VERSION ""

NS_ :

BS_:

BU_: RSM HVAC_RCCM GENERIC_GWMWakeup TRM GWM_ECG _delete RTM PDM SCMH SCMG DDM RBM DSM SCME TSTR

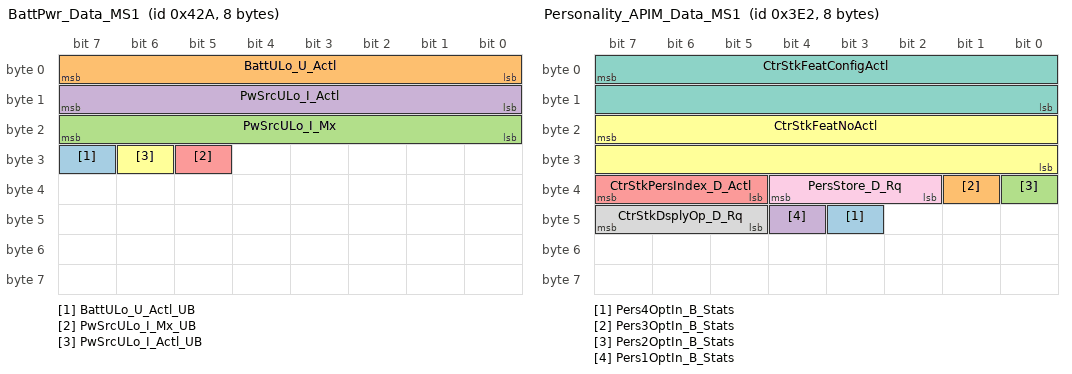
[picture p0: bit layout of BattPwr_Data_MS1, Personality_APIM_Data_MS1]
BO_ 1066 BattPwr_Data_MS1: 8 GWM_ECG
 SG_ BattULo_U_Actl_UB : 31|1@0+ (1,0) [0|1] "SED"  HVAC_RCCM
 SG_ BattULo_U_Actl : 7|8@0+ (0.0625,0) [0|15.875] "volt"  HVAC_RCCM
 SG_ PwSrcULo_I_Mx : 23|8@0+ (1,0) [0|254] "ampere"  HVAC_RCCM
 SG_ PwSrcULo_I_Actl : 15|8@0+ (1,0) [0|254] "ampere"  HVAC_RCCM
 SG_ PwSrcULo_I_Mx_UB : 29|1@0+ (1,0) [0|1] "SED"  HVAC_RCCM
 SG_ PwSrcULo_I_Actl_UB : 30|1@0+ (1,0) [0|1] "SED"  HVAC_RCCM

BO_ 994 Personality_APIM_Data_MS1: 8 GWM_ECG
 SG_ Pers4OptIn_B_Stats : 43|1@0+ (1,0) [0|1] "SED" Vector__XXX
 SG_ Pers3OptIn_B_Stats : 33|1@0+ (1,0) [0|1] "SED" Vector__XXX
 SG_ Pers2OptIn_B_Stats : 32|1@0+ (1,0) [0|1] "SED" Vector__XXX
 SG_ Pers1OptIn_B_Stats : 44|1@0+ (1,0) [0|1] "SED" Vector__XXX
 SG_ CtrStkPersIndex_D_Actl : 39|3@0+ (1,0) [0|7] "SED"  HVAC_RCCM,PDM,DDM,DSM,SCMG,SCMH
 SG_ CtrStkFeatNoActl : 23|16@0+ (1,0) [0|65535] "Undefined"  HVAC_RCCM,PDM,DDM,DSM
 SG_ CtrStkFeatConfigActl : 7|16@0+ (1,0) [0|65535] "Undefined"  HVAC_RCCM,PDM,DDM,DSM
 SG_ CtrStkDsplyOp_D_Rq : 47|3@0+ (1,0) [0|7] "SED"  HVAC_RCCM,PDM,DDM,DSM,SCMG,SCMH
 SG_ PersStore_D_Rq : 36|3@0+ (1,0) [0|7] "SED"  DSM

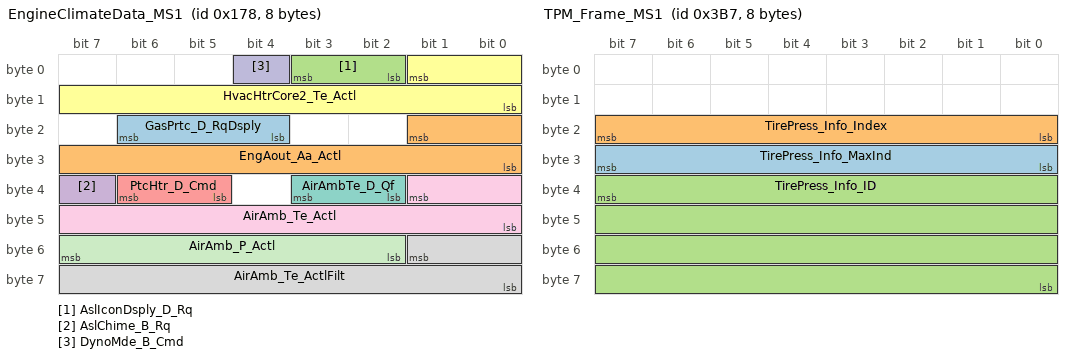
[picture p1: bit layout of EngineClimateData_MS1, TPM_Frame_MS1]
BO_ 376 EngineClimateData_MS1: 8 GWM_ECG
 SG_ GasPrtc_D_RqDsply : 22|3@0+ (1,0) [0|7] "SED" Vector__XXX
 SG_ EngAout_Aa_Actl : 17|10@0+ (0.05,-25.6) [-25.6|25.55] "rpm/ms" Vector__XXX
 SG_ AslIconDsply_D_Rq : 3|2@0+ (1,0) [0|3] "SED" Vector__XXX
 SG_ AslChime_B_Rq : 39|1@0+ (1,0) [0|1] "SED" Vector__XXX
 SG_ PtcHtr_D_Cmd : 38|2@0+ (1,0) [0|3] "SED" Vector__XXX
 SG_ HvacHtrCore2_Te_Actl : 1|10@0+ (0.25,-50) [-50|205.5] "degC"  HVAC_RCCM
 SG_ AirAmbTe_D_Qf : 35|2@0+ (1,0) [0|3] "SED"  HVAC_RCCM
 SG_ AirAmb_Te_ActlFilt : 49|10@0+ (0.25,-128) [-128|127.75] "deg C"  HVAC_RCCM
 SG_ AirAmb_Te_Actl : 33|10@0+ (0.25,-128) [-128|127.75] "degC"  HVAC_RCCM
 SG_ DynoMde_B_Cmd : 4|1@0+ (1,0) [0|1] "SED" Vector__XXX
 SG_ AirAmb_P_Actl : 55|6@0+ (10,500) [500|1110] "mbar" Vector__XXX

BO_ 951 TPM_Frame_MS1: 8 GWM_ECG
 SG_ TirePress_Info_MaxInd : 31|8@0+ (1,0) [0|255] "Unitless"  RTM
 SG_ TirePress_Info_Index : 23|8@0+ (1,0) [0|255] "Unitless"  RTM
 SG_ TirePress_Info_ID : 39|32@0+ (1,0) [0|4294967295] "Unitless"  RTM

BO_ 1068 Batt_Mgmt_Data_MS1: 8 GWM_ECG
 SG_ HvacAirFullOut_B_Rq_UB : 60|1@0+ (1,0) [0|1] "SED"  HVAC_RCCM
 SG_ HvacAirFullOut_B_Rq : 61|1@0+ (1,0) [0|1] "SED"  HVAC_RCCM
 SG_ HvacAirFlw_B_RqBatt_UB : 62|1@0+ (1,0) [0|1] "SED" Vector__XXX
 SG_ HvacRec_D_RqMxBatt_UB : 21|1@0+ (1,0) [0|1] "SED" Vector__XXX
 SG_ HvacRec_D_RqMxBatt : 20|4@0+ (1,0) [0|15] "SED" Vector__XXX
 SG_ Batt_Lo_SoC_B_UB : 22|1@0+ (1,0) [0|1] "SED"  HVAC_RCCM,TRM
 SG_ Batt_Lo_SoC_B : 23|1@0+ (1,0) [0|1] "SED"  HVAC_RCCM,TRM
 SG_ Batt_Crit_SoC_B_UB : 14|1@0+ (1,0) [0|1] "SED"  HVAC_RCCM,TRM
 SG_ Batt_Crit_SoC_B : 15|1@0+ (1,0) [0|1] "SED"  HVAC_RCCM,TRM
 SG_ Shed_T_Eng_Off_B_UB : 12|1@0+ (1,0) [0|1] "SED"  HVAC_RCCM,TRM
 SG_ Shed_T_Eng_Off_B : 13|1@0+ (1,0) [0|1] "SED"  HVAC_RCCM,TRM
 SG_ Shed_Level_Req_UB : 8|1@0+ (1,0) [0|1] "SED"  HVAC_RCCM,DDM,PDM,TRM
 SG_ Shed_Level_Req : 11|3@0+ (1,0) [0|7] "SED"  HVAC_RCCM,DDM,PDM,TRM
 SG_ Shed_Feature_Group_ID_UB : 2|1@0+ (1,0) [0|1] "SED"  HVAC_RCCM,TRM
 SG_ Shed_Feature_Group_ID : 7|5@0+ (1,0) [0|31] "SED"  HVAC_RCCM,TRM
 SG_ Shed_Drain_Eng_Off_B_UB : 0|1@0+ (1,0) [0|1] "SED"  HVAC_RCCM,TRM
 SG_ Shed_Drain_Eng_Off_B : 1|1@0+ (1,0) [0|1] "SED"  HVAC_RCCM,TRM
 SG_ HvacAir_Flw_EstBatt_UB : 16|1@0+ (1,0) [0|1] "SED" Vector__XXX
 SG_ AirCondRec_B_Rq_UB : 44|1@0+ (1,0) [0|1] "SED"  HVAC_RCCM
 SG_ AirCondFluidHi_P_Actl_UB : 45|1@0+ (1,0) [0|1] "SED"  HVAC_RCCM
 SG_ AirCondClutch_B_Stats_UB : 43|1@0+ (1,0) [0|1] "SED"  HVAC_RCCM
 SG_ AirCondRec_B_Rq : 47|1@0+ (1,0) [0|1] "SED"  HVAC_RCCM
 SG_ AirCondFluidHi_P_Actl : 39|8@0+ (0.125,0) [0|31.625] "bar"  HVAC_RCCM
 SG_ AirCondClutch_B_Stats : 46|1@0+ (1,0) [0|1] "SED"  HVAC_RCCM

BO_ 963 BCM_Lamp_Stat_MS1: 8 GWM_ECG
 SG_ Illuminated_Entry_Stat : 63|2@0+ (1,0) [0|3] "SED" Vector__XXX
 SG_ Dr_Courtesy_Light_Stat : 49|2@0+ (1,0) [0|3] "SED" Vector__XXX
 SG_ ImpactEvntFdbck_D_Stat : 53|2@0+ (1,0) [0|3] "SED" Vector__XXX
 SG_ PudLampPsngr_D_Rq : 57|2@0+ (1,0) [0|3] "SED"  PDM
 SG_ HeadLampLoOut_B_Stat : 32|1@0+ (1,0) [0|1] "SED" Vector__XXX
 SG_ CrnrLghtRight_Pc_Rq : 47|7@0+ (1,0) [0|100] "percent" Vector__XXX
 SG_ CrnrLghtLeft_Pc_Rq : 39|7@0+ (1,0) [0|100] "percent" Vector__XXX
 SG_ HeadLghtHiFdbck_D_Stat : 55|2@0+ (1,0) [0|3] "SED" Vector__XXX
 SG_ PrkLightChime_B_Rq : 25|1@0+ (1,0) [0|1] "SED" Vector__XXX
 SG_ TrnNotInPrkChime_B_Rq : 24|1@0+ (1,0) [0|1] "SED" Vector__XXX
 SG_ HomeSafeLtChime_B_Rq : 28|1@0+ (1,0) [0|1] "SED" Vector__XXX
 SG_ StopLghtOn_B_Stat : 8|1@0+ (1,0) [0|1] "SED"  RSM,TRM
 SG_ RvrseLghtOn_B_Stat : 9|1@0+ (1,0) [0|1] "SED"  TRM
 SG_ PrkLght_D_Stat : 13|2@0+ (1,0) [0|3] "SED"  TRM
 SG_ HeadLghtSwtch_D_Stat : 15|2@0+ (1,0) [0|3] "SED" Vector__XXX
 SG_ KeyInIgnWarn_B_Cmd : 27|1@0+ (1,0) [0|1] "SED" Vector__XXX
 SG_ HeadLampLoFrOn_B_Stat : 2|1@0+ (1,0) [0|1] "SED" Vector__XXX
 SG_ HeadLampLoFlOn_B_Stat : 3|1@0+ (1,0) [0|1] "SED" Vector__XXX
 SG_ Headlamp_On_Wrning_Cmd : 29|1@0+ (1,0) [0|1] "SED" Vector__XXX
 SG_ HeadLampLoActv_B_Stat : 4|1@0+ (1,0) [0|1] "SED" Vector__XXX
 SG_ HeadLghtHiOn_B_Stat : 1|1@0+ (1,0) [0|1] "SED" Vector__XXX
 SG_ Park_Brake_Chime_Rqst : 26|1@0+ (1,0) [0|1] "SED" Vector__XXX
 SG_ BrkWarnInd_B_Rq : 20|1@0+ (1,0) [0|1] "SED" Vector__XXX
 SG_ Brk_Fluid_Lvl_Low : 31|2@0+ (1,0) [0|3] "SED" Vector__XXX
 SG_ ReducedGuard_D_Stat : 19|2@0+ (1,0) [0|3] "SED" Vector__XXX
 SG_ Courtesy_BSave_Stat : 7|2@0+ (1,0) [0|3] "SED"  DDM,PDM
 SG_ DayRnngLampOn_B_Stat : 5|1@0+ (1,0) [0|1] "SED" Vector__XXX
 SG_ PerimeterAlarmChimeRq : 0|1@0+ (1,0) [0|1] "SED" Vector__XXX
 SG_ PudLampDrv_D_Rq : 59|2@0+ (1,0) [0|3] "SED"  DDM
 SG_ Courtesy_Delay_Status : 51|2@0+ (1,0) [0|3] "SED" Vector__XXX
 SG_ Perimeter_Alarm_Status : 17|2@0+ (1,0) [0|3] "SED"  RSM
 SG_ WndwGlbl_D_Cmd : 23|3@0+ (1,0) [0|7] "SED"  DDM,PDM
 SG_ PudLamp_D_Rq : 11|2@0+ (1,0) [0|3] "SED"  DDM,PDM

BO_ 964 BodyInfo_MS1: 8 GWM_ECG
 SG_ FohEng_D_Rq_UB : 60|1@0+ (1,0) [0|1] "SED" Vector__XXX
 SG_ EcoMode_B_Stat_UB : 56|1@0+ (1,0) [0|1] "SED" Vector__XXX
 SG_ Cta_D_Rq_UB : 57|1@0+ (1,0) [0|1] "SED" Vector__XXX
 SG_ Cta_D_Rq : 59|2@0+ (1,0) [0|3] "SED" Vector__XXX
 SG_ GearRvrse_D_Actl_UB : 48|1@0+ (1,0) [0|1] "SED"  PDM,DDM
 SG_ GearRvrse_D_Actl : 51|3@0+ (1,0) [0|7] "SED"  PDM,DDM
 SG_ TurnLghtSwtch_D_Stat_UB : 52|1@0+ (1,0) [0|1] "SED" Vector__XXX
 SG_ TurnLghtSwtch_D_Stat : 54|2@0+ (1,0) [0|3] "SED" Vector__XXX
 SG_ Power_Liftgate_Mode_Cmd_UB : 6|1@0+ (1,0) [0|1] "SED" Vector__XXX
 SG_ Power_Liftgate_Mode_Cmd : 7|1@0+ (1,0) [0|1] "SED" Vector__XXX
 SG_ MetricActvTe_B_Actl_UB : 2|1@0+ (1,0) [0|1] "SED"  HVAC_RCCM
 SG_ MetricActvTe_B_Actl : 3|1@0+ (1,0) [0|1] "SED"  HVAC_RCCM
 SG_ EngClntTe_D_Qf : 22|2@0+ (1,0) [0|3] "SED"  HVAC_RCCM
 SG_ Sod_D_Rq : 1|2@0+ (1,0) [0|3] "SED" Vector__XXX
 SG_ MetricActv_B_Actl : 5|1@0+ (1,0) [0|1] "SED"  HVAC_RCCM
 SG_ EngClnt_Te_Actl : 15|8@0+ (1,-60) [-60|195] "degC"  HVAC_RCCM
 SG_ MetricActv_B_Actl_UB : 4|1@0+ (1,0) [0|1] "SED"  HVAC_RCCM
 SG_ EngClnt_Te_Actl_UB : 23|1@0+ (1,0) [0|1] "SED"  HVAC_RCCM
 SG_ OCSSensrDataUpperLim_UB : 28|1@0+ (1,0) [0|1] "SED"  HVAC_RCCM,SCMG,SCMH
 SG_ OCSSensrDataUpperLim : 47|8@0+ (1,0) [0|254] "SED"  HVAC_RCCM,SCMG,SCMH
 SG_ OCSSensrDataLowerLim_UB : 29|1@0+ (1,0) [0|1] "SED"  HVAC_RCCM,SCMG,SCMH
 SG_ PrkAid_D_Falt : 18|3@0+ (1,0) [0|7] "SED" Vector__XXX
 SG_ OCSSensrDataLowerLim : 39|8@0+ (1,0) [0|254] "SED"  HVAC_RCCM,SCMG,SCMH
 SG_ PrkAid_D_Falt_UB : 63|1@0+ (1,0) [0|1] "SED" Vector__XXX
 SG_ WiprFront_D_Stat_UB : 55|1@0+ (1,0) [0|1] "SED"  HVAC_RCCM
 SG_ WiprFront_D_Stat : 27|4@0+ (1,0) [0|15] "SED"  HVAC_RCCM
 SG_ CamraDefog_B_Req_UB : 30|1@0+ (1,0) [0|1] "SED" Vector__XXX
 SG_ Sod_D_Rq_UB : 19|1@0+ (1,0) [0|1] "SED" Vector__XXX
 SG_ CamraDefog_B_Req : 31|1@0+ (1,0) [0|1] "SED" Vector__XXX

BO_ 1843 TesterPhysicalReqHVAC_RCCM: 8 TSTR
 SG_ TesterPhysicalReqHVAC_RCCM : 7|64@0+ (1,0) [0|1.84467E+019] "unitless"  HVAC_RCCM

BO_ 1851 TesterPhysicalResHVAC_RCCM: 8 HVAC_RCCM
 SG_ TesterPhysicalResHVAC_RCCM : 7|64@0+ (1,0) [0|1.84467E+019] "unitless"  TSTR

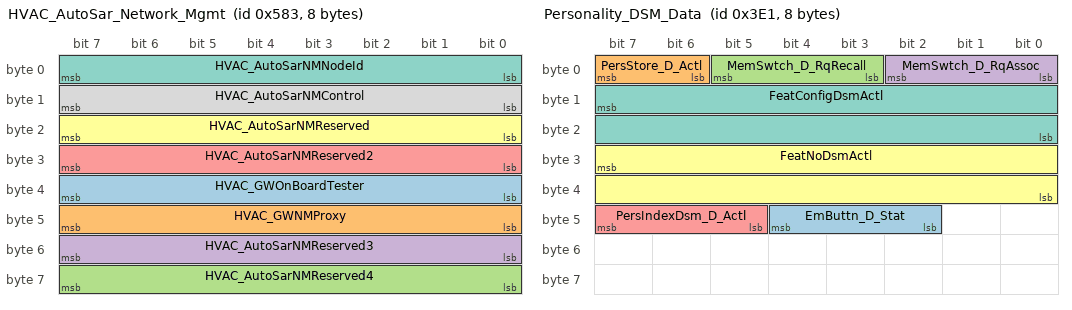
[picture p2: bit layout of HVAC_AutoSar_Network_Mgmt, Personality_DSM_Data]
BO_ 1411 HVAC_AutoSar_Network_Mgmt: 8 HVAC_RCCM
 SG_ HVAC_GWOnBoardTester : 39|8@0+ (1,0) [0|255] "unitless"  GWM_ECG
 SG_ HVAC_GWNMProxy : 47|8@0+ (1,0) [0|255] "unitless"  GWM_ECG
 SG_ HVAC_AutoSarNMReserved4 : 63|8@0+ (1,0) [0|255] "unitless"  GWM_ECG
 SG_ HVAC_AutoSarNMReserved3 : 55|8@0+ (1,0) [0|255] "unitless"  GWM_ECG
 SG_ HVAC_AutoSarNMReserved2 : 31|8@0+ (1,0) [0|255] "unitless"  GWM_ECG
 SG_ HVAC_AutoSarNMReserved : 23|8@0+ (1,0) [0|255] "unitless"  GWM_ECG
 SG_ HVAC_AutoSarNMNodeId : 7|8@0+ (1,0) [0|255] "unitless"  GWM_ECG
 SG_ HVAC_AutoSarNMControl : 15|8@0+ (1,0) [0|255] "unitless"  GWM_ECG

BO_ 993 Personality_DSM_Data: 8 DSM
 SG_ EmButtn_D_Stat : 44|3@0+ (1,0) [0|7] "SED"  GWM_ECG
 SG_ PersStore_D_Actl : 7|2@0+ (1,0) [0|3] "SED"  GWM_ECG
 SG_ MemSwtch_D_RqRecall : 5|3@0+ (1,0) [0|7] "SED"  GWM_ECG
 SG_ MemSwtch_D_RqAssoc : 2|3@0+ (1,0) [0|7] "SED"  GWM_ECG
 SG_ PersIndexDsm_D_Actl : 47|3@0+ (1,0) [0|7] "SED"  GWM_ECG
 SG_ FeatNoDsmActl : 31|16@0+ (1,0) [0|65535] "Number"  GWM_ECG
 SG_ FeatConfigDsmActl : 15|16@0+ (1,0) [0|65535] "Undefined"  GWM_ECG

BO_ 1881 TesterPhysicalResRTM: 8 RTM
 SG_ TesterPhysicalResRTM : 7|64@0+ (1,0) [0|1.84467E+019] "unitless"  TSTR

BO_ 1873 TesterPhysicalReqRTM: 8 TSTR
 SG_ TesterPhysicalReqRTM : 7|64@0+ (1,0) [0|1.84467E+019] "unitless"  RTM

BO_ 2015 TesterFunctionalReq_M1: 8 TSTR
 SG_ TesterFunctionalReq : 7|64@0+ (1,0) [0|1.84467E+019] ""  RSM,HVAC_RCCM,TSTR,PDM,SCMG,SCMH,TRM,RTM,GWM_ECG,DDM,DSM,RBM,SCME

BO_ 320 LPwrSlideDr_Stat: 8 GENERIC_GWMWakeup
 SG_ PwSldDrIntSwL_B_Stat : 6|1@0+ (1,0) [0|1] "SED"  GWM_ECG
 SG_ LPwrSlideDr_Unlock_Rq : 7|1@0+ (1,0) [0|1] "SED"  GWM_ECG

BO_ 313 RPwrSlideDr_Stat: 8 GENERIC_GWMWakeup
 SG_ PwSldDrIntSwR_B_Stat : 6|1@0+ (1,0) [0|1] "SED"  GWM_ECG
 SG_ RPwrSlideDr_Unlock_Rq : 7|1@0+ (1,0) [0|1] "SED"  GWM_ECG

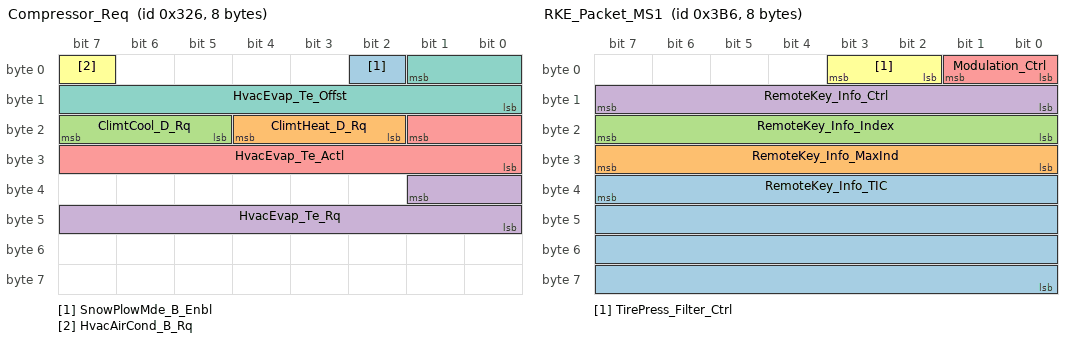
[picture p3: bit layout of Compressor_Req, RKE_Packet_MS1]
BO_ 806 Compressor_Req: 8 HVAC_RCCM
 SG_ SnowPlowMde_B_Enbl : 2|1@0+ (1,0) [0|1] "SED"  GWM_ECG,SCMG,SCMH
 SG_ ClimtHeat_D_Rq : 20|3@0+ (1,0) [0|7] "SED"  GWM_ECG
 SG_ ClimtCool_D_Rq : 23|3@0+ (1,0) [0|7] "SED"  GWM_ECG
 SG_ HvacEvap_Te_Rq : 33|10@0+ (0.125,-50) [-50|77.875] "Degrees C"  GWM_ECG
 SG_ HvacEvap_Te_Actl : 17|10@0+ (0.125,-50) [-50|77.75] "Degrees C"  GWM_ECG
 SG_ HvacAirCond_B_Rq : 7|1@0+ (1,0) [0|1] "SED"  GWM_ECG
 SG_ HvacEvap_Te_Offst : 1|10@0+ (0.125,-50) [-50|77.875] "Degrees C"  GWM_ECG

BO_ 950 RKE_Packet_MS1: 8 GWM_ECG
 SG_ RemoteKey_Info_TIC : 39|32@0+ (1,0) [0|4294967295] "Unitless"  RTM
 SG_ RemoteKey_Info_MaxInd : 31|8@0+ (1,0) [0|255] "Unitless"  RTM
 SG_ RemoteKey_Info_Index : 23|8@0+ (1,0) [0|255] "Unitless"  RTM
 SG_ RemoteKey_Info_Ctrl : 15|8@0+ (1,0) [0|255] "Unitless" Vector__XXX
 SG_ Modulation_Ctrl : 1|2@0+ (1,0) [0|3] "SED" Vector__XXX
 SG_ TirePress_Filter_Ctrl : 3|2@0+ (1,0) [0|3] "SED"  RTM

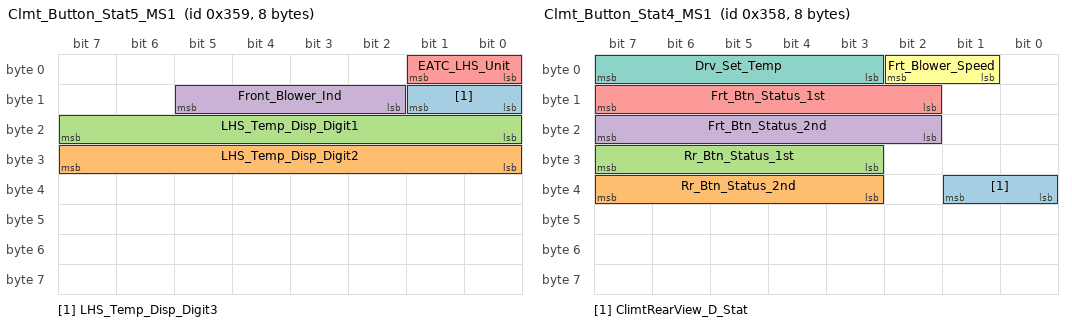
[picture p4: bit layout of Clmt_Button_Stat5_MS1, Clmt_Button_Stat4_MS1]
BO_ 857 Clmt_Button_Stat5_MS1: 8 GWM_ECG
 SG_ LHS_Temp_Disp_Digit3 : 9|2@0+ (1,0) [0|3] "SED"  HVAC_RCCM
 SG_ LHS_Temp_Disp_Digit2 : 31|8@0+ (1,0) [0|255] "ASCII"  HVAC_RCCM
 SG_ LHS_Temp_Disp_Digit1 : 23|8@0+ (1,0) [0|255] "ASCII"  HVAC_RCCM
 SG_ Front_Blower_Ind : 13|4@0+ (1,0) [0|15] "SED"  HVAC_RCCM
 SG_ EATC_LHS_Unit : 1|2@0+ (1,0) [0|3] "SED"  HVAC_RCCM

BO_ 856 Clmt_Button_Stat4_MS1: 8 GWM_ECG
 SG_ ClimtRearView_D_Stat : 33|2@0+ (1,0) [0|3] "SED" Vector__XXX
 SG_ Rr_Btn_Status_2nd : 39|5@0+ (1,0) [0|31] "SED" Vector__XXX
 SG_ Rr_Btn_Status_1st : 31|5@0+ (1,0) [0|31] "SED" Vector__XXX
 SG_ Frt_Btn_Status_2nd : 23|6@0+ (1,0) [0|63] "SED"  HVAC_RCCM
 SG_ Frt_Btn_Status_1st : 15|6@0+ (1,0) [0|63] "SED"  HVAC_RCCM
 SG_ Frt_Blower_Speed : 2|2@0+ (1,0) [0|3] "SED"  HVAC_RCCM
 SG_ Drv_Set_Temp : 7|5@0+ (1,0) [0|31] "SED"  HVAC_RCCM

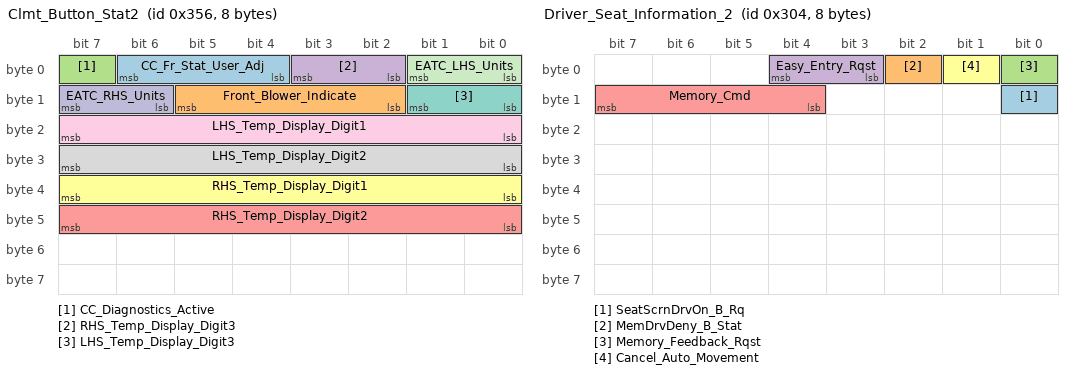
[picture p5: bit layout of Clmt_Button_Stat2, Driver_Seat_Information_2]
BO_ 854 Clmt_Button_Stat2: 8 HVAC_RCCM
 SG_ CC_Fr_Stat_User_Adj : 6|3@0+ (1,0) [0|7] "SED"  GWM_ECG
 SG_ Front_Blower_Indicate : 13|4@0+ (1,0) [0|15] "SED"  GWM_ECG
 SG_ CC_Diagnostics_Active : 7|1@0+ (1,0) [0|1] "SED"  GWM_ECG
 SG_ RHS_Temp_Display_Digit3 : 3|2@0+ (1,0) [0|3] "SED"  GWM_ECG
 SG_ RHS_Temp_Display_Digit2 : 47|8@0+ (1,0) [0|255] "ASCII"  GWM_ECG
 SG_ RHS_Temp_Display_Digit1 : 39|8@0+ (1,0) [0|255] "ASCII"  GWM_ECG
 SG_ LHS_Temp_Display_Digit3 : 9|2@0+ (1,0) [0|3] "SED"  GWM_ECG
 SG_ LHS_Temp_Display_Digit2 : 31|8@0+ (1,0) [0|255] "ASCII"  GWM_ECG
 SG_ LHS_Temp_Display_Digit1 : 23|8@0+ (1,0) [0|255] "ASCII"  GWM_ECG
 SG_ EATC_RHS_Units : 15|2@0+ (1,0) [0|3] "SED"  GWM_ECG
 SG_ EATC_LHS_Units : 1|2@0+ (1,0) [0|3] "SED"  GWM_ECG

BO_ 772 Driver_Seat_Information_2: 8 DSM
 SG_ SeatScrnDrvOn_B_Rq : 8|1@0+ (1,0) [0|1] "SED"  GWM_ECG
 SG_ MemDrvDeny_B_Stat : 2|1@0+ (1,0) [0|1] "SED"  GWM_ECG
 SG_ Memory_Feedback_Rqst : 0|1@0+ (1,0) [0|1] "SED"  GWM_ECG
 SG_ Easy_Entry_Rqst : 4|2@0+ (1,0) [0|3] "SED"  GWM_ECG,SCMH,SCMG
 SG_ Memory_Cmd : 15|4@0+ (1,0) [0|15] "SED"  GWM_ECG,SCMH,DDM,PDM,SCMG
 SG_ Cancel_Auto_Movement : 1|1@0+ (1,0) [0|1] "SED"  GWM_ECG,SCMH,PDM,DDM,SCMG

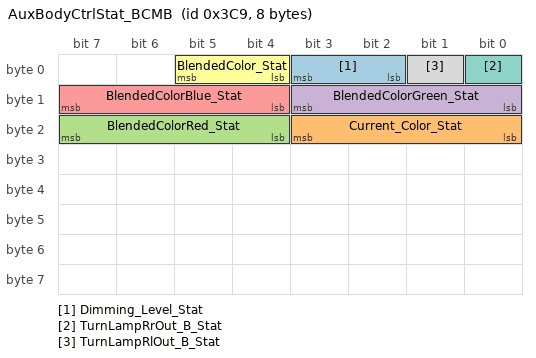
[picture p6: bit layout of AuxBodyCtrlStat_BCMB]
BO_ 969 AuxBodyCtrlStat_BCMB: 8 GENERIC_GWMWakeup
 SG_ Dimming_Level_Stat : 3|2@0+ (1,0) [0|3] "SED"  GWM_ECG
 SG_ Current_Color_Stat : 19|4@0+ (1,0) [0|15] "SED"  GWM_ECG
 SG_ BlendedColorRed_Stat : 23|4@0+ (1,0) [0|15] "SED"  GWM_ECG
 SG_ BlendedColorGreen_Stat : 11|4@0+ (1,0) [0|15] "SED"  GWM_ECG
 SG_ BlendedColorBlue_Stat : 15|4@0+ (1,0) [0|15] "SED"  GWM_ECG
 SG_ BlendedColor_Stat : 5|2@0+ (1,0) [0|3] "SED"  GWM_ECG
 SG_ TurnLampRrOut_B_Stat : 0|1@0+ (1,0) [0|1] "SED"  GWM_ECG
 SG_ TurnLampRlOut_B_Stat : 1|1@0+ (1,0) [0|1] "SED"  GWM_ECG

CM_ SG_ 376 EngAout_Aa_Actl "Signal not transmitted on HEV variants.";
CM_ SG_ 1068 AirCondRec_B_Rq "Signal not transmitted on diesel variants.";
CM_ SG_ 1068 AirCondClutch_B_Stats "Signal not transmitted on diesel variants.";
CM_ SG_ 964 GearRvrse_D_Actl "Do not implement GearRvrse_D_Actl  until eTracker 8804151 is approved, 11/24/09";
CM_ SG_ 964 MetricActv_B_Actl "0 =Inactive(English), 1=Active(Metric)";
CM_ BO_ 2015 "OBDII Request ($7DF) messages are for FNOS 1.0.1 only.
Diagnostic Functional Addressing ($7DF) and Dual Rate Periodic messages are for FNOS I3 only.";
CM_ SG_ 320 PwSldDrIntSwL_B_Stat "Signal not transmitted on vehicles without power sliding doors.";
CM_ SG_ 320 LPwrSlideDr_Unlock_Rq "Signal not transmitted on vehicles without power sliding doors.";
CM_ SG_ 313 PwSldDrIntSwR_B_Stat "Signal not transmitted on vehicles without power sliding doors.";
CM_ SG_ 313 RPwrSlideDr_Unlock_Rq "Signal not transmitted on vehicles without power sliding doors.";
CM_ SG_ 857 LHS_Temp_Disp_Digit3 "Added for MY 08";
CM_ SG_ 857 LHS_Temp_Disp_Digit2 "Added for MY 08";
CM_ SG_ 857 LHS_Temp_Disp_Digit1 "Added for MY 08";
CM_ SG_ 857 EATC_LHS_Unit "Added for MY 08";
CM_ SG_ 854 RHS_Temp_Display_Digit3 "Added for MY 08";
CM_ SG_ 854 RHS_Temp_Display_Digit2 "Added for MY 08";
CM_ SG_ 854 RHS_Temp_Display_Digit1 "Added for MY 08";
CM_ SG_ 854 LHS_Temp_Display_Digit3 "Added for MY 08";
CM_ SG_ 854 LHS_Temp_Display_Digit2 "Added for MY 08";
CM_ SG_ 854 LHS_Temp_Display_Digit1 "Added for MY 08";
CM_ SG_ 854 EATC_RHS_Units "Added for MY 08";
CM_ SG_ 854 EATC_LHS_Units "Added for MY 08";
CM_ SG_ 772 Memory_Feedback_Rqst "Updated to 1 bit for CGEA, Not backwards compatible";
CM_ SG_ 969 TurnLampRrOut_B_Stat "Signal not transmitted on vehicles without a BCMB module.";
CM_ SG_ 969 TurnLampRlOut_B_Stat "Signal not transmitted on vehicles without a BCMB module.";
BA_DEF_ BO_  "FrameGatewayNetwork" STRING ;
BA_DEF_ BO_  "FrameGatewayMS1" HEX 0 1407;
BA_DEF_ BO_  "FrameGatewayHS3" HEX 0 1407;
BA_DEF_ BO_  "FrameGatewayHS1" HEX 0 1407;
BA_DEF_ BO_  "NetworkInitialization" ENUM  "No","Yes";
BA_DEF_ BO_  "FrameGatewayId" HEX 0 1407;
BA_DEF_ BO_  "EventRateOfChange" INT 10 10000;
BA_DEF_ BO_  "GenMsgStartDelayTime" INT 0 10000;
BA_DEF_ BO_  "GenMsgNrOfRepetition" INT 0 100;
BA_DEF_ BO_  "GenMsgDelayTime" INT 0 1000;
BA_DEF_ BO_  "GenMsgCycleTime" INT 0 100000;
BA_DEF_ BO_  "GenMsgSendType" ENUM  "FixedPeriodic","Event","EnabledPeriodic","NotUsed","NotUsed","EventPeriodic","NotUsed","NotUsed","NoMsgSendType";
BA_DEF_ SG_  "U_P702_MY2021_Tx" ENUM  "No","Yes";
BA_DEF_ SG_  "U_CX727_MY2021_Tx" ENUM  "No","Yes";
BA_DEF_ SG_  "U_VN127_MY20_Tx" ENUM  "No","Yes";
BA_DEF_ SG_  "U_H567_MY20_Tx" ENUM  "No","Yes";
BA_DEF_ SG_  "U_CX430_MY2021_Tx" ENUM  "No","Yes";
BA_DEF_ SG_  "U_U611_U625_MY20_Phev_Tx" ENUM  "No","Yes";
BA_DEF_ SG_  "U_B562_MY18_Diesel_Tx" ENUM  "No","Yes";
BA_DEF_ SG_  "U_CX482_CX483_MY20_Tx" ENUM  "No","Yes";
BA_DEF_ SG_  "U_U611_U625_MY20_Hev_Tx" ENUM  "No","Yes";
BA_DEF_ SG_  "U_U611_U625_MY20_Gas_Tx" ENUM  "No","Yes";
BA_DEF_ SG_  "U_B500_MY18_Diesel_Tx" ENUM  "No","Yes";
BA_DEF_ SG_  "U_B500_MY18_Gas_Tx" ENUM  "No","Yes";
BA_DEF_ SG_  "U_C490_MY18_Tx" ENUM  "No","Yes";
BA_DEF_ SG_  "U_B562_MY18_Gas_Tx" ENUM  "No","Yes";
BA_DEF_ SG_  "U_C519_MY18_5_Gas_Tx" ENUM  "No","Yes";
BA_DEF_ SG_  "U_C519_MY18_5_Diesel_Tx" ENUM  "No","Yes";
BA_DEF_ SG_  "U_B515_MCA_MY17_Gas_Tx" ENUM  "No","Yes";
BA_DEF_ SG_  "U_B515_MCA_MY17_Diesel_Tx" ENUM  "No","Yes";
BA_DEF_ SG_  "U_B479_MY17_Diesel_Tx" ENUM  "No","Yes";
BA_DEF_ SG_  "U_B479_MY17_Gas_Tx" ENUM  "No","Yes";
BA_DEF_ SG_  "U_P702_MY2021_Rx" ENUM  "No","Yes";
BA_DEF_ SG_  "U_CX727_MY2021_Rx" ENUM  "No","Yes";
BA_DEF_ SG_  "U_VN127_MY20_Rx" ENUM  "No","Yes";
BA_DEF_ SG_  "U_H567_MY20_Rx" ENUM  "No","Yes";
BA_DEF_ SG_  "U_CX430_MY2021_Rx" ENUM  "No","Yes";
BA_DEF_ SG_  "U_U611_U625_MY20_Phev_Rx" ENUM  "No","Yes";
BA_DEF_ SG_  "U_B562_MY18_Diesel_Rx" ENUM  "No","Yes";
BA_DEF_ SG_  "U_CX482_CX483_MY20_Rx" ENUM  "No","Yes";
BA_DEF_ SG_  "U_U611_U625_MY20_Hev_Rx" ENUM  "No","Yes";
BA_DEF_ SG_  "U_U611_U625_MY20_Gas_Rx" ENUM  "No","Yes";
BA_DEF_ SG_  "U_B500_MY18_Diesel_Rx" ENUM  "No","Yes";
BA_DEF_ SG_  "U_B500_MY18_Gas_Rx" ENUM  "No","Yes";
BA_DEF_ SG_  "U_C490_MY18_Rx" ENUM  "No","Yes";
BA_DEF_ SG_  "U_B562_MY18_Gas_Rx" ENUM  "No","Yes";
BA_DEF_ SG_  "U_C519_MY18_5_Gas_Rx" ENUM  "No","Yes";
BA_DEF_ SG_  "U_C519_MY18_5_Diesel_Rx" ENUM  "No","Yes";
BA_DEF_ SG_  "U_B515_MCA_MY17_Gas_Rx" ENUM  "No","Yes";
BA_DEF_ SG_  "U_B515_MCA_MY17_Diesel_Rx" ENUM  "No","Yes";
BA_DEF_ SG_  "U_B479_MY17_Diesel_Rx" ENUM  "No","Yes";
BA_DEF_ SG_  "U_B479_MY17_Gas_Rx" ENUM  "No","Yes";
BA_DEF_ SG_  "U_B562LC_MY15_Gas_Rx" ENUM  "No","Yes";
BA_DEF_ SG_  "U_B562LC_MY15_Diesel_Rx" ENUM  "No","Yes";
BA_DEF_ SG_  "MetaData" ENUM  "No","Yes";
BA_DEF_ SG_  "ContentDependant" ENUM  "No","Yes";
BA_DEF_ SG_  "GenSigStartValue" INT 0 1000000000;
BA_DEF_ SG_  "UsedOnPgmDBC" ENUM  "No","Yes";
BA_DEF_ SG_  "CrossOver_InfoCAN" ENUM  "No","Yes";
BA_DEF_ SG_  "WakeupSignal" ENUM  "No","Yes";
BA_DEF_ SG_  "GenSigInactiveValue" INT 0 100000;
BA_DEF_ SG_  "GenSigSendType" ENUM  "Cyclic","OnWrite","vector_leerstring","OnChange","vector_leerstring","IfActive","vector_leerstring","NoSigSendType";
BA_DEF_ BO_  "AuthFreshnessCounterSyncAttempt" INT 0 2;
BA_DEF_ BO_  "GenMsgRoutingTimeoutTime" INT 0 5000;
BA_DEF_ BO_  "MessageGateway" ENUM  "No","Yes";
BA_DEF_ BO_  "NmAsrMessage" ENUM  "No","Yes";
BA_DEF_ BO_  "DiagState" ENUM  "No","Yes";
BA_DEF_ BO_  "DiagRequest" ENUM  "No","Yes";
BA_DEF_ BO_  "DiagResponse" ENUM  "No","Yes";
BA_DEF_ BO_  "NmMessage" ENUM  "No","Yes";
BA_DEF_ BO_  "GenMsgILSupport" ENUM  "No","Yes";
BA_DEF_DEF_  "FrameGatewayNetwork" "NONE";
BA_DEF_DEF_  "FrameGatewayMS1" 0;
BA_DEF_DEF_  "FrameGatewayHS3" 0;
BA_DEF_DEF_  "FrameGatewayHS1" 0;
BA_DEF_DEF_  "NetworkInitialization" "Yes";
BA_DEF_DEF_  "FrameGatewayId" 0;
BA_DEF_DEF_  "EventRateOfChange" 10000;
BA_DEF_DEF_  "GenMsgStartDelayTime" 0;
BA_DEF_DEF_  "GenMsgNrOfRepetition" 1;
BA_DEF_DEF_  "GenMsgDelayTime" 20;
BA_DEF_DEF_  "GenMsgCycleTime" 0;
BA_DEF_DEF_  "GenMsgSendType" "NoMsgSendType";
BA_DEF_DEF_  "U_P702_MY2021_Tx" "No";
BA_DEF_DEF_  "U_CX727_MY2021_Tx" "No";
BA_DEF_DEF_  "U_VN127_MY20_Tx" "No";
BA_DEF_DEF_  "U_H567_MY20_Tx" "No";
BA_DEF_DEF_  "U_CX430_MY2021_Tx" "No";
BA_DEF_DEF_  "U_U611_U625_MY20_Phev_Tx" "No";
BA_DEF_DEF_  "U_B562_MY18_Diesel_Tx" "No";
BA_DEF_DEF_  "U_CX482_CX483_MY20_Tx" "No";
BA_DEF_DEF_  "U_U611_U625_MY20_Hev_Tx" "No";
BA_DEF_DEF_  "U_U611_U625_MY20_Gas_Tx" "No";
BA_DEF_DEF_  "U_B500_MY18_Diesel_Tx" "No";
BA_DEF_DEF_  "U_B500_MY18_Gas_Tx" "No";
BA_DEF_DEF_  "U_C490_MY18_Tx" "No";
BA_DEF_DEF_  "U_B562_MY18_Gas_Tx" "No";
BA_DEF_DEF_  "U_C519_MY18_5_Gas_Tx" "No";
BA_DEF_DEF_  "U_C519_MY18_5_Diesel_Tx" "No";
BA_DEF_DEF_  "U_B515_MCA_MY17_Gas_Tx" "No";
BA_DEF_DEF_  "U_B515_MCA_MY17_Diesel_Tx" "No";
BA_DEF_DEF_  "U_B479_MY17_Diesel_Tx" "No";
BA_DEF_DEF_  "U_B479_MY17_Gas_Tx" "No";
BA_DEF_DEF_  "U_P702_MY2021_Rx" "No";
BA_DEF_DEF_  "U_CX727_MY2021_Rx" "No";
BA_DEF_DEF_  "U_VN127_MY20_Rx" "No";
BA_DEF_DEF_  "U_H567_MY20_Rx" "No";
BA_DEF_DEF_  "U_CX430_MY2021_Rx" "No";
BA_DEF_DEF_  "U_U611_U625_MY20_Phev_Rx" "No";
BA_DEF_DEF_  "U_B562_MY18_Diesel_Rx" "No";
BA_DEF_DEF_  "U_CX482_CX483_MY20_Rx" "No";
BA_DEF_DEF_  "U_U611_U625_MY20_Hev_Rx" "No";
BA_DEF_DEF_  "U_U611_U625_MY20_Gas_Rx" "No";
BA_DEF_DEF_  "U_B500_MY18_Diesel_Rx" "No";
BA_DEF_DEF_  "U_B500_MY18_Gas_Rx" "No";
BA_DEF_DEF_  "U_C490_MY18_Rx" "No";
BA_DEF_DEF_  "U_B562_MY18_Gas_Rx" "No";
BA_DEF_DEF_  "U_C519_MY18_5_Gas_Rx" "No";
BA_DEF_DEF_  "U_C519_MY18_5_Diesel_Rx" "No";
BA_DEF_DEF_  "U_B515_MCA_MY17_Gas_Rx" "No";
BA_DEF_DEF_  "U_B515_MCA_MY17_Diesel_Rx" "No";
BA_DEF_DEF_  "U_B479_MY17_Diesel_Rx" "No";
BA_DEF_DEF_  "U_B479_MY17_Gas_Rx" "No";
BA_DEF_DEF_  "U_B562LC_MY15_Gas_Rx" "No";
BA_DEF_DEF_  "U_B562LC_MY15_Diesel_Rx" "No";
BA_DEF_DEF_  "MetaData" "No";
BA_DEF_DEF_  "ContentDependant" "No";
BA_DEF_DEF_  "GenSigStartValue" 0;
BA_DEF_DEF_  "UsedOnPgmDBC" "Yes";
BA_DEF_DEF_  "CrossOver_InfoCAN" "No";
BA_DEF_DEF_  "WakeupSignal" "No";
BA_DEF_DEF_  "GenSigInactiveValue" 0;
BA_DEF_DEF_  "GenSigSendType" "NoSigSendType";
BA_DEF_DEF_  "AuthFreshnessCounterSyncAttempt" 2;
BA_DEF_DEF_  "GenMsgRoutingTimeoutTime" 0;
BA_DEF_DEF_  "MessageGateway" "No";
BA_DEF_DEF_  "NmAsrMessage" "No";
BA_DEF_DEF_  "DiagState" "No";
BA_DEF_DEF_  "DiagRequest" "No";
BA_DEF_DEF_  "DiagResponse" "No";
BA_DEF_DEF_  "NmMessage" "No";
BA_DEF_DEF_  "GenMsgILSupport" "Yes";
BA_ "GenMsgCycleTime" BO_ 1066 50;
BA_ "GenMsgSendType" BO_ 1066 0;
BA_ "FrameGatewayHS3" BO_ 994 987;
BA_ "FrameGatewayHS1" BO_ 994 994;
BA_ "FrameGatewayNetwork" BO_ 376 "FD1_CAN";
BA_ "FrameGatewayId" BO_ 376 376;
BA_ "FrameGatewayNetwork" BO_ 951 "HS1_CAN";
BA_ "FrameGatewayId" BO_ 951 951;
BA_ "GenMsgCycleTime" BO_ 1068 50;
BA_ "GenMsgSendType" BO_ 1068 0;
BA_ "FrameGatewayNetwork" BO_ 963 "HS1_CAN";
BA_ "FrameGatewayId" BO_ 963 963;
BA_ "GenMsgCycleTime" BO_ 964 200;
BA_ "GenMsgSendType" BO_ 964 5;
BA_ "NetworkInitialization" BO_ 1843 0;
BA_ "GenMsgDelayTime" BO_ 1843 0;
BA_ "GenMsgSendType" BO_ 1843 1;
BA_ "DiagRequest" BO_ 1843 1;
BA_ "GenMsgILSupport" BO_ 1843 0;
BA_ "NetworkInitialization" BO_ 1851 0;
BA_ "GenMsgDelayTime" BO_ 1851 0;
BA_ "GenMsgSendType" BO_ 1851 1;
BA_ "DiagResponse" BO_ 1851 1;
BA_ "GenMsgILSupport" BO_ 1851 0;
BA_ "NetworkInitialization" BO_ 1411 0;
BA_ "GenMsgCycleTime" BO_ 1411 1000;
BA_ "GenMsgSendType" BO_ 1411 0;
BA_ "NmAsrMessage" BO_ 1411 1;
BA_ "GenMsgILSupport" BO_ 1411 0;
BA_ "GenMsgStartDelayTime" BO_ 993 100;
BA_ "GenMsgCycleTime" BO_ 993 1000;
BA_ "GenMsgSendType" BO_ 993 5;
BA_ "NetworkInitialization" BO_ 1881 0;
BA_ "GenMsgDelayTime" BO_ 1881 0;
BA_ "GenMsgSendType" BO_ 1881 1;
BA_ "DiagResponse" BO_ 1881 1;
BA_ "GenMsgILSupport" BO_ 1881 0;
BA_ "NetworkInitialization" BO_ 1873 0;
BA_ "GenMsgDelayTime" BO_ 1873 0;
BA_ "GenMsgSendType" BO_ 1873 1;
BA_ "DiagRequest" BO_ 1873 1;
BA_ "GenMsgILSupport" BO_ 1873 0;
BA_ "NetworkInitialization" BO_ 2015 0;
BA_ "GenMsgDelayTime" BO_ 2015 0;
BA_ "GenMsgSendType" BO_ 2015 1;
BA_ "DiagState" BO_ 2015 1;
BA_ "GenMsgILSupport" BO_ 2015 0;
BA_ "GenMsgCycleTime" BO_ 806 100;
BA_ "GenMsgSendType" BO_ 806 0;
BA_ "FrameGatewayNetwork" BO_ 950 "HS1_CAN";
BA_ "FrameGatewayId" BO_ 950 950;
BA_ "FrameGatewayNetwork" BO_ 857 "HS3_CAN";
BA_ "FrameGatewayId" BO_ 857 867;
BA_ "FrameGatewayNetwork" BO_ 856 "HS3_CAN";
BA_ "FrameGatewayId" BO_ 856 866;
BA_ "GenMsgCycleTime" BO_ 854 1000;
BA_ "GenMsgSendType" BO_ 854 5;
BA_ "GenMsgCycleTime" BO_ 772 1000;
BA_ "GenMsgSendType" BO_ 772 5;
BA_ "U_P702_MY2021_Rx" SG_ 1066 BattULo_U_Actl_UB 1;
BA_ "U_CX727_MY2021_Rx" SG_ 1066 BattULo_U_Actl_UB 1;
BA_ "U_CX430_MY2021_Rx" SG_ 1066 BattULo_U_Actl_UB 1;
BA_ "U_U611_U625_MY20_Phev_Rx" SG_ 1066 BattULo_U_Actl_UB 1;
BA_ "U_B562_MY18_Diesel_Rx" SG_ 1066 BattULo_U_Actl_UB 1;
BA_ "U_CX482_CX483_MY20_Rx" SG_ 1066 BattULo_U_Actl_UB 1;
BA_ "U_U611_U625_MY20_Hev_Rx" SG_ 1066 BattULo_U_Actl_UB 1;
BA_ "U_U611_U625_MY20_Gas_Rx" SG_ 1066 BattULo_U_Actl_UB 1;
BA_ "U_B500_MY18_Diesel_Rx" SG_ 1066 BattULo_U_Actl_UB 1;
BA_ "U_B500_MY18_Gas_Rx" SG_ 1066 BattULo_U_Actl_UB 1;
BA_ "U_C490_MY18_Rx" SG_ 1066 BattULo_U_Actl_UB 1;
BA_ "U_B562_MY18_Gas_Rx" SG_ 1066 BattULo_U_Actl_UB 1;
BA_ "U_C519_MY18_5_Gas_Rx" SG_ 1066 BattULo_U_Actl_UB 1;
BA_ "U_C519_MY18_5_Diesel_Rx" SG_ 1066 BattULo_U_Actl_UB 1;
BA_ "U_B515_MCA_MY17_Gas_Rx" SG_ 1066 BattULo_U_Actl_UB 1;
BA_ "U_B515_MCA_MY17_Diesel_Rx" SG_ 1066 BattULo_U_Actl_UB 1;
BA_ "U_B479_MY17_Diesel_Rx" SG_ 1066 BattULo_U_Actl_UB 1;
BA_ "U_B479_MY17_Gas_Rx" SG_ 1066 BattULo_U_Actl_UB 1;
BA_ "U_P702_MY2021_Rx" SG_ 1066 BattULo_U_Actl 1;
BA_ "U_CX727_MY2021_Rx" SG_ 1066 BattULo_U_Actl 1;
BA_ "U_CX430_MY2021_Rx" SG_ 1066 BattULo_U_Actl 1;
BA_ "U_U611_U625_MY20_Phev_Rx" SG_ 1066 BattULo_U_Actl 1;
BA_ "U_B562_MY18_Diesel_Rx" SG_ 1066 BattULo_U_Actl 1;
BA_ "U_CX482_CX483_MY20_Rx" SG_ 1066 BattULo_U_Actl 1;
BA_ "U_U611_U625_MY20_Hev_Rx" SG_ 1066 BattULo_U_Actl 1;
BA_ "U_U611_U625_MY20_Gas_Rx" SG_ 1066 BattULo_U_Actl 1;
BA_ "U_B500_MY18_Diesel_Rx" SG_ 1066 BattULo_U_Actl 1;
BA_ "U_B500_MY18_Gas_Rx" SG_ 1066 BattULo_U_Actl 1;
BA_ "U_C490_MY18_Rx" SG_ 1066 BattULo_U_Actl 1;
BA_ "U_B562_MY18_Gas_Rx" SG_ 1066 BattULo_U_Actl 1;
BA_ "U_C519_MY18_5_Gas_Rx" SG_ 1066 BattULo_U_Actl 1;
BA_ "U_C519_MY18_5_Diesel_Rx" SG_ 1066 BattULo_U_Actl 1;
BA_ "U_B515_MCA_MY17_Gas_Rx" SG_ 1066 BattULo_U_Actl 1;
BA_ "U_B515_MCA_MY17_Diesel_Rx" SG_ 1066 BattULo_U_Actl 1;
BA_ "U_B479_MY17_Diesel_Rx" SG_ 1066 BattULo_U_Actl 1;
BA_ "U_B479_MY17_Gas_Rx" SG_ 1066 BattULo_U_Actl 1;
BA_ "GenSigStartValue" SG_ 1066 BattULo_U_Actl 255;
BA_ "U_P702_MY2021_Rx" SG_ 1066 PwSrcULo_I_Mx 1;
BA_ "U_CX727_MY2021_Rx" SG_ 1066 PwSrcULo_I_Mx 1;
BA_ "U_CX430_MY2021_Rx" SG_ 1066 PwSrcULo_I_Mx 1;
BA_ "U_U611_U625_MY20_Phev_Rx" SG_ 1066 PwSrcULo_I_Mx 1;
BA_ "U_B562_MY18_Diesel_Rx" SG_ 1066 PwSrcULo_I_Mx 1;
BA_ "U_CX482_CX483_MY20_Rx" SG_ 1066 PwSrcULo_I_Mx 1;
BA_ "U_U611_U625_MY20_Hev_Rx" SG_ 1066 PwSrcULo_I_Mx 1;
BA_ "U_U611_U625_MY20_Gas_Rx" SG_ 1066 PwSrcULo_I_Mx 1;
BA_ "U_B500_MY18_Diesel_Rx" SG_ 1066 PwSrcULo_I_Mx 1;
BA_ "U_B500_MY18_Gas_Rx" SG_ 1066 PwSrcULo_I_Mx 1;
BA_ "U_C490_MY18_Rx" SG_ 1066 PwSrcULo_I_Mx 1;
BA_ "U_B562_MY18_Gas_Rx" SG_ 1066 PwSrcULo_I_Mx 1;
BA_ "U_C519_MY18_5_Gas_Rx" SG_ 1066 PwSrcULo_I_Mx 1;
BA_ "U_C519_MY18_5_Diesel_Rx" SG_ 1066 PwSrcULo_I_Mx 1;
BA_ "U_B515_MCA_MY17_Gas_Rx" SG_ 1066 PwSrcULo_I_Mx 1;
BA_ "U_B515_MCA_MY17_Diesel_Rx" SG_ 1066 PwSrcULo_I_Mx 1;
BA_ "U_B479_MY17_Diesel_Rx" SG_ 1066 PwSrcULo_I_Mx 1;
BA_ "U_B479_MY17_Gas_Rx" SG_ 1066 PwSrcULo_I_Mx 1;
BA_ "U_P702_MY2021_Rx" SG_ 1066 PwSrcULo_I_Actl 1;
BA_ "U_CX727_MY2021_Rx" SG_ 1066 PwSrcULo_I_Actl 1;
BA_ "U_CX430_MY2021_Rx" SG_ 1066 PwSrcULo_I_Actl 1;
BA_ "U_U611_U625_MY20_Phev_Rx" SG_ 1066 PwSrcULo_I_Actl 1;
BA_ "U_B562_MY18_Diesel_Rx" SG_ 1066 PwSrcULo_I_Actl 1;
BA_ "U_CX482_CX483_MY20_Rx" SG_ 1066 PwSrcULo_I_Actl 1;
BA_ "U_U611_U625_MY20_Hev_Rx" SG_ 1066 PwSrcULo_I_Actl 1;
BA_ "U_U611_U625_MY20_Gas_Rx" SG_ 1066 PwSrcULo_I_Actl 1;
BA_ "U_B500_MY18_Diesel_Rx" SG_ 1066 PwSrcULo_I_Actl 1;
BA_ "U_B500_MY18_Gas_Rx" SG_ 1066 PwSrcULo_I_Actl 1;
BA_ "U_C490_MY18_Rx" SG_ 1066 PwSrcULo_I_Actl 1;
BA_ "U_B562_MY18_Gas_Rx" SG_ 1066 PwSrcULo_I_Actl 1;
BA_ "U_C519_MY18_5_Gas_Rx" SG_ 1066 PwSrcULo_I_Actl 1;
BA_ "U_C519_MY18_5_Diesel_Rx" SG_ 1066 PwSrcULo_I_Actl 1;
BA_ "U_B515_MCA_MY17_Gas_Rx" SG_ 1066 PwSrcULo_I_Actl 1;
BA_ "U_B515_MCA_MY17_Diesel_Rx" SG_ 1066 PwSrcULo_I_Actl 1;
BA_ "U_B479_MY17_Diesel_Rx" SG_ 1066 PwSrcULo_I_Actl 1;
BA_ "U_B479_MY17_Gas_Rx" SG_ 1066 PwSrcULo_I_Actl 1;
BA_ "U_P702_MY2021_Rx" SG_ 1066 PwSrcULo_I_Mx_UB 1;
BA_ "U_CX727_MY2021_Rx" SG_ 1066 PwSrcULo_I_Mx_UB 1;
BA_ "U_CX430_MY2021_Rx" SG_ 1066 PwSrcULo_I_Mx_UB 1;
BA_ "U_U611_U625_MY20_Phev_Rx" SG_ 1066 PwSrcULo_I_Mx_UB 1;
BA_ "U_B562_MY18_Diesel_Rx" SG_ 1066 PwSrcULo_I_Mx_UB 1;
BA_ "U_CX482_CX483_MY20_Rx" SG_ 1066 PwSrcULo_I_Mx_UB 1;
BA_ "U_U611_U625_MY20_Hev_Rx" SG_ 1066 PwSrcULo_I_Mx_UB 1;
BA_ "U_U611_U625_MY20_Gas_Rx" SG_ 1066 PwSrcULo_I_Mx_UB 1;
BA_ "U_B500_MY18_Diesel_Rx" SG_ 1066 PwSrcULo_I_Mx_UB 1;
BA_ "U_B500_MY18_Gas_Rx" SG_ 1066 PwSrcULo_I_Mx_UB 1;
BA_ "U_C490_MY18_Rx" SG_ 1066 PwSrcULo_I_Mx_UB 1;
BA_ "U_B562_MY18_Gas_Rx" SG_ 1066 PwSrcULo_I_Mx_UB 1;
BA_ "U_C519_MY18_5_Gas_Rx" SG_ 1066 PwSrcULo_I_Mx_UB 1;
BA_ "U_C519_MY18_5_Diesel_Rx" SG_ 1066 PwSrcULo_I_Mx_UB 1;
BA_ "U_B515_MCA_MY17_Gas_Rx" SG_ 1066 PwSrcULo_I_Mx_UB 1;
BA_ "U_B515_MCA_MY17_Diesel_Rx" SG_ 1066 PwSrcULo_I_Mx_UB 1;
BA_ "U_B479_MY17_Diesel_Rx" SG_ 1066 PwSrcULo_I_Mx_UB 1;
BA_ "U_B479_MY17_Gas_Rx" SG_ 1066 PwSrcULo_I_Mx_UB 1;
BA_ "U_P702_MY2021_Rx" SG_ 1066 PwSrcULo_I_Actl_UB 1;
BA_ "U_CX727_MY2021_Rx" SG_ 1066 PwSrcULo_I_Actl_UB 1;
BA_ "U_CX430_MY2021_Rx" SG_ 1066 PwSrcULo_I_Actl_UB 1;
BA_ "U_U611_U625_MY20_Phev_Rx" SG_ 1066 PwSrcULo_I_Actl_UB 1;
BA_ "U_B562_MY18_Diesel_Rx" SG_ 1066 PwSrcULo_I_Actl_UB 1;
BA_ "U_CX482_CX483_MY20_Rx" SG_ 1066 PwSrcULo_I_Actl_UB 1;
BA_ "U_U611_U625_MY20_Hev_Rx" SG_ 1066 PwSrcULo_I_Actl_UB 1;
BA_ "U_U611_U625_MY20_Gas_Rx" SG_ 1066 PwSrcULo_I_Actl_UB 1;
BA_ "U_B500_MY18_Diesel_Rx" SG_ 1066 PwSrcULo_I_Actl_UB 1;
BA_ "U_B500_MY18_Gas_Rx" SG_ 1066 PwSrcULo_I_Actl_UB 1;
BA_ "U_C490_MY18_Rx" SG_ 1066 PwSrcULo_I_Actl_UB 1;
BA_ "U_B562_MY18_Gas_Rx" SG_ 1066 PwSrcULo_I_Actl_UB 1;
BA_ "U_C519_MY18_5_Gas_Rx" SG_ 1066 PwSrcULo_I_Actl_UB 1;
BA_ "U_C519_MY18_5_Diesel_Rx" SG_ 1066 PwSrcULo_I_Actl_UB 1;
BA_ "U_B515_MCA_MY17_Gas_Rx" SG_ 1066 PwSrcULo_I_Actl_UB 1;
BA_ "U_B515_MCA_MY17_Diesel_Rx" SG_ 1066 PwSrcULo_I_Actl_UB 1;
BA_ "U_B479_MY17_Diesel_Rx" SG_ 1066 PwSrcULo_I_Actl_UB 1;
BA_ "U_B479_MY17_Gas_Rx" SG_ 1066 PwSrcULo_I_Actl_UB 1;
BA_ "CrossOver_InfoCAN" SG_ 994 Pers4OptIn_B_Stats 1;
BA_ "WakeupSignal" SG_ 994 Pers4OptIn_B_Stats 1;
BA_ "CrossOver_InfoCAN" SG_ 994 Pers3OptIn_B_Stats 1;
BA_ "WakeupSignal" SG_ 994 Pers3OptIn_B_Stats 1;
BA_ "CrossOver_InfoCAN" SG_ 994 Pers2OptIn_B_Stats 1;
BA_ "WakeupSignal" SG_ 994 Pers2OptIn_B_Stats 1;
BA_ "CrossOver_InfoCAN" SG_ 994 Pers1OptIn_B_Stats 1;
BA_ "WakeupSignal" SG_ 994 Pers1OptIn_B_Stats 1;
BA_ "U_B500_MY18_Diesel_Rx" SG_ 994 CtrStkPersIndex_D_Actl 1;
BA_ "U_B500_MY18_Gas_Rx" SG_ 994 CtrStkPersIndex_D_Actl 1;
BA_ "U_C519_MY18_5_Gas_Rx" SG_ 994 CtrStkPersIndex_D_Actl 1;
BA_ "U_C519_MY18_5_Diesel_Rx" SG_ 994 CtrStkPersIndex_D_Actl 1;
BA_ "U_B515_MCA_MY17_Gas_Rx" SG_ 994 CtrStkPersIndex_D_Actl 1;
BA_ "U_B515_MCA_MY17_Diesel_Rx" SG_ 994 CtrStkPersIndex_D_Actl 1;
BA_ "U_B479_MY17_Diesel_Rx" SG_ 994 CtrStkPersIndex_D_Actl 1;
BA_ "U_B479_MY17_Gas_Rx" SG_ 994 CtrStkPersIndex_D_Actl 1;
BA_ "U_CX727_MY2021_Rx" SG_ 994 CtrStkPersIndex_D_Actl 1;
BA_ "U_CX430_MY2021_Rx" SG_ 994 CtrStkPersIndex_D_Actl 1;
BA_ "U_P702_MY2021_Rx" SG_ 994 CtrStkPersIndex_D_Actl 1;
BA_ "U_U611_U625_MY20_Phev_Rx" SG_ 994 CtrStkPersIndex_D_Actl 1;
BA_ "U_CX482_CX483_MY20_Rx" SG_ 994 CtrStkPersIndex_D_Actl 1;
BA_ "U_U611_U625_MY20_Hev_Rx" SG_ 994 CtrStkPersIndex_D_Actl 1;
BA_ "U_U611_U625_MY20_Gas_Rx" SG_ 994 CtrStkPersIndex_D_Actl 1;
BA_ "GenSigStartValue" SG_ 994 CtrStkPersIndex_D_Actl 4;
BA_ "CrossOver_InfoCAN" SG_ 994 CtrStkPersIndex_D_Actl 1;
BA_ "U_B500_MY18_Diesel_Rx" SG_ 994 CtrStkFeatNoActl 1;
BA_ "U_B500_MY18_Gas_Rx" SG_ 994 CtrStkFeatNoActl 1;
BA_ "U_C519_MY18_5_Gas_Rx" SG_ 994 CtrStkFeatNoActl 1;
BA_ "U_C519_MY18_5_Diesel_Rx" SG_ 994 CtrStkFeatNoActl 1;
BA_ "U_B515_MCA_MY17_Gas_Rx" SG_ 994 CtrStkFeatNoActl 1;
BA_ "U_B515_MCA_MY17_Diesel_Rx" SG_ 994 CtrStkFeatNoActl 1;
BA_ "U_B479_MY17_Diesel_Rx" SG_ 994 CtrStkFeatNoActl 1;
BA_ "U_B479_MY17_Gas_Rx" SG_ 994 CtrStkFeatNoActl 1;
BA_ "U_P702_MY2021_Rx" SG_ 994 CtrStkFeatNoActl 1;
BA_ "U_CX727_MY2021_Rx" SG_ 994 CtrStkFeatNoActl 1;
BA_ "U_CX430_MY2021_Rx" SG_ 994 CtrStkFeatNoActl 1;
BA_ "U_U611_U625_MY20_Phev_Rx" SG_ 994 CtrStkFeatNoActl 1;
BA_ "U_CX482_CX483_MY20_Rx" SG_ 994 CtrStkFeatNoActl 1;
BA_ "U_U611_U625_MY20_Hev_Rx" SG_ 994 CtrStkFeatNoActl 1;
BA_ "U_U611_U625_MY20_Gas_Rx" SG_ 994 CtrStkFeatNoActl 1;
BA_ "CrossOver_InfoCAN" SG_ 994 CtrStkFeatNoActl 1;
BA_ "U_B500_MY18_Diesel_Rx" SG_ 994 CtrStkFeatConfigActl 1;
BA_ "U_B500_MY18_Gas_Rx" SG_ 994 CtrStkFeatConfigActl 1;
BA_ "U_C519_MY18_5_Gas_Rx" SG_ 994 CtrStkFeatConfigActl 1;
BA_ "U_C519_MY18_5_Diesel_Rx" SG_ 994 CtrStkFeatConfigActl 1;
BA_ "U_B515_MCA_MY17_Gas_Rx" SG_ 994 CtrStkFeatConfigActl 1;
BA_ "U_B515_MCA_MY17_Diesel_Rx" SG_ 994 CtrStkFeatConfigActl 1;
BA_ "U_B479_MY17_Diesel_Rx" SG_ 994 CtrStkFeatConfigActl 1;
BA_ "U_B479_MY17_Gas_Rx" SG_ 994 CtrStkFeatConfigActl 1;
BA_ "U_P702_MY2021_Rx" SG_ 994 CtrStkFeatConfigActl 1;
BA_ "U_CX727_MY2021_Rx" SG_ 994 CtrStkFeatConfigActl 1;
BA_ "U_CX430_MY2021_Rx" SG_ 994 CtrStkFeatConfigActl 1;
BA_ "U_U611_U625_MY20_Phev_Rx" SG_ 994 CtrStkFeatConfigActl 1;
BA_ "U_CX482_CX483_MY20_Rx" SG_ 994 CtrStkFeatConfigActl 1;
BA_ "U_U611_U625_MY20_Hev_Rx" SG_ 994 CtrStkFeatConfigActl 1;
BA_ "U_U611_U625_MY20_Gas_Rx" SG_ 994 CtrStkFeatConfigActl 1;
BA_ "CrossOver_InfoCAN" SG_ 994 CtrStkFeatConfigActl 1;
BA_ "U_B500_MY18_Diesel_Rx" SG_ 994 CtrStkDsplyOp_D_Rq 1;
BA_ "U_B500_MY18_Gas_Rx" SG_ 994 CtrStkDsplyOp_D_Rq 1;
BA_ "U_C519_MY18_5_Gas_Rx" SG_ 994 CtrStkDsplyOp_D_Rq 1;
BA_ "U_C519_MY18_5_Diesel_Rx" SG_ 994 CtrStkDsplyOp_D_Rq 1;
BA_ "U_B515_MCA_MY17_Gas_Rx" SG_ 994 CtrStkDsplyOp_D_Rq 1;
BA_ "U_B515_MCA_MY17_Diesel_Rx" SG_ 994 CtrStkDsplyOp_D_Rq 1;
BA_ "U_B479_MY17_Diesel_Rx" SG_ 994 CtrStkDsplyOp_D_Rq 1;
BA_ "U_B479_MY17_Gas_Rx" SG_ 994 CtrStkDsplyOp_D_Rq 1;
BA_ "U_CX727_MY2021_Rx" SG_ 994 CtrStkDsplyOp_D_Rq 1;
BA_ "U_CX430_MY2021_Rx" SG_ 994 CtrStkDsplyOp_D_Rq 1;
BA_ "U_P702_MY2021_Rx" SG_ 994 CtrStkDsplyOp_D_Rq 1;
BA_ "U_U611_U625_MY20_Phev_Rx" SG_ 994 CtrStkDsplyOp_D_Rq 1;
BA_ "U_CX482_CX483_MY20_Rx" SG_ 994 CtrStkDsplyOp_D_Rq 1;
BA_ "U_U611_U625_MY20_Hev_Rx" SG_ 994 CtrStkDsplyOp_D_Rq 1;
BA_ "U_U611_U625_MY20_Gas_Rx" SG_ 994 CtrStkDsplyOp_D_Rq 1;
BA_ "CrossOver_InfoCAN" SG_ 994 CtrStkDsplyOp_D_Rq 1;
BA_ "U_P702_MY2021_Rx" SG_ 994 PersStore_D_Rq 1;
BA_ "U_CX727_MY2021_Rx" SG_ 994 PersStore_D_Rq 1;
BA_ "U_CX430_MY2021_Rx" SG_ 994 PersStore_D_Rq 1;
BA_ "U_U611_U625_MY20_Phev_Rx" SG_ 994 PersStore_D_Rq 1;
BA_ "U_CX482_CX483_MY20_Rx" SG_ 994 PersStore_D_Rq 1;
BA_ "U_U611_U625_MY20_Hev_Rx" SG_ 994 PersStore_D_Rq 1;
BA_ "U_U611_U625_MY20_Gas_Rx" SG_ 994 PersStore_D_Rq 1;
BA_ "CrossOver_InfoCAN" SG_ 994 PersStore_D_Rq 1;
BA_ "ContentDependant" SG_ 376 EngAout_Aa_Actl 1;
BA_ "CrossOver_InfoCAN" SG_ 376 EngAout_Aa_Actl 1;
BA_ "U_P702_MY2021_Rx" SG_ 376 HvacHtrCore2_Te_Actl 1;
BA_ "U_CX727_MY2021_Rx" SG_ 376 HvacHtrCore2_Te_Actl 1;
BA_ "U_CX430_MY2021_Rx" SG_ 376 HvacHtrCore2_Te_Actl 1;
BA_ "U_U611_U625_MY20_Phev_Rx" SG_ 376 HvacHtrCore2_Te_Actl 1;
BA_ "U_B562_MY18_Diesel_Rx" SG_ 376 HvacHtrCore2_Te_Actl 1;
BA_ "U_CX482_CX483_MY20_Rx" SG_ 376 HvacHtrCore2_Te_Actl 1;
BA_ "U_U611_U625_MY20_Hev_Rx" SG_ 376 HvacHtrCore2_Te_Actl 1;
BA_ "U_U611_U625_MY20_Gas_Rx" SG_ 376 HvacHtrCore2_Te_Actl 1;
BA_ "U_B562_MY18_Gas_Rx" SG_ 376 HvacHtrCore2_Te_Actl 1;
BA_ "GenSigStartValue" SG_ 376 HvacHtrCore2_Te_Actl 200;
BA_ "U_P702_MY2021_Rx" SG_ 376 AirAmbTe_D_Qf 1;
BA_ "U_CX727_MY2021_Rx" SG_ 376 AirAmbTe_D_Qf 1;
BA_ "U_H567_MY20_Rx" SG_ 376 AirAmbTe_D_Qf 1;
BA_ "U_CX430_MY2021_Rx" SG_ 376 AirAmbTe_D_Qf 1;
BA_ "U_U611_U625_MY20_Phev_Rx" SG_ 376 AirAmbTe_D_Qf 1;
BA_ "U_B562_MY18_Diesel_Rx" SG_ 376 AirAmbTe_D_Qf 1;
BA_ "U_CX482_CX483_MY20_Rx" SG_ 376 AirAmbTe_D_Qf 1;
BA_ "U_U611_U625_MY20_Hev_Rx" SG_ 376 AirAmbTe_D_Qf 1;
BA_ "U_U611_U625_MY20_Gas_Rx" SG_ 376 AirAmbTe_D_Qf 1;
BA_ "U_B500_MY18_Diesel_Rx" SG_ 376 AirAmbTe_D_Qf 1;
BA_ "U_B500_MY18_Gas_Rx" SG_ 376 AirAmbTe_D_Qf 1;
BA_ "U_C490_MY18_Rx" SG_ 376 AirAmbTe_D_Qf 1;
BA_ "U_B562_MY18_Gas_Rx" SG_ 376 AirAmbTe_D_Qf 1;
BA_ "U_C519_MY18_5_Gas_Rx" SG_ 376 AirAmbTe_D_Qf 1;
BA_ "U_C519_MY18_5_Diesel_Rx" SG_ 376 AirAmbTe_D_Qf 1;
BA_ "U_B515_MCA_MY17_Gas_Rx" SG_ 376 AirAmbTe_D_Qf 1;
BA_ "U_B515_MCA_MY17_Diesel_Rx" SG_ 376 AirAmbTe_D_Qf 1;
BA_ "U_B479_MY17_Diesel_Rx" SG_ 376 AirAmbTe_D_Qf 1;
BA_ "U_B479_MY17_Gas_Rx" SG_ 376 AirAmbTe_D_Qf 1;
BA_ "MetaData" SG_ 376 AirAmbTe_D_Qf 1;
BA_ "GenSigStartValue" SG_ 376 AirAmbTe_D_Qf 1;
BA_ "CrossOver_InfoCAN" SG_ 376 AirAmbTe_D_Qf 1;
BA_ "U_P702_MY2021_Rx" SG_ 376 AirAmb_Te_ActlFilt 1;
BA_ "U_CX727_MY2021_Rx" SG_ 376 AirAmb_Te_ActlFilt 1;
BA_ "U_H567_MY20_Rx" SG_ 376 AirAmb_Te_ActlFilt 1;
BA_ "U_CX430_MY2021_Rx" SG_ 376 AirAmb_Te_ActlFilt 1;
BA_ "U_U611_U625_MY20_Phev_Rx" SG_ 376 AirAmb_Te_ActlFilt 1;
BA_ "U_B562_MY18_Diesel_Rx" SG_ 376 AirAmb_Te_ActlFilt 1;
BA_ "U_CX482_CX483_MY20_Rx" SG_ 376 AirAmb_Te_ActlFilt 1;
BA_ "U_U611_U625_MY20_Hev_Rx" SG_ 376 AirAmb_Te_ActlFilt 1;
BA_ "U_U611_U625_MY20_Gas_Rx" SG_ 376 AirAmb_Te_ActlFilt 1;
BA_ "U_B500_MY18_Diesel_Rx" SG_ 376 AirAmb_Te_ActlFilt 1;
BA_ "U_B500_MY18_Gas_Rx" SG_ 376 AirAmb_Te_ActlFilt 1;
BA_ "U_C490_MY18_Rx" SG_ 376 AirAmb_Te_ActlFilt 1;
BA_ "U_B562_MY18_Gas_Rx" SG_ 376 AirAmb_Te_ActlFilt 1;
BA_ "U_C519_MY18_5_Gas_Rx" SG_ 376 AirAmb_Te_ActlFilt 1;
BA_ "U_C519_MY18_5_Diesel_Rx" SG_ 376 AirAmb_Te_ActlFilt 1;
BA_ "U_B515_MCA_MY17_Gas_Rx" SG_ 376 AirAmb_Te_ActlFilt 1;
BA_ "U_B515_MCA_MY17_Diesel_Rx" SG_ 376 AirAmb_Te_ActlFilt 1;
BA_ "U_B479_MY17_Diesel_Rx" SG_ 376 AirAmb_Te_ActlFilt 1;
BA_ "U_B479_MY17_Gas_Rx" SG_ 376 AirAmb_Te_ActlFilt 1;
BA_ "GenSigStartValue" SG_ 376 AirAmb_Te_ActlFilt 512;
BA_ "CrossOver_InfoCAN" SG_ 376 AirAmb_Te_ActlFilt 1;
BA_ "U_P702_MY2021_Rx" SG_ 376 AirAmb_Te_Actl 1;
BA_ "U_CX727_MY2021_Rx" SG_ 376 AirAmb_Te_Actl 1;
BA_ "U_H567_MY20_Rx" SG_ 376 AirAmb_Te_Actl 1;
BA_ "U_CX430_MY2021_Rx" SG_ 376 AirAmb_Te_Actl 1;
BA_ "U_U611_U625_MY20_Phev_Rx" SG_ 376 AirAmb_Te_Actl 1;
BA_ "U_B562_MY18_Diesel_Rx" SG_ 376 AirAmb_Te_Actl 1;
BA_ "U_CX482_CX483_MY20_Rx" SG_ 376 AirAmb_Te_Actl 1;
BA_ "U_U611_U625_MY20_Hev_Rx" SG_ 376 AirAmb_Te_Actl 1;
BA_ "U_U611_U625_MY20_Gas_Rx" SG_ 376 AirAmb_Te_Actl 1;
BA_ "U_B500_MY18_Diesel_Rx" SG_ 376 AirAmb_Te_Actl 1;
BA_ "U_B500_MY18_Gas_Rx" SG_ 376 AirAmb_Te_Actl 1;
BA_ "U_C490_MY18_Rx" SG_ 376 AirAmb_Te_Actl 1;
BA_ "U_B562_MY18_Gas_Rx" SG_ 376 AirAmb_Te_Actl 1;
BA_ "U_C519_MY18_5_Gas_Rx" SG_ 376 AirAmb_Te_Actl 1;
BA_ "U_C519_MY18_5_Diesel_Rx" SG_ 376 AirAmb_Te_Actl 1;
BA_ "U_B515_MCA_MY17_Gas_Rx" SG_ 376 AirAmb_Te_Actl 1;
BA_ "U_B515_MCA_MY17_Diesel_Rx" SG_ 376 AirAmb_Te_Actl 1;
BA_ "U_B479_MY17_Diesel_Rx" SG_ 376 AirAmb_Te_Actl 1;
BA_ "U_B479_MY17_Gas_Rx" SG_ 376 AirAmb_Te_Actl 1;
BA_ "GenSigStartValue" SG_ 376 AirAmb_Te_Actl 512;
BA_ "CrossOver_InfoCAN" SG_ 376 AirAmb_Te_Actl 1;
BA_ "CrossOver_InfoCAN" SG_ 376 AirAmb_P_Actl 1;
BA_ "U_P702_MY2021_Rx" SG_ 951 TirePress_Info_MaxInd 1;
BA_ "U_CX727_MY2021_Rx" SG_ 951 TirePress_Info_MaxInd 1;
BA_ "U_VN127_MY20_Rx" SG_ 951 TirePress_Info_MaxInd 1;
BA_ "U_H567_MY20_Rx" SG_ 951 TirePress_Info_MaxInd 1;
BA_ "U_CX430_MY2021_Rx" SG_ 951 TirePress_Info_MaxInd 1;
BA_ "U_U611_U625_MY20_Phev_Rx" SG_ 951 TirePress_Info_MaxInd 1;
BA_ "U_CX482_CX483_MY20_Rx" SG_ 951 TirePress_Info_MaxInd 1;
BA_ "U_U611_U625_MY20_Hev_Rx" SG_ 951 TirePress_Info_MaxInd 1;
BA_ "U_U611_U625_MY20_Gas_Rx" SG_ 951 TirePress_Info_MaxInd 1;
BA_ "U_C519_MY18_5_Gas_Rx" SG_ 951 TirePress_Info_MaxInd 1;
BA_ "U_C519_MY18_5_Diesel_Rx" SG_ 951 TirePress_Info_MaxInd 1;
BA_ "U_B515_MCA_MY17_Gas_Rx" SG_ 951 TirePress_Info_MaxInd 1;
BA_ "U_B515_MCA_MY17_Diesel_Rx" SG_ 951 TirePress_Info_MaxInd 1;
BA_ "U_B479_MY17_Diesel_Rx" SG_ 951 TirePress_Info_MaxInd 1;
BA_ "U_B479_MY17_Gas_Rx" SG_ 951 TirePress_Info_MaxInd 1;
BA_ "U_P702_MY2021_Rx" SG_ 951 TirePress_Info_Index 1;
BA_ "U_CX727_MY2021_Rx" SG_ 951 TirePress_Info_Index 1;
BA_ "U_VN127_MY20_Rx" SG_ 951 TirePress_Info_Index 1;
BA_ "U_H567_MY20_Rx" SG_ 951 TirePress_Info_Index 1;
BA_ "U_CX430_MY2021_Rx" SG_ 951 TirePress_Info_Index 1;
BA_ "U_U611_U625_MY20_Phev_Rx" SG_ 951 TirePress_Info_Index 1;
BA_ "U_CX482_CX483_MY20_Rx" SG_ 951 TirePress_Info_Index 1;
BA_ "U_U611_U625_MY20_Hev_Rx" SG_ 951 TirePress_Info_Index 1;
BA_ "U_U611_U625_MY20_Gas_Rx" SG_ 951 TirePress_Info_Index 1;
BA_ "U_C519_MY18_5_Gas_Rx" SG_ 951 TirePress_Info_Index 1;
BA_ "U_C519_MY18_5_Diesel_Rx" SG_ 951 TirePress_Info_Index 1;
BA_ "U_B515_MCA_MY17_Gas_Rx" SG_ 951 TirePress_Info_Index 1;
BA_ "U_B515_MCA_MY17_Diesel_Rx" SG_ 951 TirePress_Info_Index 1;
BA_ "U_B479_MY17_Diesel_Rx" SG_ 951 TirePress_Info_Index 1;
BA_ "U_B479_MY17_Gas_Rx" SG_ 951 TirePress_Info_Index 1;
BA_ "U_P702_MY2021_Rx" SG_ 951 TirePress_Info_ID 1;
BA_ "U_CX727_MY2021_Rx" SG_ 951 TirePress_Info_ID 1;
BA_ "U_VN127_MY20_Rx" SG_ 951 TirePress_Info_ID 1;
BA_ "U_H567_MY20_Rx" SG_ 951 TirePress_Info_ID 1;
BA_ "U_CX430_MY2021_Rx" SG_ 951 TirePress_Info_ID 1;
BA_ "U_U611_U625_MY20_Phev_Rx" SG_ 951 TirePress_Info_ID 1;
BA_ "U_CX482_CX483_MY20_Rx" SG_ 951 TirePress_Info_ID 1;
BA_ "U_U611_U625_MY20_Hev_Rx" SG_ 951 TirePress_Info_ID 1;
BA_ "U_U611_U625_MY20_Gas_Rx" SG_ 951 TirePress_Info_ID 1;
BA_ "U_C519_MY18_5_Gas_Rx" SG_ 951 TirePress_Info_ID 1;
BA_ "U_C519_MY18_5_Diesel_Rx" SG_ 951 TirePress_Info_ID 1;
BA_ "U_B515_MCA_MY17_Gas_Rx" SG_ 951 TirePress_Info_ID 1;
BA_ "U_B515_MCA_MY17_Diesel_Rx" SG_ 951 TirePress_Info_ID 1;
BA_ "U_B479_MY17_Diesel_Rx" SG_ 951 TirePress_Info_ID 1;
BA_ "U_B479_MY17_Gas_Rx" SG_ 951 TirePress_Info_ID 1;
BA_ "U_P702_MY2021_Rx" SG_ 1068 HvacAirFullOut_B_Rq_UB 1;
BA_ "U_U611_U625_MY20_Phev_Rx" SG_ 1068 HvacAirFullOut_B_Rq_UB 1;
BA_ "U_U611_U625_MY20_Hev_Rx" SG_ 1068 HvacAirFullOut_B_Rq_UB 1;
BA_ "U_U611_U625_MY20_Gas_Rx" SG_ 1068 HvacAirFullOut_B_Rq_UB 1;
BA_ "U_P702_MY2021_Rx" SG_ 1068 HvacAirFullOut_B_Rq 1;
BA_ "U_U611_U625_MY20_Phev_Rx" SG_ 1068 HvacAirFullOut_B_Rq 1;
BA_ "U_U611_U625_MY20_Hev_Rx" SG_ 1068 HvacAirFullOut_B_Rq 1;
BA_ "U_U611_U625_MY20_Gas_Rx" SG_ 1068 HvacAirFullOut_B_Rq 1;
BA_ "GenSigStartValue" SG_ 1068 HvacRec_D_RqMxBatt 10;
BA_ "U_CX727_MY2021_Rx" SG_ 1068 Batt_Lo_SoC_B_UB 1;
BA_ "U_B562_MY18_Diesel_Rx" SG_ 1068 Batt_Lo_SoC_B_UB 1;
BA_ "U_U611_U625_MY20_Hev_Rx" SG_ 1068 Batt_Lo_SoC_B_UB 1;
BA_ "U_B500_MY18_Diesel_Rx" SG_ 1068 Batt_Lo_SoC_B_UB 1;
BA_ "U_B500_MY18_Gas_Rx" SG_ 1068 Batt_Lo_SoC_B_UB 1;
BA_ "U_C490_MY18_Rx" SG_ 1068 Batt_Lo_SoC_B_UB 1;
BA_ "U_B562_MY18_Gas_Rx" SG_ 1068 Batt_Lo_SoC_B_UB 1;
BA_ "U_P702_MY2021_Rx" SG_ 1068 Batt_Lo_SoC_B_UB 1;
BA_ "U_CX430_MY2021_Rx" SG_ 1068 Batt_Lo_SoC_B_UB 1;
BA_ "U_U611_U625_MY20_Phev_Rx" SG_ 1068 Batt_Lo_SoC_B_UB 1;
BA_ "U_CX482_CX483_MY20_Rx" SG_ 1068 Batt_Lo_SoC_B_UB 1;
BA_ "U_U611_U625_MY20_Gas_Rx" SG_ 1068 Batt_Lo_SoC_B_UB 1;
BA_ "U_C519_MY18_5_Gas_Rx" SG_ 1068 Batt_Lo_SoC_B_UB 1;
BA_ "U_C519_MY18_5_Diesel_Rx" SG_ 1068 Batt_Lo_SoC_B_UB 1;
BA_ "U_B515_MCA_MY17_Gas_Rx" SG_ 1068 Batt_Lo_SoC_B_UB 1;
BA_ "U_B515_MCA_MY17_Diesel_Rx" SG_ 1068 Batt_Lo_SoC_B_UB 1;
BA_ "U_B479_MY17_Diesel_Rx" SG_ 1068 Batt_Lo_SoC_B_UB 1;
BA_ "U_B479_MY17_Gas_Rx" SG_ 1068 Batt_Lo_SoC_B_UB 1;
BA_ "CrossOver_InfoCAN" SG_ 1068 Batt_Lo_SoC_B_UB 1;
BA_ "U_CX727_MY2021_Rx" SG_ 1068 Batt_Lo_SoC_B 1;
BA_ "U_B562_MY18_Diesel_Rx" SG_ 1068 Batt_Lo_SoC_B 1;
BA_ "U_U611_U625_MY20_Hev_Rx" SG_ 1068 Batt_Lo_SoC_B 1;
BA_ "U_B500_MY18_Diesel_Rx" SG_ 1068 Batt_Lo_SoC_B 1;
BA_ "U_B500_MY18_Gas_Rx" SG_ 1068 Batt_Lo_SoC_B 1;
BA_ "U_C490_MY18_Rx" SG_ 1068 Batt_Lo_SoC_B 1;
BA_ "U_B562_MY18_Gas_Rx" SG_ 1068 Batt_Lo_SoC_B 1;
BA_ "U_P702_MY2021_Rx" SG_ 1068 Batt_Lo_SoC_B 1;
BA_ "U_CX430_MY2021_Rx" SG_ 1068 Batt_Lo_SoC_B 1;
BA_ "U_U611_U625_MY20_Phev_Rx" SG_ 1068 Batt_Lo_SoC_B 1;
BA_ "U_CX482_CX483_MY20_Rx" SG_ 1068 Batt_Lo_SoC_B 1;
BA_ "U_U611_U625_MY20_Gas_Rx" SG_ 1068 Batt_Lo_SoC_B 1;
BA_ "U_C519_MY18_5_Gas_Rx" SG_ 1068 Batt_Lo_SoC_B 1;
BA_ "U_C519_MY18_5_Diesel_Rx" SG_ 1068 Batt_Lo_SoC_B 1;
BA_ "U_B515_MCA_MY17_Gas_Rx" SG_ 1068 Batt_Lo_SoC_B 1;
BA_ "U_B515_MCA_MY17_Diesel_Rx" SG_ 1068 Batt_Lo_SoC_B 1;
BA_ "U_B479_MY17_Diesel_Rx" SG_ 1068 Batt_Lo_SoC_B 1;
BA_ "U_B479_MY17_Gas_Rx" SG_ 1068 Batt_Lo_SoC_B 1;
BA_ "CrossOver_InfoCAN" SG_ 1068 Batt_Lo_SoC_B 1;
BA_ "U_CX727_MY2021_Rx" SG_ 1068 Batt_Crit_SoC_B_UB 1;
BA_ "U_B562_MY18_Diesel_Rx" SG_ 1068 Batt_Crit_SoC_B_UB 1;
BA_ "U_U611_U625_MY20_Hev_Rx" SG_ 1068 Batt_Crit_SoC_B_UB 1;
BA_ "U_B500_MY18_Diesel_Rx" SG_ 1068 Batt_Crit_SoC_B_UB 1;
BA_ "U_B500_MY18_Gas_Rx" SG_ 1068 Batt_Crit_SoC_B_UB 1;
BA_ "U_C490_MY18_Rx" SG_ 1068 Batt_Crit_SoC_B_UB 1;
BA_ "U_B562_MY18_Gas_Rx" SG_ 1068 Batt_Crit_SoC_B_UB 1;
BA_ "U_P702_MY2021_Rx" SG_ 1068 Batt_Crit_SoC_B_UB 1;
BA_ "U_CX430_MY2021_Rx" SG_ 1068 Batt_Crit_SoC_B_UB 1;
BA_ "U_U611_U625_MY20_Phev_Rx" SG_ 1068 Batt_Crit_SoC_B_UB 1;
BA_ "U_CX482_CX483_MY20_Rx" SG_ 1068 Batt_Crit_SoC_B_UB 1;
BA_ "U_U611_U625_MY20_Gas_Rx" SG_ 1068 Batt_Crit_SoC_B_UB 1;
BA_ "U_C519_MY18_5_Gas_Rx" SG_ 1068 Batt_Crit_SoC_B_UB 1;
BA_ "U_C519_MY18_5_Diesel_Rx" SG_ 1068 Batt_Crit_SoC_B_UB 1;
BA_ "U_B515_MCA_MY17_Gas_Rx" SG_ 1068 Batt_Crit_SoC_B_UB 1;
BA_ "U_B515_MCA_MY17_Diesel_Rx" SG_ 1068 Batt_Crit_SoC_B_UB 1;
BA_ "U_B479_MY17_Diesel_Rx" SG_ 1068 Batt_Crit_SoC_B_UB 1;
BA_ "U_B479_MY17_Gas_Rx" SG_ 1068 Batt_Crit_SoC_B_UB 1;
BA_ "CrossOver_InfoCAN" SG_ 1068 Batt_Crit_SoC_B_UB 1;
BA_ "U_CX727_MY2021_Rx" SG_ 1068 Batt_Crit_SoC_B 1;
BA_ "U_B562_MY18_Diesel_Rx" SG_ 1068 Batt_Crit_SoC_B 1;
BA_ "U_U611_U625_MY20_Hev_Rx" SG_ 1068 Batt_Crit_SoC_B 1;
BA_ "U_B500_MY18_Diesel_Rx" SG_ 1068 Batt_Crit_SoC_B 1;
BA_ "U_B500_MY18_Gas_Rx" SG_ 1068 Batt_Crit_SoC_B 1;
BA_ "U_C490_MY18_Rx" SG_ 1068 Batt_Crit_SoC_B 1;
BA_ "U_B562_MY18_Gas_Rx" SG_ 1068 Batt_Crit_SoC_B 1;
BA_ "U_P702_MY2021_Rx" SG_ 1068 Batt_Crit_SoC_B 1;
BA_ "U_CX430_MY2021_Rx" SG_ 1068 Batt_Crit_SoC_B 1;
BA_ "U_U611_U625_MY20_Phev_Rx" SG_ 1068 Batt_Crit_SoC_B 1;
BA_ "U_CX482_CX483_MY20_Rx" SG_ 1068 Batt_Crit_SoC_B 1;
BA_ "U_U611_U625_MY20_Gas_Rx" SG_ 1068 Batt_Crit_SoC_B 1;
BA_ "U_C519_MY18_5_Gas_Rx" SG_ 1068 Batt_Crit_SoC_B 1;
BA_ "U_C519_MY18_5_Diesel_Rx" SG_ 1068 Batt_Crit_SoC_B 1;
BA_ "U_B515_MCA_MY17_Gas_Rx" SG_ 1068 Batt_Crit_SoC_B 1;
BA_ "U_B515_MCA_MY17_Diesel_Rx" SG_ 1068 Batt_Crit_SoC_B 1;
BA_ "U_B479_MY17_Diesel_Rx" SG_ 1068 Batt_Crit_SoC_B 1;
BA_ "U_B479_MY17_Gas_Rx" SG_ 1068 Batt_Crit_SoC_B 1;
BA_ "CrossOver_InfoCAN" SG_ 1068 Batt_Crit_SoC_B 1;
BA_ "U_CX727_MY2021_Rx" SG_ 1068 Shed_T_Eng_Off_B_UB 1;
BA_ "U_H567_MY20_Rx" SG_ 1068 Shed_T_Eng_Off_B_UB 1;
BA_ "U_B562_MY18_Diesel_Rx" SG_ 1068 Shed_T_Eng_Off_B_UB 1;
BA_ "U_U611_U625_MY20_Hev_Rx" SG_ 1068 Shed_T_Eng_Off_B_UB 1;
BA_ "U_B500_MY18_Diesel_Rx" SG_ 1068 Shed_T_Eng_Off_B_UB 1;
BA_ "U_B500_MY18_Gas_Rx" SG_ 1068 Shed_T_Eng_Off_B_UB 1;
BA_ "U_C490_MY18_Rx" SG_ 1068 Shed_T_Eng_Off_B_UB 1;
BA_ "U_B562_MY18_Gas_Rx" SG_ 1068 Shed_T_Eng_Off_B_UB 1;
BA_ "U_P702_MY2021_Rx" SG_ 1068 Shed_T_Eng_Off_B_UB 1;
BA_ "U_CX430_MY2021_Rx" SG_ 1068 Shed_T_Eng_Off_B_UB 1;
BA_ "U_U611_U625_MY20_Phev_Rx" SG_ 1068 Shed_T_Eng_Off_B_UB 1;
BA_ "U_CX482_CX483_MY20_Rx" SG_ 1068 Shed_T_Eng_Off_B_UB 1;
BA_ "U_U611_U625_MY20_Gas_Rx" SG_ 1068 Shed_T_Eng_Off_B_UB 1;
BA_ "U_C519_MY18_5_Gas_Rx" SG_ 1068 Shed_T_Eng_Off_B_UB 1;
BA_ "U_C519_MY18_5_Diesel_Rx" SG_ 1068 Shed_T_Eng_Off_B_UB 1;
BA_ "U_B515_MCA_MY17_Gas_Rx" SG_ 1068 Shed_T_Eng_Off_B_UB 1;
BA_ "U_B515_MCA_MY17_Diesel_Rx" SG_ 1068 Shed_T_Eng_Off_B_UB 1;
BA_ "U_B479_MY17_Diesel_Rx" SG_ 1068 Shed_T_Eng_Off_B_UB 1;
BA_ "U_B479_MY17_Gas_Rx" SG_ 1068 Shed_T_Eng_Off_B_UB 1;
BA_ "CrossOver_InfoCAN" SG_ 1068 Shed_T_Eng_Off_B_UB 1;
BA_ "U_CX727_MY2021_Rx" SG_ 1068 Shed_T_Eng_Off_B 1;
BA_ "U_H567_MY20_Rx" SG_ 1068 Shed_T_Eng_Off_B 1;
BA_ "U_B562_MY18_Diesel_Rx" SG_ 1068 Shed_T_Eng_Off_B 1;
BA_ "U_U611_U625_MY20_Hev_Rx" SG_ 1068 Shed_T_Eng_Off_B 1;
BA_ "U_B500_MY18_Diesel_Rx" SG_ 1068 Shed_T_Eng_Off_B 1;
BA_ "U_B500_MY18_Gas_Rx" SG_ 1068 Shed_T_Eng_Off_B 1;
BA_ "U_C490_MY18_Rx" SG_ 1068 Shed_T_Eng_Off_B 1;
BA_ "U_B562_MY18_Gas_Rx" SG_ 1068 Shed_T_Eng_Off_B 1;
BA_ "U_P702_MY2021_Rx" SG_ 1068 Shed_T_Eng_Off_B 1;
BA_ "U_CX430_MY2021_Rx" SG_ 1068 Shed_T_Eng_Off_B 1;
BA_ "U_U611_U625_MY20_Phev_Rx" SG_ 1068 Shed_T_Eng_Off_B 1;
BA_ "U_CX482_CX483_MY20_Rx" SG_ 1068 Shed_T_Eng_Off_B 1;
BA_ "U_U611_U625_MY20_Gas_Rx" SG_ 1068 Shed_T_Eng_Off_B 1;
BA_ "U_C519_MY18_5_Gas_Rx" SG_ 1068 Shed_T_Eng_Off_B 1;
BA_ "U_C519_MY18_5_Diesel_Rx" SG_ 1068 Shed_T_Eng_Off_B 1;
BA_ "U_B515_MCA_MY17_Gas_Rx" SG_ 1068 Shed_T_Eng_Off_B 1;
BA_ "U_B515_MCA_MY17_Diesel_Rx" SG_ 1068 Shed_T_Eng_Off_B 1;
BA_ "U_B479_MY17_Diesel_Rx" SG_ 1068 Shed_T_Eng_Off_B 1;
BA_ "U_B479_MY17_Gas_Rx" SG_ 1068 Shed_T_Eng_Off_B 1;
BA_ "CrossOver_InfoCAN" SG_ 1068 Shed_T_Eng_Off_B 1;
BA_ "U_H567_MY20_Rx" SG_ 1068 Shed_Level_Req_UB 1;
BA_ "U_B562_MY18_Diesel_Rx" SG_ 1068 Shed_Level_Req_UB 1;
BA_ "U_B500_MY18_Diesel_Rx" SG_ 1068 Shed_Level_Req_UB 1;
BA_ "U_B500_MY18_Gas_Rx" SG_ 1068 Shed_Level_Req_UB 1;
BA_ "U_B562_MY18_Gas_Rx" SG_ 1068 Shed_Level_Req_UB 1;
BA_ "U_CX727_MY2021_Rx" SG_ 1068 Shed_Level_Req_UB 1;
BA_ "U_U611_U625_MY20_Hev_Rx" SG_ 1068 Shed_Level_Req_UB 1;
BA_ "U_C490_MY18_Rx" SG_ 1068 Shed_Level_Req_UB 1;
BA_ "U_P702_MY2021_Rx" SG_ 1068 Shed_Level_Req_UB 1;
BA_ "U_CX430_MY2021_Rx" SG_ 1068 Shed_Level_Req_UB 1;
BA_ "U_U611_U625_MY20_Phev_Rx" SG_ 1068 Shed_Level_Req_UB 1;
BA_ "U_CX482_CX483_MY20_Rx" SG_ 1068 Shed_Level_Req_UB 1;
BA_ "U_U611_U625_MY20_Gas_Rx" SG_ 1068 Shed_Level_Req_UB 1;
BA_ "U_C519_MY18_5_Gas_Rx" SG_ 1068 Shed_Level_Req_UB 1;
BA_ "U_C519_MY18_5_Diesel_Rx" SG_ 1068 Shed_Level_Req_UB 1;
BA_ "U_B515_MCA_MY17_Gas_Rx" SG_ 1068 Shed_Level_Req_UB 1;
BA_ "U_B515_MCA_MY17_Diesel_Rx" SG_ 1068 Shed_Level_Req_UB 1;
BA_ "U_B479_MY17_Diesel_Rx" SG_ 1068 Shed_Level_Req_UB 1;
BA_ "U_B479_MY17_Gas_Rx" SG_ 1068 Shed_Level_Req_UB 1;
BA_ "CrossOver_InfoCAN" SG_ 1068 Shed_Level_Req_UB 1;
BA_ "U_H567_MY20_Rx" SG_ 1068 Shed_Level_Req 1;
BA_ "U_B562_MY18_Diesel_Rx" SG_ 1068 Shed_Level_Req 1;
BA_ "U_B500_MY18_Diesel_Rx" SG_ 1068 Shed_Level_Req 1;
BA_ "U_B500_MY18_Gas_Rx" SG_ 1068 Shed_Level_Req 1;
BA_ "U_B562_MY18_Gas_Rx" SG_ 1068 Shed_Level_Req 1;
BA_ "U_CX727_MY2021_Rx" SG_ 1068 Shed_Level_Req 1;
BA_ "U_U611_U625_MY20_Hev_Rx" SG_ 1068 Shed_Level_Req 1;
BA_ "U_C490_MY18_Rx" SG_ 1068 Shed_Level_Req 1;
BA_ "U_P702_MY2021_Rx" SG_ 1068 Shed_Level_Req 1;
BA_ "U_CX430_MY2021_Rx" SG_ 1068 Shed_Level_Req 1;
BA_ "U_U611_U625_MY20_Phev_Rx" SG_ 1068 Shed_Level_Req 1;
BA_ "U_CX482_CX483_MY20_Rx" SG_ 1068 Shed_Level_Req 1;
BA_ "U_U611_U625_MY20_Gas_Rx" SG_ 1068 Shed_Level_Req 1;
BA_ "U_C519_MY18_5_Gas_Rx" SG_ 1068 Shed_Level_Req 1;
BA_ "U_C519_MY18_5_Diesel_Rx" SG_ 1068 Shed_Level_Req 1;
BA_ "U_B515_MCA_MY17_Gas_Rx" SG_ 1068 Shed_Level_Req 1;
BA_ "U_B515_MCA_MY17_Diesel_Rx" SG_ 1068 Shed_Level_Req 1;
BA_ "U_B479_MY17_Diesel_Rx" SG_ 1068 Shed_Level_Req 1;
BA_ "U_B479_MY17_Gas_Rx" SG_ 1068 Shed_Level_Req 1;
BA_ "CrossOver_InfoCAN" SG_ 1068 Shed_Level_Req 1;
BA_ "WakeupSignal" SG_ 1068 Shed_Level_Req 1;
BA_ "U_CX727_MY2021_Rx" SG_ 1068 Shed_Feature_Group_ID_UB 1;
BA_ "U_H567_MY20_Rx" SG_ 1068 Shed_Feature_Group_ID_UB 1;
BA_ "U_B562_MY18_Diesel_Rx" SG_ 1068 Shed_Feature_Group_ID_UB 1;
BA_ "U_U611_U625_MY20_Hev_Rx" SG_ 1068 Shed_Feature_Group_ID_UB 1;
BA_ "U_B500_MY18_Diesel_Rx" SG_ 1068 Shed_Feature_Group_ID_UB 1;
BA_ "U_B500_MY18_Gas_Rx" SG_ 1068 Shed_Feature_Group_ID_UB 1;
BA_ "U_C490_MY18_Rx" SG_ 1068 Shed_Feature_Group_ID_UB 1;
BA_ "U_B562_MY18_Gas_Rx" SG_ 1068 Shed_Feature_Group_ID_UB 1;
BA_ "U_P702_MY2021_Rx" SG_ 1068 Shed_Feature_Group_ID_UB 1;
BA_ "U_CX430_MY2021_Rx" SG_ 1068 Shed_Feature_Group_ID_UB 1;
BA_ "U_U611_U625_MY20_Phev_Rx" SG_ 1068 Shed_Feature_Group_ID_UB 1;
BA_ "U_CX482_CX483_MY20_Rx" SG_ 1068 Shed_Feature_Group_ID_UB 1;
BA_ "U_U611_U625_MY20_Gas_Rx" SG_ 1068 Shed_Feature_Group_ID_UB 1;
BA_ "U_C519_MY18_5_Gas_Rx" SG_ 1068 Shed_Feature_Group_ID_UB 1;
BA_ "U_C519_MY18_5_Diesel_Rx" SG_ 1068 Shed_Feature_Group_ID_UB 1;
BA_ "U_B515_MCA_MY17_Gas_Rx" SG_ 1068 Shed_Feature_Group_ID_UB 1;
BA_ "U_B515_MCA_MY17_Diesel_Rx" SG_ 1068 Shed_Feature_Group_ID_UB 1;
BA_ "U_B479_MY17_Diesel_Rx" SG_ 1068 Shed_Feature_Group_ID_UB 1;
BA_ "U_B479_MY17_Gas_Rx" SG_ 1068 Shed_Feature_Group_ID_UB 1;
BA_ "U_CX727_MY2021_Rx" SG_ 1068 Shed_Feature_Group_ID 1;
BA_ "U_H567_MY20_Rx" SG_ 1068 Shed_Feature_Group_ID 1;
BA_ "U_B562_MY18_Diesel_Rx" SG_ 1068 Shed_Feature_Group_ID 1;
BA_ "U_U611_U625_MY20_Hev_Rx" SG_ 1068 Shed_Feature_Group_ID 1;
BA_ "U_B500_MY18_Diesel_Rx" SG_ 1068 Shed_Feature_Group_ID 1;
BA_ "U_B500_MY18_Gas_Rx" SG_ 1068 Shed_Feature_Group_ID 1;
BA_ "U_C490_MY18_Rx" SG_ 1068 Shed_Feature_Group_ID 1;
BA_ "U_B562_MY18_Gas_Rx" SG_ 1068 Shed_Feature_Group_ID 1;
BA_ "U_P702_MY2021_Rx" SG_ 1068 Shed_Feature_Group_ID 1;
BA_ "U_CX430_MY2021_Rx" SG_ 1068 Shed_Feature_Group_ID 1;
BA_ "U_U611_U625_MY20_Phev_Rx" SG_ 1068 Shed_Feature_Group_ID 1;
BA_ "U_CX482_CX483_MY20_Rx" SG_ 1068 Shed_Feature_Group_ID 1;
BA_ "U_U611_U625_MY20_Gas_Rx" SG_ 1068 Shed_Feature_Group_ID 1;
BA_ "U_C519_MY18_5_Gas_Rx" SG_ 1068 Shed_Feature_Group_ID 1;
BA_ "U_C519_MY18_5_Diesel_Rx" SG_ 1068 Shed_Feature_Group_ID 1;
BA_ "U_B515_MCA_MY17_Gas_Rx" SG_ 1068 Shed_Feature_Group_ID 1;
BA_ "U_B515_MCA_MY17_Diesel_Rx" SG_ 1068 Shed_Feature_Group_ID 1;
BA_ "U_B479_MY17_Diesel_Rx" SG_ 1068 Shed_Feature_Group_ID 1;
BA_ "U_B479_MY17_Gas_Rx" SG_ 1068 Shed_Feature_Group_ID 1;
BA_ "WakeupSignal" SG_ 1068 Shed_Feature_Group_ID 1;
BA_ "U_CX727_MY2021_Rx" SG_ 1068 Shed_Drain_Eng_Off_B_UB 1;
BA_ "U_H567_MY20_Rx" SG_ 1068 Shed_Drain_Eng_Off_B_UB 1;
BA_ "U_B562_MY18_Diesel_Rx" SG_ 1068 Shed_Drain_Eng_Off_B_UB 1;
BA_ "U_U611_U625_MY20_Hev_Rx" SG_ 1068 Shed_Drain_Eng_Off_B_UB 1;
BA_ "U_B500_MY18_Diesel_Rx" SG_ 1068 Shed_Drain_Eng_Off_B_UB 1;
BA_ "U_B500_MY18_Gas_Rx" SG_ 1068 Shed_Drain_Eng_Off_B_UB 1;
BA_ "U_C490_MY18_Rx" SG_ 1068 Shed_Drain_Eng_Off_B_UB 1;
BA_ "U_B562_MY18_Gas_Rx" SG_ 1068 Shed_Drain_Eng_Off_B_UB 1;
BA_ "U_P702_MY2021_Rx" SG_ 1068 Shed_Drain_Eng_Off_B_UB 1;
BA_ "U_CX430_MY2021_Rx" SG_ 1068 Shed_Drain_Eng_Off_B_UB 1;
BA_ "U_U611_U625_MY20_Phev_Rx" SG_ 1068 Shed_Drain_Eng_Off_B_UB 1;
BA_ "U_CX482_CX483_MY20_Rx" SG_ 1068 Shed_Drain_Eng_Off_B_UB 1;
BA_ "U_U611_U625_MY20_Gas_Rx" SG_ 1068 Shed_Drain_Eng_Off_B_UB 1;
BA_ "U_C519_MY18_5_Gas_Rx" SG_ 1068 Shed_Drain_Eng_Off_B_UB 1;
BA_ "U_C519_MY18_5_Diesel_Rx" SG_ 1068 Shed_Drain_Eng_Off_B_UB 1;
BA_ "U_B515_MCA_MY17_Gas_Rx" SG_ 1068 Shed_Drain_Eng_Off_B_UB 1;
BA_ "U_B515_MCA_MY17_Diesel_Rx" SG_ 1068 Shed_Drain_Eng_Off_B_UB 1;
BA_ "U_B479_MY17_Diesel_Rx" SG_ 1068 Shed_Drain_Eng_Off_B_UB 1;
BA_ "U_B479_MY17_Gas_Rx" SG_ 1068 Shed_Drain_Eng_Off_B_UB 1;
BA_ "CrossOver_InfoCAN" SG_ 1068 Shed_Drain_Eng_Off_B_UB 1;
BA_ "U_CX727_MY2021_Rx" SG_ 1068 Shed_Drain_Eng_Off_B 1;
BA_ "U_H567_MY20_Rx" SG_ 1068 Shed_Drain_Eng_Off_B 1;
BA_ "U_B562_MY18_Diesel_Rx" SG_ 1068 Shed_Drain_Eng_Off_B 1;
BA_ "U_U611_U625_MY20_Hev_Rx" SG_ 1068 Shed_Drain_Eng_Off_B 1;
BA_ "U_B500_MY18_Diesel_Rx" SG_ 1068 Shed_Drain_Eng_Off_B 1;
BA_ "U_B500_MY18_Gas_Rx" SG_ 1068 Shed_Drain_Eng_Off_B 1;
BA_ "U_C490_MY18_Rx" SG_ 1068 Shed_Drain_Eng_Off_B 1;
BA_ "U_B562_MY18_Gas_Rx" SG_ 1068 Shed_Drain_Eng_Off_B 1;
BA_ "U_P702_MY2021_Rx" SG_ 1068 Shed_Drain_Eng_Off_B 1;
BA_ "U_CX430_MY2021_Rx" SG_ 1068 Shed_Drain_Eng_Off_B 1;
BA_ "U_U611_U625_MY20_Phev_Rx" SG_ 1068 Shed_Drain_Eng_Off_B 1;
BA_ "U_CX482_CX483_MY20_Rx" SG_ 1068 Shed_Drain_Eng_Off_B 1;
BA_ "U_U611_U625_MY20_Gas_Rx" SG_ 1068 Shed_Drain_Eng_Off_B 1;
BA_ "U_C519_MY18_5_Gas_Rx" SG_ 1068 Shed_Drain_Eng_Off_B 1;
BA_ "U_C519_MY18_5_Diesel_Rx" SG_ 1068 Shed_Drain_Eng_Off_B 1;
BA_ "U_B515_MCA_MY17_Gas_Rx" SG_ 1068 Shed_Drain_Eng_Off_B 1;
BA_ "U_B515_MCA_MY17_Diesel_Rx" SG_ 1068 Shed_Drain_Eng_Off_B 1;
BA_ "U_B479_MY17_Diesel_Rx" SG_ 1068 Shed_Drain_Eng_Off_B 1;
BA_ "U_B479_MY17_Gas_Rx" SG_ 1068 Shed_Drain_Eng_Off_B 1;
BA_ "CrossOver_InfoCAN" SG_ 1068 Shed_Drain_Eng_Off_B 1;
BA_ "U_P702_MY2021_Rx" SG_ 1068 AirCondRec_B_Rq_UB 1;
BA_ "U_CX727_MY2021_Rx" SG_ 1068 AirCondRec_B_Rq_UB 1;
BA_ "U_H567_MY20_Rx" SG_ 1068 AirCondRec_B_Rq_UB 1;
BA_ "U_CX430_MY2021_Rx" SG_ 1068 AirCondRec_B_Rq_UB 1;
BA_ "U_U611_U625_MY20_Phev_Rx" SG_ 1068 AirCondRec_B_Rq_UB 1;
BA_ "U_B562_MY18_Diesel_Rx" SG_ 1068 AirCondRec_B_Rq_UB 1;
BA_ "U_CX482_CX483_MY20_Rx" SG_ 1068 AirCondRec_B_Rq_UB 1;
BA_ "U_U611_U625_MY20_Hev_Rx" SG_ 1068 AirCondRec_B_Rq_UB 1;
BA_ "U_U611_U625_MY20_Gas_Rx" SG_ 1068 AirCondRec_B_Rq_UB 1;
BA_ "U_B500_MY18_Diesel_Rx" SG_ 1068 AirCondRec_B_Rq_UB 1;
BA_ "U_B500_MY18_Gas_Rx" SG_ 1068 AirCondRec_B_Rq_UB 1;
BA_ "U_C490_MY18_Rx" SG_ 1068 AirCondRec_B_Rq_UB 1;
BA_ "U_B562_MY18_Gas_Rx" SG_ 1068 AirCondRec_B_Rq_UB 1;
BA_ "U_C519_MY18_5_Gas_Rx" SG_ 1068 AirCondRec_B_Rq_UB 1;
BA_ "U_C519_MY18_5_Diesel_Rx" SG_ 1068 AirCondRec_B_Rq_UB 1;
BA_ "U_B515_MCA_MY17_Gas_Rx" SG_ 1068 AirCondRec_B_Rq_UB 1;
BA_ "U_B515_MCA_MY17_Diesel_Rx" SG_ 1068 AirCondRec_B_Rq_UB 1;
BA_ "U_B479_MY17_Diesel_Rx" SG_ 1068 AirCondRec_B_Rq_UB 1;
BA_ "U_B479_MY17_Gas_Rx" SG_ 1068 AirCondRec_B_Rq_UB 1;
BA_ "U_P702_MY2021_Rx" SG_ 1068 AirCondFluidHi_P_Actl_UB 1;
BA_ "U_CX727_MY2021_Rx" SG_ 1068 AirCondFluidHi_P_Actl_UB 1;
BA_ "U_H567_MY20_Rx" SG_ 1068 AirCondFluidHi_P_Actl_UB 1;
BA_ "U_CX430_MY2021_Rx" SG_ 1068 AirCondFluidHi_P_Actl_UB 1;
BA_ "U_U611_U625_MY20_Phev_Rx" SG_ 1068 AirCondFluidHi_P_Actl_UB 1;
BA_ "U_CX482_CX483_MY20_Rx" SG_ 1068 AirCondFluidHi_P_Actl_UB 1;
BA_ "U_U611_U625_MY20_Hev_Rx" SG_ 1068 AirCondFluidHi_P_Actl_UB 1;
BA_ "U_U611_U625_MY20_Gas_Rx" SG_ 1068 AirCondFluidHi_P_Actl_UB 1;
BA_ "U_B500_MY18_Diesel_Rx" SG_ 1068 AirCondFluidHi_P_Actl_UB 1;
BA_ "U_B500_MY18_Gas_Rx" SG_ 1068 AirCondFluidHi_P_Actl_UB 1;
BA_ "U_C519_MY18_5_Gas_Rx" SG_ 1068 AirCondFluidHi_P_Actl_UB 1;
BA_ "U_C519_MY18_5_Diesel_Rx" SG_ 1068 AirCondFluidHi_P_Actl_UB 1;
BA_ "U_B515_MCA_MY17_Gas_Rx" SG_ 1068 AirCondFluidHi_P_Actl_UB 1;
BA_ "U_B515_MCA_MY17_Diesel_Rx" SG_ 1068 AirCondFluidHi_P_Actl_UB 1;
BA_ "U_B479_MY17_Diesel_Rx" SG_ 1068 AirCondFluidHi_P_Actl_UB 1;
BA_ "U_B479_MY17_Gas_Rx" SG_ 1068 AirCondFluidHi_P_Actl_UB 1;
BA_ "U_P702_MY2021_Rx" SG_ 1068 AirCondClutch_B_Stats_UB 1;
BA_ "U_CX727_MY2021_Rx" SG_ 1068 AirCondClutch_B_Stats_UB 1;
BA_ "U_H567_MY20_Rx" SG_ 1068 AirCondClutch_B_Stats_UB 1;
BA_ "U_CX430_MY2021_Rx" SG_ 1068 AirCondClutch_B_Stats_UB 1;
BA_ "U_U611_U625_MY20_Phev_Rx" SG_ 1068 AirCondClutch_B_Stats_UB 1;
BA_ "U_B562_MY18_Diesel_Rx" SG_ 1068 AirCondClutch_B_Stats_UB 1;
BA_ "U_CX482_CX483_MY20_Rx" SG_ 1068 AirCondClutch_B_Stats_UB 1;
BA_ "U_U611_U625_MY20_Hev_Rx" SG_ 1068 AirCondClutch_B_Stats_UB 1;
BA_ "U_U611_U625_MY20_Gas_Rx" SG_ 1068 AirCondClutch_B_Stats_UB 1;
BA_ "U_B500_MY18_Diesel_Rx" SG_ 1068 AirCondClutch_B_Stats_UB 1;
BA_ "U_B500_MY18_Gas_Rx" SG_ 1068 AirCondClutch_B_Stats_UB 1;
BA_ "U_C490_MY18_Rx" SG_ 1068 AirCondClutch_B_Stats_UB 1;
BA_ "U_B562_MY18_Gas_Rx" SG_ 1068 AirCondClutch_B_Stats_UB 1;
BA_ "U_C519_MY18_5_Gas_Rx" SG_ 1068 AirCondClutch_B_Stats_UB 1;
BA_ "U_C519_MY18_5_Diesel_Rx" SG_ 1068 AirCondClutch_B_Stats_UB 1;
BA_ "U_B515_MCA_MY17_Gas_Rx" SG_ 1068 AirCondClutch_B_Stats_UB 1;
BA_ "U_B515_MCA_MY17_Diesel_Rx" SG_ 1068 AirCondClutch_B_Stats_UB 1;
BA_ "U_B479_MY17_Diesel_Rx" SG_ 1068 AirCondClutch_B_Stats_UB 1;
BA_ "U_B479_MY17_Gas_Rx" SG_ 1068 AirCondClutch_B_Stats_UB 1;
BA_ "U_P702_MY2021_Rx" SG_ 1068 AirCondRec_B_Rq 1;
BA_ "U_CX727_MY2021_Rx" SG_ 1068 AirCondRec_B_Rq 1;
BA_ "U_H567_MY20_Rx" SG_ 1068 AirCondRec_B_Rq 1;
BA_ "U_CX430_MY2021_Rx" SG_ 1068 AirCondRec_B_Rq 1;
BA_ "U_U611_U625_MY20_Phev_Rx" SG_ 1068 AirCondRec_B_Rq 1;
BA_ "U_B562_MY18_Diesel_Rx" SG_ 1068 AirCondRec_B_Rq 1;
BA_ "U_CX482_CX483_MY20_Rx" SG_ 1068 AirCondRec_B_Rq 1;
BA_ "U_U611_U625_MY20_Hev_Rx" SG_ 1068 AirCondRec_B_Rq 1;
BA_ "U_U611_U625_MY20_Gas_Rx" SG_ 1068 AirCondRec_B_Rq 1;
BA_ "U_B500_MY18_Diesel_Rx" SG_ 1068 AirCondRec_B_Rq 1;
BA_ "U_B500_MY18_Gas_Rx" SG_ 1068 AirCondRec_B_Rq 1;
BA_ "U_C490_MY18_Rx" SG_ 1068 AirCondRec_B_Rq 1;
BA_ "U_B562_MY18_Gas_Rx" SG_ 1068 AirCondRec_B_Rq 1;
BA_ "U_C519_MY18_5_Gas_Rx" SG_ 1068 AirCondRec_B_Rq 1;
BA_ "U_C519_MY18_5_Diesel_Rx" SG_ 1068 AirCondRec_B_Rq 1;
BA_ "U_B515_MCA_MY17_Gas_Rx" SG_ 1068 AirCondRec_B_Rq 1;
BA_ "U_B515_MCA_MY17_Diesel_Rx" SG_ 1068 AirCondRec_B_Rq 1;
BA_ "U_B479_MY17_Diesel_Rx" SG_ 1068 AirCondRec_B_Rq 1;
BA_ "U_B479_MY17_Gas_Rx" SG_ 1068 AirCondRec_B_Rq 1;
BA_ "ContentDependant" SG_ 1068 AirCondRec_B_Rq 1;
BA_ "CrossOver_InfoCAN" SG_ 1068 AirCondRec_B_Rq 1;
BA_ "U_P702_MY2021_Rx" SG_ 1068 AirCondFluidHi_P_Actl 1;
BA_ "U_CX727_MY2021_Rx" SG_ 1068 AirCondFluidHi_P_Actl 1;
BA_ "U_H567_MY20_Rx" SG_ 1068 AirCondFluidHi_P_Actl 1;
BA_ "U_CX430_MY2021_Rx" SG_ 1068 AirCondFluidHi_P_Actl 1;
BA_ "U_U611_U625_MY20_Phev_Rx" SG_ 1068 AirCondFluidHi_P_Actl 1;
BA_ "U_CX482_CX483_MY20_Rx" SG_ 1068 AirCondFluidHi_P_Actl 1;
BA_ "U_U611_U625_MY20_Hev_Rx" SG_ 1068 AirCondFluidHi_P_Actl 1;
BA_ "U_U611_U625_MY20_Gas_Rx" SG_ 1068 AirCondFluidHi_P_Actl 1;
BA_ "U_B500_MY18_Diesel_Rx" SG_ 1068 AirCondFluidHi_P_Actl 1;
BA_ "U_B500_MY18_Gas_Rx" SG_ 1068 AirCondFluidHi_P_Actl 1;
BA_ "U_C519_MY18_5_Gas_Rx" SG_ 1068 AirCondFluidHi_P_Actl 1;
BA_ "U_C519_MY18_5_Diesel_Rx" SG_ 1068 AirCondFluidHi_P_Actl 1;
BA_ "U_B515_MCA_MY17_Gas_Rx" SG_ 1068 AirCondFluidHi_P_Actl 1;
BA_ "U_B515_MCA_MY17_Diesel_Rx" SG_ 1068 AirCondFluidHi_P_Actl 1;
BA_ "U_B479_MY17_Diesel_Rx" SG_ 1068 AirCondFluidHi_P_Actl 1;
BA_ "U_B479_MY17_Gas_Rx" SG_ 1068 AirCondFluidHi_P_Actl 1;
BA_ "CrossOver_InfoCAN" SG_ 1068 AirCondFluidHi_P_Actl 1;
BA_ "U_P702_MY2021_Rx" SG_ 1068 AirCondClutch_B_Stats 1;
BA_ "U_CX727_MY2021_Rx" SG_ 1068 AirCondClutch_B_Stats 1;
BA_ "U_H567_MY20_Rx" SG_ 1068 AirCondClutch_B_Stats 1;
BA_ "U_CX430_MY2021_Rx" SG_ 1068 AirCondClutch_B_Stats 1;
BA_ "U_U611_U625_MY20_Phev_Rx" SG_ 1068 AirCondClutch_B_Stats 1;
BA_ "U_B562_MY18_Diesel_Rx" SG_ 1068 AirCondClutch_B_Stats 1;
BA_ "U_CX482_CX483_MY20_Rx" SG_ 1068 AirCondClutch_B_Stats 1;
BA_ "U_U611_U625_MY20_Hev_Rx" SG_ 1068 AirCondClutch_B_Stats 1;
BA_ "U_U611_U625_MY20_Gas_Rx" SG_ 1068 AirCondClutch_B_Stats 1;
BA_ "U_B500_MY18_Diesel_Rx" SG_ 1068 AirCondClutch_B_Stats 1;
BA_ "U_B500_MY18_Gas_Rx" SG_ 1068 AirCondClutch_B_Stats 1;
BA_ "U_C490_MY18_Rx" SG_ 1068 AirCondClutch_B_Stats 1;
BA_ "U_B562_MY18_Gas_Rx" SG_ 1068 AirCondClutch_B_Stats 1;
BA_ "U_C519_MY18_5_Gas_Rx" SG_ 1068 AirCondClutch_B_Stats 1;
BA_ "U_C519_MY18_5_Diesel_Rx" SG_ 1068 AirCondClutch_B_Stats 1;
BA_ "U_B515_MCA_MY17_Gas_Rx" SG_ 1068 AirCondClutch_B_Stats 1;
BA_ "U_B515_MCA_MY17_Diesel_Rx" SG_ 1068 AirCondClutch_B_Stats 1;
BA_ "U_B479_MY17_Diesel_Rx" SG_ 1068 AirCondClutch_B_Stats 1;
BA_ "U_B479_MY17_Gas_Rx" SG_ 1068 AirCondClutch_B_Stats 1;
BA_ "ContentDependant" SG_ 1068 AirCondClutch_B_Stats 1;
BA_ "CrossOver_InfoCAN" SG_ 1068 AirCondClutch_B_Stats 1;
BA_ "CrossOver_InfoCAN" SG_ 963 ImpactEvntFdbck_D_Stat 1;
BA_ "WakeupSignal" SG_ 963 ImpactEvntFdbck_D_Stat 1;
BA_ "U_P702_MY2021_Rx" SG_ 963 PudLampPsngr_D_Rq 1;
BA_ "U_CX430_MY2021_Rx" SG_ 963 PudLampPsngr_D_Rq 1;
BA_ "U_U611_U625_MY20_Phev_Rx" SG_ 963 PudLampPsngr_D_Rq 1;
BA_ "U_CX482_CX483_MY20_Rx" SG_ 963 PudLampPsngr_D_Rq 1;
BA_ "U_U611_U625_MY20_Hev_Rx" SG_ 963 PudLampPsngr_D_Rq 1;
BA_ "U_U611_U625_MY20_Gas_Rx" SG_ 963 PudLampPsngr_D_Rq 1;
BA_ "U_C519_MY18_5_Gas_Rx" SG_ 963 PudLampPsngr_D_Rq 1;
BA_ "U_C519_MY18_5_Diesel_Rx" SG_ 963 PudLampPsngr_D_Rq 1;
BA_ "U_B515_MCA_MY17_Gas_Rx" SG_ 963 PudLampPsngr_D_Rq 1;
BA_ "U_B515_MCA_MY17_Diesel_Rx" SG_ 963 PudLampPsngr_D_Rq 1;
BA_ "U_B479_MY17_Diesel_Rx" SG_ 963 PudLampPsngr_D_Rq 1;
BA_ "U_B479_MY17_Gas_Rx" SG_ 963 PudLampPsngr_D_Rq 1;
BA_ "CrossOver_InfoCAN" SG_ 963 HeadLampLoOut_B_Stat 1;
BA_ "CrossOver_InfoCAN" SG_ 963 CrnrLghtRight_Pc_Rq 1;
BA_ "CrossOver_InfoCAN" SG_ 963 CrnrLghtLeft_Pc_Rq 1;
BA_ "CrossOver_InfoCAN" SG_ 963 HeadLghtHiFdbck_D_Stat 1;
BA_ "CrossOver_InfoCAN" SG_ 963 PrkLightChime_B_Rq 1;
BA_ "CrossOver_InfoCAN" SG_ 963 TrnNotInPrkChime_B_Rq 1;
BA_ "CrossOver_InfoCAN" SG_ 963 HomeSafeLtChime_B_Rq 1;
BA_ "WakeupSignal" SG_ 963 HomeSafeLtChime_B_Rq 1;
BA_ "U_P702_MY2021_Rx" SG_ 963 StopLghtOn_B_Stat 1;
BA_ "U_CX430_MY2021_Rx" SG_ 963 StopLghtOn_B_Stat 1;
BA_ "U_U611_U625_MY20_Phev_Rx" SG_ 963 StopLghtOn_B_Stat 1;
BA_ "U_CX482_CX483_MY20_Rx" SG_ 963 StopLghtOn_B_Stat 1;
BA_ "U_U611_U625_MY20_Gas_Rx" SG_ 963 StopLghtOn_B_Stat 1;
BA_ "U_C519_MY18_5_Gas_Rx" SG_ 963 StopLghtOn_B_Stat 1;
BA_ "U_C519_MY18_5_Diesel_Rx" SG_ 963 StopLghtOn_B_Stat 1;
BA_ "U_B515_MCA_MY17_Gas_Rx" SG_ 963 StopLghtOn_B_Stat 1;
BA_ "U_B515_MCA_MY17_Diesel_Rx" SG_ 963 StopLghtOn_B_Stat 1;
BA_ "U_B479_MY17_Diesel_Rx" SG_ 963 StopLghtOn_B_Stat 1;
BA_ "U_B479_MY17_Gas_Rx" SG_ 963 StopLghtOn_B_Stat 1;
BA_ "CrossOver_InfoCAN" SG_ 963 StopLghtOn_B_Stat 1;
BA_ "WakeupSignal" SG_ 963 StopLghtOn_B_Stat 1;
BA_ "U_P702_MY2021_Rx" SG_ 963 RvrseLghtOn_B_Stat 1;
BA_ "U_CX430_MY2021_Rx" SG_ 963 RvrseLghtOn_B_Stat 1;
BA_ "U_U611_U625_MY20_Phev_Rx" SG_ 963 RvrseLghtOn_B_Stat 1;
BA_ "U_CX482_CX483_MY20_Rx" SG_ 963 RvrseLghtOn_B_Stat 1;
BA_ "U_U611_U625_MY20_Gas_Rx" SG_ 963 RvrseLghtOn_B_Stat 1;
BA_ "U_C519_MY18_5_Gas_Rx" SG_ 963 RvrseLghtOn_B_Stat 1;
BA_ "U_C519_MY18_5_Diesel_Rx" SG_ 963 RvrseLghtOn_B_Stat 1;
BA_ "U_B515_MCA_MY17_Gas_Rx" SG_ 963 RvrseLghtOn_B_Stat 1;
BA_ "U_B515_MCA_MY17_Diesel_Rx" SG_ 963 RvrseLghtOn_B_Stat 1;
BA_ "U_B479_MY17_Diesel_Rx" SG_ 963 RvrseLghtOn_B_Stat 1;
BA_ "U_B479_MY17_Gas_Rx" SG_ 963 RvrseLghtOn_B_Stat 1;
BA_ "CrossOver_InfoCAN" SG_ 963 RvrseLghtOn_B_Stat 1;
BA_ "U_P702_MY2021_Rx" SG_ 963 PrkLght_D_Stat 1;
BA_ "U_CX430_MY2021_Rx" SG_ 963 PrkLght_D_Stat 1;
BA_ "U_U611_U625_MY20_Phev_Rx" SG_ 963 PrkLght_D_Stat 1;
BA_ "U_CX482_CX483_MY20_Rx" SG_ 963 PrkLght_D_Stat 1;
BA_ "U_U611_U625_MY20_Gas_Rx" SG_ 963 PrkLght_D_Stat 1;
BA_ "U_C519_MY18_5_Gas_Rx" SG_ 963 PrkLght_D_Stat 1;
BA_ "U_C519_MY18_5_Diesel_Rx" SG_ 963 PrkLght_D_Stat 1;
BA_ "U_B515_MCA_MY17_Gas_Rx" SG_ 963 PrkLght_D_Stat 1;
BA_ "U_B515_MCA_MY17_Diesel_Rx" SG_ 963 PrkLght_D_Stat 1;
BA_ "U_B479_MY17_Diesel_Rx" SG_ 963 PrkLght_D_Stat 1;
BA_ "U_B479_MY17_Gas_Rx" SG_ 963 PrkLght_D_Stat 1;
BA_ "CrossOver_InfoCAN" SG_ 963 PrkLght_D_Stat 1;
BA_ "WakeupSignal" SG_ 963 PrkLght_D_Stat 1;
BA_ "GenSigStartValue" SG_ 963 HeadLghtSwtch_D_Stat 2;
BA_ "CrossOver_InfoCAN" SG_ 963 HeadLghtSwtch_D_Stat 1;
BA_ "WakeupSignal" SG_ 963 HeadLghtSwtch_D_Stat 1;
BA_ "CrossOver_InfoCAN" SG_ 963 KeyInIgnWarn_B_Cmd 1;
BA_ "WakeupSignal" SG_ 963 KeyInIgnWarn_B_Cmd 1;
BA_ "GenSigStartValue" SG_ 963 HeadLampLoFrOn_B_Stat 1;
BA_ "CrossOver_InfoCAN" SG_ 963 HeadLampLoFrOn_B_Stat 1;
BA_ "GenSigStartValue" SG_ 963 HeadLampLoFlOn_B_Stat 1;
BA_ "CrossOver_InfoCAN" SG_ 963 HeadLampLoFlOn_B_Stat 1;
BA_ "CrossOver_InfoCAN" SG_ 963 Headlamp_On_Wrning_Cmd 1;
BA_ "WakeupSignal" SG_ 963 Headlamp_On_Wrning_Cmd 1;
BA_ "GenSigStartValue" SG_ 963 HeadLampLoActv_B_Stat 1;
BA_ "CrossOver_InfoCAN" SG_ 963 HeadLampLoActv_B_Stat 1;
BA_ "CrossOver_InfoCAN" SG_ 963 HeadLghtHiOn_B_Stat 1;
BA_ "WakeupSignal" SG_ 963 HeadLghtHiOn_B_Stat 1;
BA_ "CrossOver_InfoCAN" SG_ 963 Park_Brake_Chime_Rqst 1;
BA_ "CrossOver_InfoCAN" SG_ 963 BrkWarnInd_B_Rq 1;
BA_ "WakeupSignal" SG_ 963 BrkWarnInd_B_Rq 1;
BA_ "CrossOver_InfoCAN" SG_ 963 Brk_Fluid_Lvl_Low 1;
BA_ "CrossOver_InfoCAN" SG_ 963 ReducedGuard_D_Stat 1;
BA_ "U_CX727_MY2021_Rx" SG_ 963 Courtesy_BSave_Stat 1;
BA_ "U_P702_MY2021_Rx" SG_ 963 Courtesy_BSave_Stat 1;
BA_ "U_CX430_MY2021_Rx" SG_ 963 Courtesy_BSave_Stat 1;
BA_ "U_U611_U625_MY20_Phev_Rx" SG_ 963 Courtesy_BSave_Stat 1;
BA_ "U_CX482_CX483_MY20_Rx" SG_ 963 Courtesy_BSave_Stat 1;
BA_ "U_U611_U625_MY20_Hev_Rx" SG_ 963 Courtesy_BSave_Stat 1;
BA_ "U_U611_U625_MY20_Gas_Rx" SG_ 963 Courtesy_BSave_Stat 1;
BA_ "U_C490_MY18_Rx" SG_ 963 Courtesy_BSave_Stat 1;
BA_ "U_C519_MY18_5_Gas_Rx" SG_ 963 Courtesy_BSave_Stat 1;
BA_ "U_C519_MY18_5_Diesel_Rx" SG_ 963 Courtesy_BSave_Stat 1;
BA_ "U_B515_MCA_MY17_Gas_Rx" SG_ 963 Courtesy_BSave_Stat 1;
BA_ "U_B515_MCA_MY17_Diesel_Rx" SG_ 963 Courtesy_BSave_Stat 1;
BA_ "U_B479_MY17_Diesel_Rx" SG_ 963 Courtesy_BSave_Stat 1;
BA_ "U_B479_MY17_Gas_Rx" SG_ 963 Courtesy_BSave_Stat 1;
BA_ "GenSigStartValue" SG_ 963 Courtesy_BSave_Stat 1;
BA_ "CrossOver_InfoCAN" SG_ 963 Courtesy_BSave_Stat 1;
BA_ "WakeupSignal" SG_ 963 Courtesy_BSave_Stat 1;
BA_ "CrossOver_InfoCAN" SG_ 963 DayRnngLampOn_B_Stat 1;
BA_ "CrossOver_InfoCAN" SG_ 963 PerimeterAlarmChimeRq 1;
BA_ "WakeupSignal" SG_ 963 PerimeterAlarmChimeRq 1;
BA_ "U_P702_MY2021_Rx" SG_ 963 PudLampDrv_D_Rq 1;
BA_ "U_CX727_MY2021_Rx" SG_ 963 PudLampDrv_D_Rq 1;
BA_ "U_CX430_MY2021_Rx" SG_ 963 PudLampDrv_D_Rq 1;
BA_ "U_U611_U625_MY20_Phev_Rx" SG_ 963 PudLampDrv_D_Rq 1;
BA_ "U_CX482_CX483_MY20_Rx" SG_ 963 PudLampDrv_D_Rq 1;
BA_ "U_U611_U625_MY20_Hev_Rx" SG_ 963 PudLampDrv_D_Rq 1;
BA_ "U_U611_U625_MY20_Gas_Rx" SG_ 963 PudLampDrv_D_Rq 1;
BA_ "U_C490_MY18_Rx" SG_ 963 PudLampDrv_D_Rq 1;
BA_ "U_C519_MY18_5_Gas_Rx" SG_ 963 PudLampDrv_D_Rq 1;
BA_ "U_C519_MY18_5_Diesel_Rx" SG_ 963 PudLampDrv_D_Rq 1;
BA_ "U_B515_MCA_MY17_Gas_Rx" SG_ 963 PudLampDrv_D_Rq 1;
BA_ "U_B515_MCA_MY17_Diesel_Rx" SG_ 963 PudLampDrv_D_Rq 1;
BA_ "U_B479_MY17_Diesel_Rx" SG_ 963 PudLampDrv_D_Rq 1;
BA_ "U_B479_MY17_Gas_Rx" SG_ 963 PudLampDrv_D_Rq 1;
BA_ "CrossOver_InfoCAN" SG_ 963 Perimeter_Alarm_Status 1;
BA_ "WakeupSignal" SG_ 963 Perimeter_Alarm_Status 1;
BA_ "U_CX727_MY2021_Rx" SG_ 963 WndwGlbl_D_Cmd 1;
BA_ "U_P702_MY2021_Rx" SG_ 963 WndwGlbl_D_Cmd 1;
BA_ "U_CX430_MY2021_Rx" SG_ 963 WndwGlbl_D_Cmd 1;
BA_ "U_U611_U625_MY20_Phev_Rx" SG_ 963 WndwGlbl_D_Cmd 1;
BA_ "U_CX482_CX483_MY20_Rx" SG_ 963 WndwGlbl_D_Cmd 1;
BA_ "U_U611_U625_MY20_Hev_Rx" SG_ 963 WndwGlbl_D_Cmd 1;
BA_ "U_U611_U625_MY20_Gas_Rx" SG_ 963 WndwGlbl_D_Cmd 1;
BA_ "U_C490_MY18_Rx" SG_ 963 WndwGlbl_D_Cmd 1;
BA_ "U_C519_MY18_5_Gas_Rx" SG_ 963 WndwGlbl_D_Cmd 1;
BA_ "U_C519_MY18_5_Diesel_Rx" SG_ 963 WndwGlbl_D_Cmd 1;
BA_ "U_B515_MCA_MY17_Gas_Rx" SG_ 963 WndwGlbl_D_Cmd 1;
BA_ "U_B515_MCA_MY17_Diesel_Rx" SG_ 963 WndwGlbl_D_Cmd 1;
BA_ "U_B479_MY17_Diesel_Rx" SG_ 963 WndwGlbl_D_Cmd 1;
BA_ "U_B479_MY17_Gas_Rx" SG_ 963 WndwGlbl_D_Cmd 1;
BA_ "CrossOver_InfoCAN" SG_ 963 WndwGlbl_D_Cmd 1;
BA_ "WakeupSignal" SG_ 963 WndwGlbl_D_Cmd 1;
BA_ "U_CX727_MY2021_Rx" SG_ 963 PudLamp_D_Rq 1;
BA_ "U_P702_MY2021_Rx" SG_ 963 PudLamp_D_Rq 1;
BA_ "U_CX430_MY2021_Rx" SG_ 963 PudLamp_D_Rq 1;
BA_ "U_U611_U625_MY20_Phev_Rx" SG_ 963 PudLamp_D_Rq 1;
BA_ "U_CX482_CX483_MY20_Rx" SG_ 963 PudLamp_D_Rq 1;
BA_ "U_U611_U625_MY20_Hev_Rx" SG_ 963 PudLamp_D_Rq 1;
BA_ "U_U611_U625_MY20_Gas_Rx" SG_ 963 PudLamp_D_Rq 1;
BA_ "U_C490_MY18_Rx" SG_ 963 PudLamp_D_Rq 1;
BA_ "U_C519_MY18_5_Gas_Rx" SG_ 963 PudLamp_D_Rq 1;
BA_ "U_C519_MY18_5_Diesel_Rx" SG_ 963 PudLamp_D_Rq 1;
BA_ "U_B515_MCA_MY17_Gas_Rx" SG_ 963 PudLamp_D_Rq 1;
BA_ "U_B515_MCA_MY17_Diesel_Rx" SG_ 963 PudLamp_D_Rq 1;
BA_ "U_B479_MY17_Diesel_Rx" SG_ 963 PudLamp_D_Rq 1;
BA_ "U_B479_MY17_Gas_Rx" SG_ 963 PudLamp_D_Rq 1;
BA_ "CrossOver_InfoCAN" SG_ 963 PudLamp_D_Rq 1;
BA_ "WakeupSignal" SG_ 963 PudLamp_D_Rq 1;
BA_ "GenSigSendType" SG_ 964 Cta_D_Rq 3;
BA_ "GenSigStartValue" SG_ 964 Cta_D_Rq 1;
BA_ "CrossOver_InfoCAN" SG_ 964 Cta_D_Rq 1;
BA_ "U_P702_MY2021_Rx" SG_ 964 GearRvrse_D_Actl_UB 1;
BA_ "U_CX727_MY2021_Rx" SG_ 964 GearRvrse_D_Actl_UB 1;
BA_ "U_CX430_MY2021_Rx" SG_ 964 GearRvrse_D_Actl_UB 1;
BA_ "U_U611_U625_MY20_Phev_Rx" SG_ 964 GearRvrse_D_Actl_UB 1;
BA_ "U_CX482_CX483_MY20_Rx" SG_ 964 GearRvrse_D_Actl_UB 1;
BA_ "U_U611_U625_MY20_Hev_Rx" SG_ 964 GearRvrse_D_Actl_UB 1;
BA_ "U_U611_U625_MY20_Gas_Rx" SG_ 964 GearRvrse_D_Actl_UB 1;
BA_ "U_C490_MY18_Rx" SG_ 964 GearRvrse_D_Actl_UB 1;
BA_ "U_C519_MY18_5_Gas_Rx" SG_ 964 GearRvrse_D_Actl_UB 1;
BA_ "U_C519_MY18_5_Diesel_Rx" SG_ 964 GearRvrse_D_Actl_UB 1;
BA_ "U_B515_MCA_MY17_Gas_Rx" SG_ 964 GearRvrse_D_Actl_UB 1;
BA_ "U_B515_MCA_MY17_Diesel_Rx" SG_ 964 GearRvrse_D_Actl_UB 1;
BA_ "U_B479_MY17_Diesel_Rx" SG_ 964 GearRvrse_D_Actl_UB 1;
BA_ "U_B479_MY17_Gas_Rx" SG_ 964 GearRvrse_D_Actl_UB 1;
BA_ "CrossOver_InfoCAN" SG_ 964 GearRvrse_D_Actl_UB 1;
BA_ "U_P702_MY2021_Rx" SG_ 964 GearRvrse_D_Actl 1;
BA_ "U_CX727_MY2021_Rx" SG_ 964 GearRvrse_D_Actl 1;
BA_ "U_CX430_MY2021_Rx" SG_ 964 GearRvrse_D_Actl 1;
BA_ "U_U611_U625_MY20_Phev_Rx" SG_ 964 GearRvrse_D_Actl 1;
BA_ "U_CX482_CX483_MY20_Rx" SG_ 964 GearRvrse_D_Actl 1;
BA_ "U_U611_U625_MY20_Hev_Rx" SG_ 964 GearRvrse_D_Actl 1;
BA_ "U_U611_U625_MY20_Gas_Rx" SG_ 964 GearRvrse_D_Actl 1;
BA_ "U_C490_MY18_Rx" SG_ 964 GearRvrse_D_Actl 1;
BA_ "U_C519_MY18_5_Gas_Rx" SG_ 964 GearRvrse_D_Actl 1;
BA_ "U_C519_MY18_5_Diesel_Rx" SG_ 964 GearRvrse_D_Actl 1;
BA_ "U_B515_MCA_MY17_Gas_Rx" SG_ 964 GearRvrse_D_Actl 1;
BA_ "U_B515_MCA_MY17_Diesel_Rx" SG_ 964 GearRvrse_D_Actl 1;
BA_ "U_B479_MY17_Diesel_Rx" SG_ 964 GearRvrse_D_Actl 1;
BA_ "U_B479_MY17_Gas_Rx" SG_ 964 GearRvrse_D_Actl 1;
BA_ "GenSigSendType" SG_ 964 GearRvrse_D_Actl 3;
BA_ "GenSigStartValue" SG_ 964 GearRvrse_D_Actl 7;
BA_ "CrossOver_InfoCAN" SG_ 964 GearRvrse_D_Actl 1;
BA_ "CrossOver_InfoCAN" SG_ 964 TurnLghtSwtch_D_Stat_UB 1;
BA_ "GenSigSendType" SG_ 964 TurnLghtSwtch_D_Stat 3;
BA_ "CrossOver_InfoCAN" SG_ 964 TurnLghtSwtch_D_Stat 1;
BA_ "WakeupSignal" SG_ 964 TurnLghtSwtch_D_Stat 1;
BA_ "GenSigSendType" SG_ 964 Power_Liftgate_Mode_Cmd 3;
BA_ "CrossOver_InfoCAN" SG_ 964 Power_Liftgate_Mode_Cmd 1;
BA_ "WakeupSignal" SG_ 964 Power_Liftgate_Mode_Cmd 1;
BA_ "U_P702_MY2021_Rx" SG_ 964 MetricActvTe_B_Actl_UB 1;
BA_ "U_CX727_MY2021_Rx" SG_ 964 MetricActvTe_B_Actl_UB 1;
BA_ "U_H567_MY20_Rx" SG_ 964 MetricActvTe_B_Actl_UB 1;
BA_ "U_CX430_MY2021_Rx" SG_ 964 MetricActvTe_B_Actl_UB 1;
BA_ "U_U611_U625_MY20_Phev_Rx" SG_ 964 MetricActvTe_B_Actl_UB 1;
BA_ "U_B562_MY18_Diesel_Rx" SG_ 964 MetricActvTe_B_Actl_UB 1;
BA_ "U_CX482_CX483_MY20_Rx" SG_ 964 MetricActvTe_B_Actl_UB 1;
BA_ "U_U611_U625_MY20_Hev_Rx" SG_ 964 MetricActvTe_B_Actl_UB 1;
BA_ "U_U611_U625_MY20_Gas_Rx" SG_ 964 MetricActvTe_B_Actl_UB 1;
BA_ "U_B500_MY18_Diesel_Rx" SG_ 964 MetricActvTe_B_Actl_UB 1;
BA_ "U_B500_MY18_Gas_Rx" SG_ 964 MetricActvTe_B_Actl_UB 1;
BA_ "U_C490_MY18_Rx" SG_ 964 MetricActvTe_B_Actl_UB 1;
BA_ "U_B562_MY18_Gas_Rx" SG_ 964 MetricActvTe_B_Actl_UB 1;
BA_ "U_C519_MY18_5_Gas_Rx" SG_ 964 MetricActvTe_B_Actl_UB 1;
BA_ "U_C519_MY18_5_Diesel_Rx" SG_ 964 MetricActvTe_B_Actl_UB 1;
BA_ "U_B515_MCA_MY17_Gas_Rx" SG_ 964 MetricActvTe_B_Actl_UB 1;
BA_ "U_B515_MCA_MY17_Diesel_Rx" SG_ 964 MetricActvTe_B_Actl_UB 1;
BA_ "U_B479_MY17_Diesel_Rx" SG_ 964 MetricActvTe_B_Actl_UB 1;
BA_ "U_B479_MY17_Gas_Rx" SG_ 964 MetricActvTe_B_Actl_UB 1;
BA_ "U_P702_MY2021_Rx" SG_ 964 MetricActvTe_B_Actl 1;
BA_ "U_CX727_MY2021_Rx" SG_ 964 MetricActvTe_B_Actl 1;
BA_ "U_H567_MY20_Rx" SG_ 964 MetricActvTe_B_Actl 1;
BA_ "U_CX430_MY2021_Rx" SG_ 964 MetricActvTe_B_Actl 1;
BA_ "U_U611_U625_MY20_Phev_Rx" SG_ 964 MetricActvTe_B_Actl 1;
BA_ "U_B562_MY18_Diesel_Rx" SG_ 964 MetricActvTe_B_Actl 1;
BA_ "U_CX482_CX483_MY20_Rx" SG_ 964 MetricActvTe_B_Actl 1;
BA_ "U_U611_U625_MY20_Hev_Rx" SG_ 964 MetricActvTe_B_Actl 1;
BA_ "U_U611_U625_MY20_Gas_Rx" SG_ 964 MetricActvTe_B_Actl 1;
BA_ "U_B500_MY18_Diesel_Rx" SG_ 964 MetricActvTe_B_Actl 1;
BA_ "U_B500_MY18_Gas_Rx" SG_ 964 MetricActvTe_B_Actl 1;
BA_ "U_C490_MY18_Rx" SG_ 964 MetricActvTe_B_Actl 1;
BA_ "U_B562_MY18_Gas_Rx" SG_ 964 MetricActvTe_B_Actl 1;
BA_ "U_C519_MY18_5_Gas_Rx" SG_ 964 MetricActvTe_B_Actl 1;
BA_ "U_C519_MY18_5_Diesel_Rx" SG_ 964 MetricActvTe_B_Actl 1;
BA_ "U_B515_MCA_MY17_Gas_Rx" SG_ 964 MetricActvTe_B_Actl 1;
BA_ "U_B515_MCA_MY17_Diesel_Rx" SG_ 964 MetricActvTe_B_Actl 1;
BA_ "U_B479_MY17_Diesel_Rx" SG_ 964 MetricActvTe_B_Actl 1;
BA_ "U_B479_MY17_Gas_Rx" SG_ 964 MetricActvTe_B_Actl 1;
BA_ "GenSigSendType" SG_ 964 MetricActvTe_B_Actl 3;
BA_ "CrossOver_InfoCAN" SG_ 964 MetricActvTe_B_Actl 1;
BA_ "U_P702_MY2021_Rx" SG_ 964 EngClntTe_D_Qf 1;
BA_ "U_CX727_MY2021_Rx" SG_ 964 EngClntTe_D_Qf 1;
BA_ "U_H567_MY20_Rx" SG_ 964 EngClntTe_D_Qf 1;
BA_ "U_CX430_MY2021_Rx" SG_ 964 EngClntTe_D_Qf 1;
BA_ "U_U611_U625_MY20_Phev_Rx" SG_ 964 EngClntTe_D_Qf 1;
BA_ "U_B562_MY18_Diesel_Rx" SG_ 964 EngClntTe_D_Qf 1;
BA_ "U_CX482_CX483_MY20_Rx" SG_ 964 EngClntTe_D_Qf 1;
BA_ "U_U611_U625_MY20_Hev_Rx" SG_ 964 EngClntTe_D_Qf 1;
BA_ "U_U611_U625_MY20_Gas_Rx" SG_ 964 EngClntTe_D_Qf 1;
BA_ "U_B500_MY18_Diesel_Rx" SG_ 964 EngClntTe_D_Qf 1;
BA_ "U_B500_MY18_Gas_Rx" SG_ 964 EngClntTe_D_Qf 1;
BA_ "U_C490_MY18_Rx" SG_ 964 EngClntTe_D_Qf 1;
BA_ "U_B562_MY18_Gas_Rx" SG_ 964 EngClntTe_D_Qf 1;
BA_ "U_C519_MY18_5_Gas_Rx" SG_ 964 EngClntTe_D_Qf 1;
BA_ "U_C519_MY18_5_Diesel_Rx" SG_ 964 EngClntTe_D_Qf 1;
BA_ "U_B515_MCA_MY17_Gas_Rx" SG_ 964 EngClntTe_D_Qf 1;
BA_ "U_B515_MCA_MY17_Diesel_Rx" SG_ 964 EngClntTe_D_Qf 1;
BA_ "U_B479_MY17_Diesel_Rx" SG_ 964 EngClntTe_D_Qf 1;
BA_ "U_B479_MY17_Gas_Rx" SG_ 964 EngClntTe_D_Qf 1;
BA_ "GenSigSendType" SG_ 964 EngClntTe_D_Qf 3;
BA_ "MetaData" SG_ 964 EngClntTe_D_Qf 1;
BA_ "CrossOver_InfoCAN" SG_ 964 EngClntTe_D_Qf 1;
BA_ "GenSigSendType" SG_ 964 Sod_D_Rq 3;
BA_ "GenSigStartValue" SG_ 964 Sod_D_Rq 2;
BA_ "CrossOver_InfoCAN" SG_ 964 Sod_D_Rq 1;
BA_ "U_P702_MY2021_Rx" SG_ 964 MetricActv_B_Actl 1;
BA_ "U_CX727_MY2021_Rx" SG_ 964 MetricActv_B_Actl 1;
BA_ "U_CX430_MY2021_Rx" SG_ 964 MetricActv_B_Actl 1;
BA_ "U_U611_U625_MY20_Phev_Rx" SG_ 964 MetricActv_B_Actl 1;
BA_ "U_B562_MY18_Diesel_Rx" SG_ 964 MetricActv_B_Actl 1;
BA_ "U_CX482_CX483_MY20_Rx" SG_ 964 MetricActv_B_Actl 1;
BA_ "U_U611_U625_MY20_Hev_Rx" SG_ 964 MetricActv_B_Actl 1;
BA_ "U_U611_U625_MY20_Gas_Rx" SG_ 964 MetricActv_B_Actl 1;
BA_ "U_B500_MY18_Diesel_Rx" SG_ 964 MetricActv_B_Actl 1;
BA_ "U_B500_MY18_Gas_Rx" SG_ 964 MetricActv_B_Actl 1;
BA_ "U_C490_MY18_Rx" SG_ 964 MetricActv_B_Actl 1;
BA_ "U_B562_MY18_Gas_Rx" SG_ 964 MetricActv_B_Actl 1;
BA_ "U_C519_MY18_5_Gas_Rx" SG_ 964 MetricActv_B_Actl 1;
BA_ "U_C519_MY18_5_Diesel_Rx" SG_ 964 MetricActv_B_Actl 1;
BA_ "U_B515_MCA_MY17_Gas_Rx" SG_ 964 MetricActv_B_Actl 1;
BA_ "U_B515_MCA_MY17_Diesel_Rx" SG_ 964 MetricActv_B_Actl 1;
BA_ "U_B479_MY17_Diesel_Rx" SG_ 964 MetricActv_B_Actl 1;
BA_ "U_B479_MY17_Gas_Rx" SG_ 964 MetricActv_B_Actl 1;
BA_ "GenSigSendType" SG_ 964 MetricActv_B_Actl 3;
BA_ "CrossOver_InfoCAN" SG_ 964 MetricActv_B_Actl 1;
BA_ "U_P702_MY2021_Rx" SG_ 964 EngClnt_Te_Actl 1;
BA_ "U_CX727_MY2021_Rx" SG_ 964 EngClnt_Te_Actl 1;
BA_ "U_H567_MY20_Rx" SG_ 964 EngClnt_Te_Actl 1;
BA_ "U_CX430_MY2021_Rx" SG_ 964 EngClnt_Te_Actl 1;
BA_ "U_U611_U625_MY20_Phev_Rx" SG_ 964 EngClnt_Te_Actl 1;
BA_ "U_B562_MY18_Diesel_Rx" SG_ 964 EngClnt_Te_Actl 1;
BA_ "U_CX482_CX483_MY20_Rx" SG_ 964 EngClnt_Te_Actl 1;
BA_ "U_U611_U625_MY20_Hev_Rx" SG_ 964 EngClnt_Te_Actl 1;
BA_ "U_U611_U625_MY20_Gas_Rx" SG_ 964 EngClnt_Te_Actl 1;
BA_ "U_B500_MY18_Diesel_Rx" SG_ 964 EngClnt_Te_Actl 1;
BA_ "U_B500_MY18_Gas_Rx" SG_ 964 EngClnt_Te_Actl 1;
BA_ "U_C490_MY18_Rx" SG_ 964 EngClnt_Te_Actl 1;
BA_ "U_B562_MY18_Gas_Rx" SG_ 964 EngClnt_Te_Actl 1;
BA_ "U_C519_MY18_5_Gas_Rx" SG_ 964 EngClnt_Te_Actl 1;
BA_ "U_C519_MY18_5_Diesel_Rx" SG_ 964 EngClnt_Te_Actl 1;
BA_ "U_B515_MCA_MY17_Gas_Rx" SG_ 964 EngClnt_Te_Actl 1;
BA_ "U_B515_MCA_MY17_Diesel_Rx" SG_ 964 EngClnt_Te_Actl 1;
BA_ "U_B479_MY17_Diesel_Rx" SG_ 964 EngClnt_Te_Actl 1;
BA_ "U_B479_MY17_Gas_Rx" SG_ 964 EngClnt_Te_Actl 1;
BA_ "GenSigSendType" SG_ 964 EngClnt_Te_Actl 3;
BA_ "CrossOver_InfoCAN" SG_ 964 EngClnt_Te_Actl 1;
BA_ "U_P702_MY2021_Rx" SG_ 964 MetricActv_B_Actl_UB 1;
BA_ "U_CX727_MY2021_Rx" SG_ 964 MetricActv_B_Actl_UB 1;
BA_ "U_CX430_MY2021_Rx" SG_ 964 MetricActv_B_Actl_UB 1;
BA_ "U_U611_U625_MY20_Phev_Rx" SG_ 964 MetricActv_B_Actl_UB 1;
BA_ "U_B562_MY18_Diesel_Rx" SG_ 964 MetricActv_B_Actl_UB 1;
BA_ "U_CX482_CX483_MY20_Rx" SG_ 964 MetricActv_B_Actl_UB 1;
BA_ "U_U611_U625_MY20_Hev_Rx" SG_ 964 MetricActv_B_Actl_UB 1;
BA_ "U_U611_U625_MY20_Gas_Rx" SG_ 964 MetricActv_B_Actl_UB 1;
BA_ "U_B500_MY18_Diesel_Rx" SG_ 964 MetricActv_B_Actl_UB 1;
BA_ "U_B500_MY18_Gas_Rx" SG_ 964 MetricActv_B_Actl_UB 1;
BA_ "U_C490_MY18_Rx" SG_ 964 MetricActv_B_Actl_UB 1;
BA_ "U_B562_MY18_Gas_Rx" SG_ 964 MetricActv_B_Actl_UB 1;
BA_ "U_C519_MY18_5_Gas_Rx" SG_ 964 MetricActv_B_Actl_UB 1;
BA_ "U_C519_MY18_5_Diesel_Rx" SG_ 964 MetricActv_B_Actl_UB 1;
BA_ "U_B515_MCA_MY17_Gas_Rx" SG_ 964 MetricActv_B_Actl_UB 1;
BA_ "U_B515_MCA_MY17_Diesel_Rx" SG_ 964 MetricActv_B_Actl_UB 1;
BA_ "U_B479_MY17_Diesel_Rx" SG_ 964 MetricActv_B_Actl_UB 1;
BA_ "U_B479_MY17_Gas_Rx" SG_ 964 MetricActv_B_Actl_UB 1;
BA_ "U_P702_MY2021_Rx" SG_ 964 EngClnt_Te_Actl_UB 1;
BA_ "U_CX727_MY2021_Rx" SG_ 964 EngClnt_Te_Actl_UB 1;
BA_ "U_H567_MY20_Rx" SG_ 964 EngClnt_Te_Actl_UB 1;
BA_ "U_CX430_MY2021_Rx" SG_ 964 EngClnt_Te_Actl_UB 1;
BA_ "U_U611_U625_MY20_Phev_Rx" SG_ 964 EngClnt_Te_Actl_UB 1;
BA_ "U_B562_MY18_Diesel_Rx" SG_ 964 EngClnt_Te_Actl_UB 1;
BA_ "U_CX482_CX483_MY20_Rx" SG_ 964 EngClnt_Te_Actl_UB 1;
BA_ "U_U611_U625_MY20_Hev_Rx" SG_ 964 EngClnt_Te_Actl_UB 1;
BA_ "U_U611_U625_MY20_Gas_Rx" SG_ 964 EngClnt_Te_Actl_UB 1;
BA_ "U_B500_MY18_Diesel_Rx" SG_ 964 EngClnt_Te_Actl_UB 1;
BA_ "U_B500_MY18_Gas_Rx" SG_ 964 EngClnt_Te_Actl_UB 1;
BA_ "U_C490_MY18_Rx" SG_ 964 EngClnt_Te_Actl_UB 1;
BA_ "U_B562_MY18_Gas_Rx" SG_ 964 EngClnt_Te_Actl_UB 1;
BA_ "U_C519_MY18_5_Gas_Rx" SG_ 964 EngClnt_Te_Actl_UB 1;
BA_ "U_C519_MY18_5_Diesel_Rx" SG_ 964 EngClnt_Te_Actl_UB 1;
BA_ "U_B515_MCA_MY17_Gas_Rx" SG_ 964 EngClnt_Te_Actl_UB 1;
BA_ "U_B515_MCA_MY17_Diesel_Rx" SG_ 964 EngClnt_Te_Actl_UB 1;
BA_ "U_B479_MY17_Diesel_Rx" SG_ 964 EngClnt_Te_Actl_UB 1;
BA_ "U_B479_MY17_Gas_Rx" SG_ 964 EngClnt_Te_Actl_UB 1;
BA_ "U_CX727_MY2021_Rx" SG_ 964 OCSSensrDataUpperLim_UB 1;
BA_ "U_CX430_MY2021_Rx" SG_ 964 OCSSensrDataUpperLim_UB 1;
BA_ "U_B500_MY18_Diesel_Rx" SG_ 964 OCSSensrDataUpperLim_UB 1;
BA_ "U_B500_MY18_Gas_Rx" SG_ 964 OCSSensrDataUpperLim_UB 1;
BA_ "U_C519_MY18_5_Diesel_Rx" SG_ 964 OCSSensrDataUpperLim_UB 1;
BA_ "U_B515_MCA_MY17_Gas_Rx" SG_ 964 OCSSensrDataUpperLim_UB 1;
BA_ "U_B515_MCA_MY17_Diesel_Rx" SG_ 964 OCSSensrDataUpperLim_UB 1;
BA_ "U_B479_MY17_Diesel_Rx" SG_ 964 OCSSensrDataUpperLim_UB 1;
BA_ "U_B479_MY17_Gas_Rx" SG_ 964 OCSSensrDataUpperLim_UB 1;
BA_ "U_C519_MY18_5_Gas_Rx" SG_ 964 OCSSensrDataUpperLim_UB 1;
BA_ "U_P702_MY2021_Rx" SG_ 964 OCSSensrDataUpperLim_UB 1;
BA_ "U_U611_U625_MY20_Phev_Rx" SG_ 964 OCSSensrDataUpperLim_UB 1;
BA_ "U_CX482_CX483_MY20_Rx" SG_ 964 OCSSensrDataUpperLim_UB 1;
BA_ "U_U611_U625_MY20_Hev_Rx" SG_ 964 OCSSensrDataUpperLim_UB 1;
BA_ "U_U611_U625_MY20_Gas_Rx" SG_ 964 OCSSensrDataUpperLim_UB 1;
BA_ "U_CX727_MY2021_Rx" SG_ 964 OCSSensrDataUpperLim 1;
BA_ "U_CX430_MY2021_Rx" SG_ 964 OCSSensrDataUpperLim 1;
BA_ "U_B500_MY18_Diesel_Rx" SG_ 964 OCSSensrDataUpperLim 1;
BA_ "U_B500_MY18_Gas_Rx" SG_ 964 OCSSensrDataUpperLim 1;
BA_ "U_B515_MCA_MY17_Gas_Rx" SG_ 964 OCSSensrDataUpperLim 1;
BA_ "U_B515_MCA_MY17_Diesel_Rx" SG_ 964 OCSSensrDataUpperLim 1;
BA_ "U_B479_MY17_Diesel_Rx" SG_ 964 OCSSensrDataUpperLim 1;
BA_ "U_B479_MY17_Gas_Rx" SG_ 964 OCSSensrDataUpperLim 1;
BA_ "U_C519_MY18_5_Gas_Rx" SG_ 964 OCSSensrDataUpperLim 1;
BA_ "U_C519_MY18_5_Diesel_Rx" SG_ 964 OCSSensrDataUpperLim 1;
BA_ "U_P702_MY2021_Rx" SG_ 964 OCSSensrDataUpperLim 1;
BA_ "U_U611_U625_MY20_Phev_Rx" SG_ 964 OCSSensrDataUpperLim 1;
BA_ "U_CX482_CX483_MY20_Rx" SG_ 964 OCSSensrDataUpperLim 1;
BA_ "U_U611_U625_MY20_Hev_Rx" SG_ 964 OCSSensrDataUpperLim 1;
BA_ "U_U611_U625_MY20_Gas_Rx" SG_ 964 OCSSensrDataUpperLim 1;
BA_ "GenSigSendType" SG_ 964 OCSSensrDataUpperLim 3;
BA_ "U_CX727_MY2021_Rx" SG_ 964 OCSSensrDataLowerLim_UB 1;
BA_ "U_CX430_MY2021_Rx" SG_ 964 OCSSensrDataLowerLim_UB 1;
BA_ "U_B500_MY18_Diesel_Rx" SG_ 964 OCSSensrDataLowerLim_UB 1;
BA_ "U_B500_MY18_Gas_Rx" SG_ 964 OCSSensrDataLowerLim_UB 1;
BA_ "U_B515_MCA_MY17_Gas_Rx" SG_ 964 OCSSensrDataLowerLim_UB 1;
BA_ "U_B515_MCA_MY17_Diesel_Rx" SG_ 964 OCSSensrDataLowerLim_UB 1;
BA_ "U_B479_MY17_Diesel_Rx" SG_ 964 OCSSensrDataLowerLim_UB 1;
BA_ "U_B479_MY17_Gas_Rx" SG_ 964 OCSSensrDataLowerLim_UB 1;
BA_ "U_C519_MY18_5_Gas_Rx" SG_ 964 OCSSensrDataLowerLim_UB 1;
BA_ "U_C519_MY18_5_Diesel_Rx" SG_ 964 OCSSensrDataLowerLim_UB 1;
BA_ "U_P702_MY2021_Rx" SG_ 964 OCSSensrDataLowerLim_UB 1;
BA_ "U_U611_U625_MY20_Phev_Rx" SG_ 964 OCSSensrDataLowerLim_UB 1;
BA_ "U_CX482_CX483_MY20_Rx" SG_ 964 OCSSensrDataLowerLim_UB 1;
BA_ "U_U611_U625_MY20_Hev_Rx" SG_ 964 OCSSensrDataLowerLim_UB 1;
BA_ "U_U611_U625_MY20_Gas_Rx" SG_ 964 OCSSensrDataLowerLim_UB 1;
BA_ "GenSigSendType" SG_ 964 PrkAid_D_Falt 3;
BA_ "CrossOver_InfoCAN" SG_ 964 PrkAid_D_Falt 1;
BA_ "U_CX727_MY2021_Rx" SG_ 964 OCSSensrDataLowerLim 1;
BA_ "U_CX430_MY2021_Rx" SG_ 964 OCSSensrDataLowerLim 1;
BA_ "U_B500_MY18_Diesel_Rx" SG_ 964 OCSSensrDataLowerLim 1;
BA_ "U_B500_MY18_Gas_Rx" SG_ 964 OCSSensrDataLowerLim 1;
BA_ "U_B515_MCA_MY17_Gas_Rx" SG_ 964 OCSSensrDataLowerLim 1;
BA_ "U_B515_MCA_MY17_Diesel_Rx" SG_ 964 OCSSensrDataLowerLim 1;
BA_ "U_B479_MY17_Diesel_Rx" SG_ 964 OCSSensrDataLowerLim 1;
BA_ "U_B479_MY17_Gas_Rx" SG_ 964 OCSSensrDataLowerLim 1;
BA_ "U_C519_MY18_5_Gas_Rx" SG_ 964 OCSSensrDataLowerLim 1;
BA_ "U_C519_MY18_5_Diesel_Rx" SG_ 964 OCSSensrDataLowerLim 1;
BA_ "U_P702_MY2021_Rx" SG_ 964 OCSSensrDataLowerLim 1;
BA_ "U_U611_U625_MY20_Phev_Rx" SG_ 964 OCSSensrDataLowerLim 1;
BA_ "U_CX482_CX483_MY20_Rx" SG_ 964 OCSSensrDataLowerLim 1;
BA_ "U_U611_U625_MY20_Hev_Rx" SG_ 964 OCSSensrDataLowerLim 1;
BA_ "U_U611_U625_MY20_Gas_Rx" SG_ 964 OCSSensrDataLowerLim 1;
BA_ "GenSigSendType" SG_ 964 OCSSensrDataLowerLim 3;
BA_ "U_P702_MY2021_Rx" SG_ 964 WiprFront_D_Stat_UB 1;
BA_ "U_CX727_MY2021_Rx" SG_ 964 WiprFront_D_Stat_UB 1;
BA_ "U_CX430_MY2021_Rx" SG_ 964 WiprFront_D_Stat_UB 1;
BA_ "U_U611_U625_MY20_Phev_Rx" SG_ 964 WiprFront_D_Stat_UB 1;
BA_ "U_CX482_CX483_MY20_Rx" SG_ 964 WiprFront_D_Stat_UB 1;
BA_ "U_U611_U625_MY20_Hev_Rx" SG_ 964 WiprFront_D_Stat_UB 1;
BA_ "U_U611_U625_MY20_Gas_Rx" SG_ 964 WiprFront_D_Stat_UB 1;
BA_ "U_B500_MY18_Diesel_Rx" SG_ 964 WiprFront_D_Stat_UB 1;
BA_ "U_B500_MY18_Gas_Rx" SG_ 964 WiprFront_D_Stat_UB 1;
BA_ "U_C519_MY18_5_Gas_Rx" SG_ 964 WiprFront_D_Stat_UB 1;
BA_ "U_C519_MY18_5_Diesel_Rx" SG_ 964 WiprFront_D_Stat_UB 1;
BA_ "U_B515_MCA_MY17_Gas_Rx" SG_ 964 WiprFront_D_Stat_UB 1;
BA_ "U_B515_MCA_MY17_Diesel_Rx" SG_ 964 WiprFront_D_Stat_UB 1;
BA_ "U_B479_MY17_Diesel_Rx" SG_ 964 WiprFront_D_Stat_UB 1;
BA_ "U_B479_MY17_Gas_Rx" SG_ 964 WiprFront_D_Stat_UB 1;
BA_ "U_P702_MY2021_Rx" SG_ 964 WiprFront_D_Stat 1;
BA_ "U_CX727_MY2021_Rx" SG_ 964 WiprFront_D_Stat 1;
BA_ "U_CX430_MY2021_Rx" SG_ 964 WiprFront_D_Stat 1;
BA_ "U_U611_U625_MY20_Phev_Rx" SG_ 964 WiprFront_D_Stat 1;
BA_ "U_CX482_CX483_MY20_Rx" SG_ 964 WiprFront_D_Stat 1;
BA_ "U_U611_U625_MY20_Hev_Rx" SG_ 964 WiprFront_D_Stat 1;
BA_ "U_U611_U625_MY20_Gas_Rx" SG_ 964 WiprFront_D_Stat 1;
BA_ "U_B500_MY18_Diesel_Rx" SG_ 964 WiprFront_D_Stat 1;
BA_ "U_B500_MY18_Gas_Rx" SG_ 964 WiprFront_D_Stat 1;
BA_ "U_C519_MY18_5_Gas_Rx" SG_ 964 WiprFront_D_Stat 1;
BA_ "U_C519_MY18_5_Diesel_Rx" SG_ 964 WiprFront_D_Stat 1;
BA_ "U_B515_MCA_MY17_Gas_Rx" SG_ 964 WiprFront_D_Stat 1;
BA_ "U_B515_MCA_MY17_Diesel_Rx" SG_ 964 WiprFront_D_Stat 1;
BA_ "U_B479_MY17_Diesel_Rx" SG_ 964 WiprFront_D_Stat 1;
BA_ "U_B479_MY17_Gas_Rx" SG_ 964 WiprFront_D_Stat 1;
BA_ "GenSigSendType" SG_ 964 WiprFront_D_Stat 3;
BA_ "GenSigStartValue" SG_ 964 WiprFront_D_Stat 15;
BA_ "GenSigSendType" SG_ 964 CamraDefog_B_Req 3;
BA_ "CrossOver_InfoCAN" SG_ 964 CamraDefog_B_Req 1;
BA_ "U_P702_MY2021_Rx" SG_ 1843 TesterPhysicalReqHVAC_RCCM 1;
BA_ "U_CX727_MY2021_Rx" SG_ 1843 TesterPhysicalReqHVAC_RCCM 1;
BA_ "U_H567_MY20_Rx" SG_ 1843 TesterPhysicalReqHVAC_RCCM 1;
BA_ "U_CX430_MY2021_Rx" SG_ 1843 TesterPhysicalReqHVAC_RCCM 1;
BA_ "U_U611_U625_MY20_Phev_Rx" SG_ 1843 TesterPhysicalReqHVAC_RCCM 1;
BA_ "U_B562_MY18_Diesel_Rx" SG_ 1843 TesterPhysicalReqHVAC_RCCM 1;
BA_ "U_CX482_CX483_MY20_Rx" SG_ 1843 TesterPhysicalReqHVAC_RCCM 1;
BA_ "U_U611_U625_MY20_Hev_Rx" SG_ 1843 TesterPhysicalReqHVAC_RCCM 1;
BA_ "U_U611_U625_MY20_Gas_Rx" SG_ 1843 TesterPhysicalReqHVAC_RCCM 1;
BA_ "U_B500_MY18_Diesel_Rx" SG_ 1843 TesterPhysicalReqHVAC_RCCM 1;
BA_ "U_B500_MY18_Gas_Rx" SG_ 1843 TesterPhysicalReqHVAC_RCCM 1;
BA_ "U_C490_MY18_Rx" SG_ 1843 TesterPhysicalReqHVAC_RCCM 1;
BA_ "U_B562_MY18_Gas_Rx" SG_ 1843 TesterPhysicalReqHVAC_RCCM 1;
BA_ "U_C519_MY18_5_Gas_Rx" SG_ 1843 TesterPhysicalReqHVAC_RCCM 1;
BA_ "U_C519_MY18_5_Diesel_Rx" SG_ 1843 TesterPhysicalReqHVAC_RCCM 1;
BA_ "U_B515_MCA_MY17_Gas_Rx" SG_ 1843 TesterPhysicalReqHVAC_RCCM 1;
BA_ "U_B515_MCA_MY17_Diesel_Rx" SG_ 1843 TesterPhysicalReqHVAC_RCCM 1;
BA_ "U_B479_MY17_Diesel_Rx" SG_ 1843 TesterPhysicalReqHVAC_RCCM 1;
BA_ "U_B479_MY17_Gas_Rx" SG_ 1843 TesterPhysicalReqHVAC_RCCM 1;
BA_ "GenSigSendType" SG_ 1843 TesterPhysicalReqHVAC_RCCM 3;
BA_ "U_P702_MY2021_Tx" SG_ 1851 TesterPhysicalResHVAC_RCCM 1;
BA_ "U_CX727_MY2021_Tx" SG_ 1851 TesterPhysicalResHVAC_RCCM 1;
BA_ "U_H567_MY20_Tx" SG_ 1851 TesterPhysicalResHVAC_RCCM 1;
BA_ "U_CX430_MY2021_Tx" SG_ 1851 TesterPhysicalResHVAC_RCCM 1;
BA_ "U_U611_U625_MY20_Phev_Tx" SG_ 1851 TesterPhysicalResHVAC_RCCM 1;
BA_ "U_B562_MY18_Diesel_Tx" SG_ 1851 TesterPhysicalResHVAC_RCCM 1;
BA_ "U_CX482_CX483_MY20_Tx" SG_ 1851 TesterPhysicalResHVAC_RCCM 1;
BA_ "U_U611_U625_MY20_Hev_Tx" SG_ 1851 TesterPhysicalResHVAC_RCCM 1;
BA_ "U_U611_U625_MY20_Gas_Tx" SG_ 1851 TesterPhysicalResHVAC_RCCM 1;
BA_ "U_B500_MY18_Diesel_Tx" SG_ 1851 TesterPhysicalResHVAC_RCCM 1;
BA_ "U_B500_MY18_Gas_Tx" SG_ 1851 TesterPhysicalResHVAC_RCCM 1;
BA_ "U_C490_MY18_Tx" SG_ 1851 TesterPhysicalResHVAC_RCCM 1;
BA_ "U_B562_MY18_Gas_Tx" SG_ 1851 TesterPhysicalResHVAC_RCCM 1;
BA_ "U_C519_MY18_5_Gas_Tx" SG_ 1851 TesterPhysicalResHVAC_RCCM 1;
BA_ "U_C519_MY18_5_Diesel_Tx" SG_ 1851 TesterPhysicalResHVAC_RCCM 1;
BA_ "U_B515_MCA_MY17_Gas_Tx" SG_ 1851 TesterPhysicalResHVAC_RCCM 1;
BA_ "U_B515_MCA_MY17_Diesel_Tx" SG_ 1851 TesterPhysicalResHVAC_RCCM 1;
BA_ "U_B479_MY17_Diesel_Tx" SG_ 1851 TesterPhysicalResHVAC_RCCM 1;
BA_ "U_B479_MY17_Gas_Tx" SG_ 1851 TesterPhysicalResHVAC_RCCM 1;
BA_ "GenSigSendType" SG_ 1851 TesterPhysicalResHVAC_RCCM 3;
BA_ "U_P702_MY2021_Tx" SG_ 1411 HVAC_GWOnBoardTester 1;
BA_ "U_CX727_MY2021_Tx" SG_ 1411 HVAC_GWOnBoardTester 1;
BA_ "U_H567_MY20_Tx" SG_ 1411 HVAC_GWOnBoardTester 1;
BA_ "U_CX430_MY2021_Tx" SG_ 1411 HVAC_GWOnBoardTester 1;
BA_ "U_U611_U625_MY20_Phev_Tx" SG_ 1411 HVAC_GWOnBoardTester 1;
BA_ "U_B562_MY18_Diesel_Tx" SG_ 1411 HVAC_GWOnBoardTester 1;
BA_ "U_CX482_CX483_MY20_Tx" SG_ 1411 HVAC_GWOnBoardTester 1;
BA_ "U_U611_U625_MY20_Hev_Tx" SG_ 1411 HVAC_GWOnBoardTester 1;
BA_ "U_U611_U625_MY20_Gas_Tx" SG_ 1411 HVAC_GWOnBoardTester 1;
BA_ "U_B500_MY18_Diesel_Tx" SG_ 1411 HVAC_GWOnBoardTester 1;
BA_ "U_B500_MY18_Gas_Tx" SG_ 1411 HVAC_GWOnBoardTester 1;
BA_ "U_C490_MY18_Tx" SG_ 1411 HVAC_GWOnBoardTester 1;
BA_ "U_B562_MY18_Gas_Tx" SG_ 1411 HVAC_GWOnBoardTester 1;
BA_ "U_C519_MY18_5_Gas_Tx" SG_ 1411 HVAC_GWOnBoardTester 1;
BA_ "U_C519_MY18_5_Diesel_Tx" SG_ 1411 HVAC_GWOnBoardTester 1;
BA_ "ContentDependant" SG_ 1411 HVAC_GWOnBoardTester 1;
BA_ "GenSigStartValue" SG_ 1411 HVAC_GWOnBoardTester 255;
BA_ "U_P702_MY2021_Tx" SG_ 1411 HVAC_GWNMProxy 1;
BA_ "U_CX727_MY2021_Tx" SG_ 1411 HVAC_GWNMProxy 1;
BA_ "U_H567_MY20_Tx" SG_ 1411 HVAC_GWNMProxy 1;
BA_ "U_CX430_MY2021_Tx" SG_ 1411 HVAC_GWNMProxy 1;
BA_ "U_U611_U625_MY20_Phev_Tx" SG_ 1411 HVAC_GWNMProxy 1;
BA_ "U_B562_MY18_Diesel_Tx" SG_ 1411 HVAC_GWNMProxy 1;
BA_ "U_CX482_CX483_MY20_Tx" SG_ 1411 HVAC_GWNMProxy 1;
BA_ "U_U611_U625_MY20_Hev_Tx" SG_ 1411 HVAC_GWNMProxy 1;
BA_ "U_U611_U625_MY20_Gas_Tx" SG_ 1411 HVAC_GWNMProxy 1;
BA_ "U_B500_MY18_Diesel_Tx" SG_ 1411 HVAC_GWNMProxy 1;
BA_ "U_B500_MY18_Gas_Tx" SG_ 1411 HVAC_GWNMProxy 1;
BA_ "U_C490_MY18_Tx" SG_ 1411 HVAC_GWNMProxy 1;
BA_ "U_B562_MY18_Gas_Tx" SG_ 1411 HVAC_GWNMProxy 1;
BA_ "U_C519_MY18_5_Gas_Tx" SG_ 1411 HVAC_GWNMProxy 1;
BA_ "U_C519_MY18_5_Diesel_Tx" SG_ 1411 HVAC_GWNMProxy 1;
BA_ "ContentDependant" SG_ 1411 HVAC_GWNMProxy 1;
BA_ "GenSigStartValue" SG_ 1411 HVAC_GWNMProxy 255;
BA_ "U_P702_MY2021_Tx" SG_ 1411 HVAC_AutoSarNMReserved4 1;
BA_ "U_CX727_MY2021_Tx" SG_ 1411 HVAC_AutoSarNMReserved4 1;
BA_ "U_H567_MY20_Tx" SG_ 1411 HVAC_AutoSarNMReserved4 1;
BA_ "U_CX430_MY2021_Tx" SG_ 1411 HVAC_AutoSarNMReserved4 1;
BA_ "U_U611_U625_MY20_Phev_Tx" SG_ 1411 HVAC_AutoSarNMReserved4 1;
BA_ "U_B562_MY18_Diesel_Tx" SG_ 1411 HVAC_AutoSarNMReserved4 1;
BA_ "U_CX482_CX483_MY20_Tx" SG_ 1411 HVAC_AutoSarNMReserved4 1;
BA_ "U_U611_U625_MY20_Hev_Tx" SG_ 1411 HVAC_AutoSarNMReserved4 1;
BA_ "U_U611_U625_MY20_Gas_Tx" SG_ 1411 HVAC_AutoSarNMReserved4 1;
BA_ "U_B500_MY18_Diesel_Tx" SG_ 1411 HVAC_AutoSarNMReserved4 1;
BA_ "U_B500_MY18_Gas_Tx" SG_ 1411 HVAC_AutoSarNMReserved4 1;
BA_ "U_C490_MY18_Tx" SG_ 1411 HVAC_AutoSarNMReserved4 1;
BA_ "U_B562_MY18_Gas_Tx" SG_ 1411 HVAC_AutoSarNMReserved4 1;
BA_ "U_C519_MY18_5_Gas_Tx" SG_ 1411 HVAC_AutoSarNMReserved4 1;
BA_ "U_C519_MY18_5_Diesel_Tx" SG_ 1411 HVAC_AutoSarNMReserved4 1;
BA_ "ContentDependant" SG_ 1411 HVAC_AutoSarNMReserved4 1;
BA_ "GenSigStartValue" SG_ 1411 HVAC_AutoSarNMReserved4 255;
BA_ "U_P702_MY2021_Tx" SG_ 1411 HVAC_AutoSarNMReserved3 1;
BA_ "U_CX727_MY2021_Tx" SG_ 1411 HVAC_AutoSarNMReserved3 1;
BA_ "U_H567_MY20_Tx" SG_ 1411 HVAC_AutoSarNMReserved3 1;
BA_ "U_CX430_MY2021_Tx" SG_ 1411 HVAC_AutoSarNMReserved3 1;
BA_ "U_U611_U625_MY20_Phev_Tx" SG_ 1411 HVAC_AutoSarNMReserved3 1;
BA_ "U_B562_MY18_Diesel_Tx" SG_ 1411 HVAC_AutoSarNMReserved3 1;
BA_ "U_CX482_CX483_MY20_Tx" SG_ 1411 HVAC_AutoSarNMReserved3 1;
BA_ "U_U611_U625_MY20_Hev_Tx" SG_ 1411 HVAC_AutoSarNMReserved3 1;
BA_ "U_U611_U625_MY20_Gas_Tx" SG_ 1411 HVAC_AutoSarNMReserved3 1;
BA_ "U_B500_MY18_Diesel_Tx" SG_ 1411 HVAC_AutoSarNMReserved3 1;
BA_ "U_B500_MY18_Gas_Tx" SG_ 1411 HVAC_AutoSarNMReserved3 1;
BA_ "U_C490_MY18_Tx" SG_ 1411 HVAC_AutoSarNMReserved3 1;
BA_ "U_B562_MY18_Gas_Tx" SG_ 1411 HVAC_AutoSarNMReserved3 1;
BA_ "U_C519_MY18_5_Gas_Tx" SG_ 1411 HVAC_AutoSarNMReserved3 1;
BA_ "U_C519_MY18_5_Diesel_Tx" SG_ 1411 HVAC_AutoSarNMReserved3 1;
BA_ "ContentDependant" SG_ 1411 HVAC_AutoSarNMReserved3 1;
BA_ "GenSigStartValue" SG_ 1411 HVAC_AutoSarNMReserved3 255;
BA_ "U_P702_MY2021_Tx" SG_ 1411 HVAC_AutoSarNMReserved2 1;
BA_ "U_CX727_MY2021_Tx" SG_ 1411 HVAC_AutoSarNMReserved2 1;
BA_ "U_H567_MY20_Tx" SG_ 1411 HVAC_AutoSarNMReserved2 1;
BA_ "U_CX430_MY2021_Tx" SG_ 1411 HVAC_AutoSarNMReserved2 1;
BA_ "U_U611_U625_MY20_Phev_Tx" SG_ 1411 HVAC_AutoSarNMReserved2 1;
BA_ "U_B562_MY18_Diesel_Tx" SG_ 1411 HVAC_AutoSarNMReserved2 1;
BA_ "U_CX482_CX483_MY20_Tx" SG_ 1411 HVAC_AutoSarNMReserved2 1;
BA_ "U_U611_U625_MY20_Hev_Tx" SG_ 1411 HVAC_AutoSarNMReserved2 1;
BA_ "U_U611_U625_MY20_Gas_Tx" SG_ 1411 HVAC_AutoSarNMReserved2 1;
BA_ "U_B500_MY18_Diesel_Tx" SG_ 1411 HVAC_AutoSarNMReserved2 1;
BA_ "U_B500_MY18_Gas_Tx" SG_ 1411 HVAC_AutoSarNMReserved2 1;
BA_ "U_C490_MY18_Tx" SG_ 1411 HVAC_AutoSarNMReserved2 1;
BA_ "U_B562_MY18_Gas_Tx" SG_ 1411 HVAC_AutoSarNMReserved2 1;
BA_ "U_C519_MY18_5_Gas_Tx" SG_ 1411 HVAC_AutoSarNMReserved2 1;
BA_ "U_C519_MY18_5_Diesel_Tx" SG_ 1411 HVAC_AutoSarNMReserved2 1;
BA_ "ContentDependant" SG_ 1411 HVAC_AutoSarNMReserved2 1;
BA_ "GenSigStartValue" SG_ 1411 HVAC_AutoSarNMReserved2 255;
BA_ "U_P702_MY2021_Tx" SG_ 1411 HVAC_AutoSarNMReserved 1;
BA_ "U_CX727_MY2021_Tx" SG_ 1411 HVAC_AutoSarNMReserved 1;
BA_ "U_H567_MY20_Tx" SG_ 1411 HVAC_AutoSarNMReserved 1;
BA_ "U_CX430_MY2021_Tx" SG_ 1411 HVAC_AutoSarNMReserved 1;
BA_ "U_U611_U625_MY20_Phev_Tx" SG_ 1411 HVAC_AutoSarNMReserved 1;
BA_ "U_B562_MY18_Diesel_Tx" SG_ 1411 HVAC_AutoSarNMReserved 1;
BA_ "U_CX482_CX483_MY20_Tx" SG_ 1411 HVAC_AutoSarNMReserved 1;
BA_ "U_U611_U625_MY20_Hev_Tx" SG_ 1411 HVAC_AutoSarNMReserved 1;
BA_ "U_U611_U625_MY20_Gas_Tx" SG_ 1411 HVAC_AutoSarNMReserved 1;
BA_ "U_B500_MY18_Diesel_Tx" SG_ 1411 HVAC_AutoSarNMReserved 1;
BA_ "U_B500_MY18_Gas_Tx" SG_ 1411 HVAC_AutoSarNMReserved 1;
BA_ "U_C490_MY18_Tx" SG_ 1411 HVAC_AutoSarNMReserved 1;
BA_ "U_B562_MY18_Gas_Tx" SG_ 1411 HVAC_AutoSarNMReserved 1;
BA_ "U_C519_MY18_5_Gas_Tx" SG_ 1411 HVAC_AutoSarNMReserved 1;
BA_ "U_C519_MY18_5_Diesel_Tx" SG_ 1411 HVAC_AutoSarNMReserved 1;
BA_ "ContentDependant" SG_ 1411 HVAC_AutoSarNMReserved 1;
BA_ "GenSigStartValue" SG_ 1411 HVAC_AutoSarNMReserved 255;
BA_ "U_P702_MY2021_Tx" SG_ 1411 HVAC_AutoSarNMNodeId 1;
BA_ "U_CX727_MY2021_Tx" SG_ 1411 HVAC_AutoSarNMNodeId 1;
BA_ "U_H567_MY20_Tx" SG_ 1411 HVAC_AutoSarNMNodeId 1;
BA_ "U_CX430_MY2021_Tx" SG_ 1411 HVAC_AutoSarNMNodeId 1;
BA_ "U_U611_U625_MY20_Phev_Tx" SG_ 1411 HVAC_AutoSarNMNodeId 1;
BA_ "U_B562_MY18_Diesel_Tx" SG_ 1411 HVAC_AutoSarNMNodeId 1;
BA_ "U_CX482_CX483_MY20_Tx" SG_ 1411 HVAC_AutoSarNMNodeId 1;
BA_ "U_U611_U625_MY20_Hev_Tx" SG_ 1411 HVAC_AutoSarNMNodeId 1;
BA_ "U_U611_U625_MY20_Gas_Tx" SG_ 1411 HVAC_AutoSarNMNodeId 1;
BA_ "U_B500_MY18_Diesel_Tx" SG_ 1411 HVAC_AutoSarNMNodeId 1;
BA_ "U_B500_MY18_Gas_Tx" SG_ 1411 HVAC_AutoSarNMNodeId 1;
BA_ "U_C490_MY18_Tx" SG_ 1411 HVAC_AutoSarNMNodeId 1;
BA_ "U_B562_MY18_Gas_Tx" SG_ 1411 HVAC_AutoSarNMNodeId 1;
BA_ "U_C519_MY18_5_Gas_Tx" SG_ 1411 HVAC_AutoSarNMNodeId 1;
BA_ "U_C519_MY18_5_Diesel_Tx" SG_ 1411 HVAC_AutoSarNMNodeId 1;
BA_ "ContentDependant" SG_ 1411 HVAC_AutoSarNMNodeId 1;
BA_ "GenSigStartValue" SG_ 1411 HVAC_AutoSarNMNodeId 83;
BA_ "U_P702_MY2021_Tx" SG_ 1411 HVAC_AutoSarNMControl 1;
BA_ "U_CX727_MY2021_Tx" SG_ 1411 HVAC_AutoSarNMControl 1;
BA_ "U_H567_MY20_Tx" SG_ 1411 HVAC_AutoSarNMControl 1;
BA_ "U_CX430_MY2021_Tx" SG_ 1411 HVAC_AutoSarNMControl 1;
BA_ "U_U611_U625_MY20_Phev_Tx" SG_ 1411 HVAC_AutoSarNMControl 1;
BA_ "U_B562_MY18_Diesel_Tx" SG_ 1411 HVAC_AutoSarNMControl 1;
BA_ "U_CX482_CX483_MY20_Tx" SG_ 1411 HVAC_AutoSarNMControl 1;
BA_ "U_U611_U625_MY20_Hev_Tx" SG_ 1411 HVAC_AutoSarNMControl 1;
BA_ "U_U611_U625_MY20_Gas_Tx" SG_ 1411 HVAC_AutoSarNMControl 1;
BA_ "U_B500_MY18_Diesel_Tx" SG_ 1411 HVAC_AutoSarNMControl 1;
BA_ "U_B500_MY18_Gas_Tx" SG_ 1411 HVAC_AutoSarNMControl 1;
BA_ "U_C490_MY18_Tx" SG_ 1411 HVAC_AutoSarNMControl 1;
BA_ "U_B562_MY18_Gas_Tx" SG_ 1411 HVAC_AutoSarNMControl 1;
BA_ "U_C519_MY18_5_Gas_Tx" SG_ 1411 HVAC_AutoSarNMControl 1;
BA_ "U_C519_MY18_5_Diesel_Tx" SG_ 1411 HVAC_AutoSarNMControl 1;
BA_ "ContentDependant" SG_ 1411 HVAC_AutoSarNMControl 1;
BA_ "U_P702_MY2021_Tx" SG_ 993 EmButtn_D_Stat 1;
BA_ "U_CX727_MY2021_Tx" SG_ 993 EmButtn_D_Stat 1;
BA_ "U_CX430_MY2021_Tx" SG_ 993 EmButtn_D_Stat 1;
BA_ "U_U611_U625_MY20_Phev_Tx" SG_ 993 EmButtn_D_Stat 1;
BA_ "U_CX482_CX483_MY20_Tx" SG_ 993 EmButtn_D_Stat 1;
BA_ "U_U611_U625_MY20_Hev_Tx" SG_ 993 EmButtn_D_Stat 1;
BA_ "U_U611_U625_MY20_Gas_Tx" SG_ 993 EmButtn_D_Stat 1;
BA_ "GenSigSendType" SG_ 993 EmButtn_D_Stat 3;
BA_ "U_P702_MY2021_Tx" SG_ 993 PersStore_D_Actl 1;
BA_ "U_CX727_MY2021_Tx" SG_ 993 PersStore_D_Actl 1;
BA_ "U_CX430_MY2021_Tx" SG_ 993 PersStore_D_Actl 1;
BA_ "U_U611_U625_MY20_Phev_Tx" SG_ 993 PersStore_D_Actl 1;
BA_ "U_CX482_CX483_MY20_Tx" SG_ 993 PersStore_D_Actl 1;
BA_ "U_U611_U625_MY20_Hev_Tx" SG_ 993 PersStore_D_Actl 1;
BA_ "U_U611_U625_MY20_Gas_Tx" SG_ 993 PersStore_D_Actl 1;
BA_ "U_C490_MY18_Tx" SG_ 993 PersStore_D_Actl 1;
BA_ "GenSigSendType" SG_ 993 PersStore_D_Actl 3;
BA_ "CrossOver_InfoCAN" SG_ 993 PersStore_D_Actl 1;
BA_ "U_P702_MY2021_Tx" SG_ 993 MemSwtch_D_RqRecall 1;
BA_ "U_CX727_MY2021_Tx" SG_ 993 MemSwtch_D_RqRecall 1;
BA_ "U_CX430_MY2021_Tx" SG_ 993 MemSwtch_D_RqRecall 1;
BA_ "U_U611_U625_MY20_Phev_Tx" SG_ 993 MemSwtch_D_RqRecall 1;
BA_ "U_CX482_CX483_MY20_Tx" SG_ 993 MemSwtch_D_RqRecall 1;
BA_ "U_U611_U625_MY20_Hev_Tx" SG_ 993 MemSwtch_D_RqRecall 1;
BA_ "U_U611_U625_MY20_Gas_Tx" SG_ 993 MemSwtch_D_RqRecall 1;
BA_ "U_C490_MY18_Tx" SG_ 993 MemSwtch_D_RqRecall 1;
BA_ "U_B479_MY17_Gas_Rx" SG_ 993 MemSwtch_D_RqRecall 1;
BA_ "GenSigSendType" SG_ 993 MemSwtch_D_RqRecall 3;
BA_ "CrossOver_InfoCAN" SG_ 993 MemSwtch_D_RqRecall 1;
BA_ "WakeupSignal" SG_ 993 MemSwtch_D_RqRecall 1;
BA_ "U_P702_MY2021_Tx" SG_ 993 MemSwtch_D_RqAssoc 1;
BA_ "U_CX727_MY2021_Tx" SG_ 993 MemSwtch_D_RqAssoc 1;
BA_ "U_CX430_MY2021_Tx" SG_ 993 MemSwtch_D_RqAssoc 1;
BA_ "U_U611_U625_MY20_Phev_Tx" SG_ 993 MemSwtch_D_RqAssoc 1;
BA_ "U_CX482_CX483_MY20_Tx" SG_ 993 MemSwtch_D_RqAssoc 1;
BA_ "U_U611_U625_MY20_Hev_Tx" SG_ 993 MemSwtch_D_RqAssoc 1;
BA_ "U_U611_U625_MY20_Gas_Tx" SG_ 993 MemSwtch_D_RqAssoc 1;
BA_ "U_C490_MY18_Tx" SG_ 993 MemSwtch_D_RqAssoc 1;
BA_ "U_B479_MY17_Gas_Rx" SG_ 993 MemSwtch_D_RqAssoc 1;
BA_ "GenSigSendType" SG_ 993 MemSwtch_D_RqAssoc 3;
BA_ "CrossOver_InfoCAN" SG_ 993 MemSwtch_D_RqAssoc 1;
BA_ "WakeupSignal" SG_ 993 MemSwtch_D_RqAssoc 1;
BA_ "U_P702_MY2021_Tx" SG_ 993 PersIndexDsm_D_Actl 1;
BA_ "U_CX727_MY2021_Tx" SG_ 993 PersIndexDsm_D_Actl 1;
BA_ "U_CX430_MY2021_Tx" SG_ 993 PersIndexDsm_D_Actl 1;
BA_ "U_U611_U625_MY20_Phev_Tx" SG_ 993 PersIndexDsm_D_Actl 1;
BA_ "U_CX482_CX483_MY20_Tx" SG_ 993 PersIndexDsm_D_Actl 1;
BA_ "U_U611_U625_MY20_Hev_Tx" SG_ 993 PersIndexDsm_D_Actl 1;
BA_ "U_U611_U625_MY20_Gas_Tx" SG_ 993 PersIndexDsm_D_Actl 1;
BA_ "U_C490_MY18_Tx" SG_ 993 PersIndexDsm_D_Actl 1;
BA_ "GenSigSendType" SG_ 993 PersIndexDsm_D_Actl 3;
BA_ "GenSigStartValue" SG_ 993 PersIndexDsm_D_Actl 4;
BA_ "CrossOver_InfoCAN" SG_ 993 PersIndexDsm_D_Actl 1;
BA_ "U_P702_MY2021_Tx" SG_ 993 FeatNoDsmActl 1;
BA_ "U_CX727_MY2021_Tx" SG_ 993 FeatNoDsmActl 1;
BA_ "U_CX430_MY2021_Tx" SG_ 993 FeatNoDsmActl 1;
BA_ "U_U611_U625_MY20_Phev_Tx" SG_ 993 FeatNoDsmActl 1;
BA_ "U_CX482_CX483_MY20_Tx" SG_ 993 FeatNoDsmActl 1;
BA_ "U_U611_U625_MY20_Hev_Tx" SG_ 993 FeatNoDsmActl 1;
BA_ "U_U611_U625_MY20_Gas_Tx" SG_ 993 FeatNoDsmActl 1;
BA_ "U_C490_MY18_Tx" SG_ 993 FeatNoDsmActl 1;
BA_ "GenSigSendType" SG_ 993 FeatNoDsmActl 3;
BA_ "CrossOver_InfoCAN" SG_ 993 FeatNoDsmActl 1;
BA_ "U_P702_MY2021_Tx" SG_ 993 FeatConfigDsmActl 1;
BA_ "U_CX727_MY2021_Tx" SG_ 993 FeatConfigDsmActl 1;
BA_ "U_CX430_MY2021_Tx" SG_ 993 FeatConfigDsmActl 1;
BA_ "U_U611_U625_MY20_Phev_Tx" SG_ 993 FeatConfigDsmActl 1;
BA_ "U_CX482_CX483_MY20_Tx" SG_ 993 FeatConfigDsmActl 1;
BA_ "U_U611_U625_MY20_Hev_Tx" SG_ 993 FeatConfigDsmActl 1;
BA_ "U_U611_U625_MY20_Gas_Tx" SG_ 993 FeatConfigDsmActl 1;
BA_ "U_C490_MY18_Tx" SG_ 993 FeatConfigDsmActl 1;
BA_ "GenSigSendType" SG_ 993 FeatConfigDsmActl 3;
BA_ "CrossOver_InfoCAN" SG_ 993 FeatConfigDsmActl 1;
BA_ "U_P702_MY2021_Tx" SG_ 1881 TesterPhysicalResRTM 1;
BA_ "U_CX727_MY2021_Tx" SG_ 1881 TesterPhysicalResRTM 1;
BA_ "U_VN127_MY20_Tx" SG_ 1881 TesterPhysicalResRTM 1;
BA_ "U_H567_MY20_Tx" SG_ 1881 TesterPhysicalResRTM 1;
BA_ "U_CX430_MY2021_Tx" SG_ 1881 TesterPhysicalResRTM 1;
BA_ "U_U611_U625_MY20_Phev_Tx" SG_ 1881 TesterPhysicalResRTM 1;
BA_ "U_CX482_CX483_MY20_Tx" SG_ 1881 TesterPhysicalResRTM 1;
BA_ "U_U611_U625_MY20_Hev_Tx" SG_ 1881 TesterPhysicalResRTM 1;
BA_ "U_U611_U625_MY20_Gas_Tx" SG_ 1881 TesterPhysicalResRTM 1;
BA_ "U_C519_MY18_5_Gas_Tx" SG_ 1881 TesterPhysicalResRTM 1;
BA_ "U_C519_MY18_5_Diesel_Tx" SG_ 1881 TesterPhysicalResRTM 1;
BA_ "U_B515_MCA_MY17_Gas_Tx" SG_ 1881 TesterPhysicalResRTM 1;
BA_ "U_B515_MCA_MY17_Diesel_Tx" SG_ 1881 TesterPhysicalResRTM 1;
BA_ "U_B479_MY17_Diesel_Tx" SG_ 1881 TesterPhysicalResRTM 1;
BA_ "U_B479_MY17_Gas_Tx" SG_ 1881 TesterPhysicalResRTM 1;
BA_ "GenSigSendType" SG_ 1881 TesterPhysicalResRTM 3;
BA_ "U_P702_MY2021_Rx" SG_ 1873 TesterPhysicalReqRTM 1;
BA_ "U_CX727_MY2021_Rx" SG_ 1873 TesterPhysicalReqRTM 1;
BA_ "U_VN127_MY20_Rx" SG_ 1873 TesterPhysicalReqRTM 1;
BA_ "U_H567_MY20_Rx" SG_ 1873 TesterPhysicalReqRTM 1;
BA_ "U_CX430_MY2021_Rx" SG_ 1873 TesterPhysicalReqRTM 1;
BA_ "U_U611_U625_MY20_Phev_Rx" SG_ 1873 TesterPhysicalReqRTM 1;
BA_ "U_CX482_CX483_MY20_Rx" SG_ 1873 TesterPhysicalReqRTM 1;
BA_ "U_U611_U625_MY20_Hev_Rx" SG_ 1873 TesterPhysicalReqRTM 1;
BA_ "U_U611_U625_MY20_Gas_Rx" SG_ 1873 TesterPhysicalReqRTM 1;
BA_ "U_C519_MY18_5_Gas_Rx" SG_ 1873 TesterPhysicalReqRTM 1;
BA_ "U_C519_MY18_5_Diesel_Rx" SG_ 1873 TesterPhysicalReqRTM 1;
BA_ "U_B515_MCA_MY17_Gas_Rx" SG_ 1873 TesterPhysicalReqRTM 1;
BA_ "U_B515_MCA_MY17_Diesel_Rx" SG_ 1873 TesterPhysicalReqRTM 1;
BA_ "U_B479_MY17_Diesel_Rx" SG_ 1873 TesterPhysicalReqRTM 1;
BA_ "U_B479_MY17_Gas_Rx" SG_ 1873 TesterPhysicalReqRTM 1;
BA_ "GenSigSendType" SG_ 1873 TesterPhysicalReqRTM 3;
BA_ "U_B562_MY18_Diesel_Rx" SG_ 2015 TesterFunctionalReq 1;
BA_ "U_B500_MY18_Diesel_Rx" SG_ 2015 TesterFunctionalReq 1;
BA_ "U_B500_MY18_Gas_Rx" SG_ 2015 TesterFunctionalReq 1;
BA_ "U_B562_MY18_Gas_Rx" SG_ 2015 TesterFunctionalReq 1;
BA_ "U_VN127_MY20_Rx" SG_ 2015 TesterFunctionalReq 1;
BA_ "U_H567_MY20_Rx" SG_ 2015 TesterFunctionalReq 1;
BA_ "U_C519_MY18_5_Gas_Rx" SG_ 2015 TesterFunctionalReq 1;
BA_ "U_C519_MY18_5_Diesel_Rx" SG_ 2015 TesterFunctionalReq 1;
BA_ "U_B515_MCA_MY17_Gas_Rx" SG_ 2015 TesterFunctionalReq 1;
BA_ "U_B515_MCA_MY17_Diesel_Rx" SG_ 2015 TesterFunctionalReq 1;
BA_ "U_B479_MY17_Diesel_Rx" SG_ 2015 TesterFunctionalReq 1;
BA_ "U_B479_MY17_Gas_Rx" SG_ 2015 TesterFunctionalReq 1;
BA_ "U_CX727_MY2021_Rx" SG_ 2015 TesterFunctionalReq 1;
BA_ "U_CX430_MY2021_Rx" SG_ 2015 TesterFunctionalReq 1;
BA_ "U_C490_MY18_Rx" SG_ 2015 TesterFunctionalReq 1;
BA_ "U_P702_MY2021_Rx" SG_ 2015 TesterFunctionalReq 1;
BA_ "U_U611_U625_MY20_Phev_Rx" SG_ 2015 TesterFunctionalReq 1;
BA_ "U_CX482_CX483_MY20_Rx" SG_ 2015 TesterFunctionalReq 1;
BA_ "U_U611_U625_MY20_Hev_Rx" SG_ 2015 TesterFunctionalReq 1;
BA_ "U_U611_U625_MY20_Gas_Rx" SG_ 2015 TesterFunctionalReq 1;
BA_ "GenSigSendType" SG_ 2015 TesterFunctionalReq 3;
BA_ "CrossOver_InfoCAN" SG_ 2015 TesterFunctionalReq 1;
BA_ "GenSigSendType" SG_ 320 PwSldDrIntSwL_B_Stat 3;
BA_ "ContentDependant" SG_ 320 PwSldDrIntSwL_B_Stat 1;
BA_ "WakeupSignal" SG_ 320 PwSldDrIntSwL_B_Stat 1;
BA_ "GenSigSendType" SG_ 320 LPwrSlideDr_Unlock_Rq 3;
BA_ "ContentDependant" SG_ 320 LPwrSlideDr_Unlock_Rq 1;
BA_ "WakeupSignal" SG_ 320 LPwrSlideDr_Unlock_Rq 1;
BA_ "GenSigSendType" SG_ 313 PwSldDrIntSwR_B_Stat 3;
BA_ "ContentDependant" SG_ 313 PwSldDrIntSwR_B_Stat 1;
BA_ "WakeupSignal" SG_ 313 PwSldDrIntSwR_B_Stat 1;
BA_ "GenSigSendType" SG_ 313 RPwrSlideDr_Unlock_Rq 3;
BA_ "ContentDependant" SG_ 313 RPwrSlideDr_Unlock_Rq 1;
BA_ "WakeupSignal" SG_ 313 RPwrSlideDr_Unlock_Rq 1;
BA_ "U_U611_U625_MY20_Gas_Rx" SG_ 806 SnowPlowMde_B_Enbl 1;
BA_ "U_U611_U625_MY20_Hev_Rx" SG_ 806 SnowPlowMde_B_Enbl 1;
BA_ "U_CX482_CX483_MY20_Rx" SG_ 806 SnowPlowMde_B_Enbl 1;
BA_ "U_U611_U625_MY20_Phev_Rx" SG_ 806 SnowPlowMde_B_Enbl 1;
BA_ "U_P702_MY2021_Rx" SG_ 806 SnowPlowMde_B_Enbl 1;
BA_ "U_P702_MY2021_Tx" SG_ 806 ClimtHeat_D_Rq 1;
BA_ "U_CX727_MY2021_Tx" SG_ 806 ClimtHeat_D_Rq 1;
BA_ "U_H567_MY20_Tx" SG_ 806 ClimtHeat_D_Rq 1;
BA_ "U_CX430_MY2021_Tx" SG_ 806 ClimtHeat_D_Rq 1;
BA_ "U_U611_U625_MY20_Phev_Tx" SG_ 806 ClimtHeat_D_Rq 1;
BA_ "U_B562_MY18_Diesel_Tx" SG_ 806 ClimtHeat_D_Rq 1;
BA_ "U_CX482_CX483_MY20_Tx" SG_ 806 ClimtHeat_D_Rq 1;
BA_ "U_U611_U625_MY20_Hev_Tx" SG_ 806 ClimtHeat_D_Rq 1;
BA_ "U_U611_U625_MY20_Gas_Tx" SG_ 806 ClimtHeat_D_Rq 1;
BA_ "U_B500_MY18_Diesel_Tx" SG_ 806 ClimtHeat_D_Rq 1;
BA_ "U_B500_MY18_Gas_Tx" SG_ 806 ClimtHeat_D_Rq 1;
BA_ "U_C490_MY18_Tx" SG_ 806 ClimtHeat_D_Rq 1;
BA_ "U_B562_MY18_Gas_Tx" SG_ 806 ClimtHeat_D_Rq 1;
BA_ "U_C519_MY18_5_Gas_Tx" SG_ 806 ClimtHeat_D_Rq 1;
BA_ "U_C519_MY18_5_Diesel_Tx" SG_ 806 ClimtHeat_D_Rq 1;
BA_ "U_B515_MCA_MY17_Gas_Tx" SG_ 806 ClimtHeat_D_Rq 1;
BA_ "U_B515_MCA_MY17_Diesel_Tx" SG_ 806 ClimtHeat_D_Rq 1;
BA_ "U_B479_MY17_Diesel_Tx" SG_ 806 ClimtHeat_D_Rq 1;
BA_ "U_B479_MY17_Gas_Tx" SG_ 806 ClimtHeat_D_Rq 1;
BA_ "U_P702_MY2021_Tx" SG_ 806 ClimtCool_D_Rq 1;
BA_ "U_CX727_MY2021_Tx" SG_ 806 ClimtCool_D_Rq 1;
BA_ "U_CX430_MY2021_Tx" SG_ 806 ClimtCool_D_Rq 1;
BA_ "U_U611_U625_MY20_Phev_Tx" SG_ 806 ClimtCool_D_Rq 1;
BA_ "U_B562_MY18_Diesel_Tx" SG_ 806 ClimtCool_D_Rq 1;
BA_ "U_CX482_CX483_MY20_Tx" SG_ 806 ClimtCool_D_Rq 1;
BA_ "U_U611_U625_MY20_Hev_Tx" SG_ 806 ClimtCool_D_Rq 1;
BA_ "U_U611_U625_MY20_Gas_Tx" SG_ 806 ClimtCool_D_Rq 1;
BA_ "U_B500_MY18_Diesel_Tx" SG_ 806 ClimtCool_D_Rq 1;
BA_ "U_B500_MY18_Gas_Tx" SG_ 806 ClimtCool_D_Rq 1;
BA_ "U_C490_MY18_Tx" SG_ 806 ClimtCool_D_Rq 1;
BA_ "U_B562_MY18_Gas_Tx" SG_ 806 ClimtCool_D_Rq 1;
BA_ "U_C519_MY18_5_Gas_Tx" SG_ 806 ClimtCool_D_Rq 1;
BA_ "U_C519_MY18_5_Diesel_Tx" SG_ 806 ClimtCool_D_Rq 1;
BA_ "U_B515_MCA_MY17_Gas_Tx" SG_ 806 ClimtCool_D_Rq 1;
BA_ "U_B515_MCA_MY17_Diesel_Tx" SG_ 806 ClimtCool_D_Rq 1;
BA_ "U_B479_MY17_Diesel_Tx" SG_ 806 ClimtCool_D_Rq 1;
BA_ "U_B479_MY17_Gas_Tx" SG_ 806 ClimtCool_D_Rq 1;
BA_ "U_P702_MY2021_Tx" SG_ 806 HvacEvap_Te_Rq 1;
BA_ "U_CX727_MY2021_Tx" SG_ 806 HvacEvap_Te_Rq 1;
BA_ "U_H567_MY20_Tx" SG_ 806 HvacEvap_Te_Rq 1;
BA_ "U_CX430_MY2021_Tx" SG_ 806 HvacEvap_Te_Rq 1;
BA_ "U_U611_U625_MY20_Phev_Tx" SG_ 806 HvacEvap_Te_Rq 1;
BA_ "U_B562_MY18_Diesel_Tx" SG_ 806 HvacEvap_Te_Rq 1;
BA_ "U_CX482_CX483_MY20_Tx" SG_ 806 HvacEvap_Te_Rq 1;
BA_ "U_U611_U625_MY20_Hev_Tx" SG_ 806 HvacEvap_Te_Rq 1;
BA_ "U_U611_U625_MY20_Gas_Tx" SG_ 806 HvacEvap_Te_Rq 1;
BA_ "U_B500_MY18_Diesel_Tx" SG_ 806 HvacEvap_Te_Rq 1;
BA_ "U_B500_MY18_Gas_Tx" SG_ 806 HvacEvap_Te_Rq 1;
BA_ "U_C490_MY18_Tx" SG_ 806 HvacEvap_Te_Rq 1;
BA_ "U_B562_MY18_Gas_Tx" SG_ 806 HvacEvap_Te_Rq 1;
BA_ "U_C519_MY18_5_Gas_Tx" SG_ 806 HvacEvap_Te_Rq 1;
BA_ "U_C519_MY18_5_Diesel_Tx" SG_ 806 HvacEvap_Te_Rq 1;
BA_ "U_B515_MCA_MY17_Gas_Tx" SG_ 806 HvacEvap_Te_Rq 1;
BA_ "U_B515_MCA_MY17_Diesel_Tx" SG_ 806 HvacEvap_Te_Rq 1;
BA_ "U_B479_MY17_Diesel_Tx" SG_ 806 HvacEvap_Te_Rq 1;
BA_ "U_B479_MY17_Gas_Tx" SG_ 806 HvacEvap_Te_Rq 1;
BA_ "GenSigStartValue" SG_ 806 HvacEvap_Te_Rq 400;
BA_ "U_P702_MY2021_Tx" SG_ 806 HvacEvap_Te_Actl 1;
BA_ "U_CX727_MY2021_Tx" SG_ 806 HvacEvap_Te_Actl 1;
BA_ "U_H567_MY20_Tx" SG_ 806 HvacEvap_Te_Actl 1;
BA_ "U_CX430_MY2021_Tx" SG_ 806 HvacEvap_Te_Actl 1;
BA_ "U_U611_U625_MY20_Phev_Tx" SG_ 806 HvacEvap_Te_Actl 1;
BA_ "U_B562_MY18_Diesel_Tx" SG_ 806 HvacEvap_Te_Actl 1;
BA_ "U_CX482_CX483_MY20_Tx" SG_ 806 HvacEvap_Te_Actl 1;
BA_ "U_U611_U625_MY20_Hev_Tx" SG_ 806 HvacEvap_Te_Actl 1;
BA_ "U_U611_U625_MY20_Gas_Tx" SG_ 806 HvacEvap_Te_Actl 1;
BA_ "U_B500_MY18_Diesel_Tx" SG_ 806 HvacEvap_Te_Actl 1;
BA_ "U_B500_MY18_Gas_Tx" SG_ 806 HvacEvap_Te_Actl 1;
BA_ "U_C490_MY18_Tx" SG_ 806 HvacEvap_Te_Actl 1;
BA_ "U_B562_MY18_Gas_Tx" SG_ 806 HvacEvap_Te_Actl 1;
BA_ "U_C519_MY18_5_Gas_Tx" SG_ 806 HvacEvap_Te_Actl 1;
BA_ "U_C519_MY18_5_Diesel_Tx" SG_ 806 HvacEvap_Te_Actl 1;
BA_ "U_B515_MCA_MY17_Gas_Tx" SG_ 806 HvacEvap_Te_Actl 1;
BA_ "U_B515_MCA_MY17_Diesel_Tx" SG_ 806 HvacEvap_Te_Actl 1;
BA_ "U_B479_MY17_Diesel_Tx" SG_ 806 HvacEvap_Te_Actl 1;
BA_ "U_B479_MY17_Gas_Tx" SG_ 806 HvacEvap_Te_Actl 1;
BA_ "GenSigStartValue" SG_ 806 HvacEvap_Te_Actl 400;
BA_ "U_P702_MY2021_Tx" SG_ 806 HvacAirCond_B_Rq 1;
BA_ "U_CX727_MY2021_Tx" SG_ 806 HvacAirCond_B_Rq 1;
BA_ "U_H567_MY20_Tx" SG_ 806 HvacAirCond_B_Rq 1;
BA_ "U_CX430_MY2021_Tx" SG_ 806 HvacAirCond_B_Rq 1;
BA_ "U_U611_U625_MY20_Phev_Tx" SG_ 806 HvacAirCond_B_Rq 1;
BA_ "U_B562_MY18_Diesel_Tx" SG_ 806 HvacAirCond_B_Rq 1;
BA_ "U_CX482_CX483_MY20_Tx" SG_ 806 HvacAirCond_B_Rq 1;
BA_ "U_U611_U625_MY20_Hev_Tx" SG_ 806 HvacAirCond_B_Rq 1;
BA_ "U_U611_U625_MY20_Gas_Tx" SG_ 806 HvacAirCond_B_Rq 1;
BA_ "U_B500_MY18_Diesel_Tx" SG_ 806 HvacAirCond_B_Rq 1;
BA_ "U_B500_MY18_Gas_Tx" SG_ 806 HvacAirCond_B_Rq 1;
BA_ "U_C490_MY18_Tx" SG_ 806 HvacAirCond_B_Rq 1;
BA_ "U_B562_MY18_Gas_Tx" SG_ 806 HvacAirCond_B_Rq 1;
BA_ "U_C519_MY18_5_Gas_Tx" SG_ 806 HvacAirCond_B_Rq 1;
BA_ "U_C519_MY18_5_Diesel_Tx" SG_ 806 HvacAirCond_B_Rq 1;
BA_ "U_B515_MCA_MY17_Gas_Tx" SG_ 806 HvacAirCond_B_Rq 1;
BA_ "U_B515_MCA_MY17_Diesel_Tx" SG_ 806 HvacAirCond_B_Rq 1;
BA_ "U_B479_MY17_Diesel_Tx" SG_ 806 HvacAirCond_B_Rq 1;
BA_ "U_B479_MY17_Gas_Tx" SG_ 806 HvacAirCond_B_Rq 1;
BA_ "U_P702_MY2021_Tx" SG_ 806 HvacEvap_Te_Offst 1;
BA_ "U_CX727_MY2021_Tx" SG_ 806 HvacEvap_Te_Offst 1;
BA_ "U_H567_MY20_Tx" SG_ 806 HvacEvap_Te_Offst 1;
BA_ "U_CX430_MY2021_Tx" SG_ 806 HvacEvap_Te_Offst 1;
BA_ "U_U611_U625_MY20_Phev_Tx" SG_ 806 HvacEvap_Te_Offst 1;
BA_ "U_B562_MY18_Diesel_Tx" SG_ 806 HvacEvap_Te_Offst 1;
BA_ "U_CX482_CX483_MY20_Tx" SG_ 806 HvacEvap_Te_Offst 1;
BA_ "U_U611_U625_MY20_Hev_Tx" SG_ 806 HvacEvap_Te_Offst 1;
BA_ "U_U611_U625_MY20_Gas_Tx" SG_ 806 HvacEvap_Te_Offst 1;
BA_ "U_B500_MY18_Diesel_Tx" SG_ 806 HvacEvap_Te_Offst 1;
BA_ "U_B500_MY18_Gas_Tx" SG_ 806 HvacEvap_Te_Offst 1;
BA_ "U_C490_MY18_Tx" SG_ 806 HvacEvap_Te_Offst 1;
BA_ "U_B562_MY18_Gas_Tx" SG_ 806 HvacEvap_Te_Offst 1;
BA_ "U_C519_MY18_5_Gas_Tx" SG_ 806 HvacEvap_Te_Offst 1;
BA_ "U_C519_MY18_5_Diesel_Tx" SG_ 806 HvacEvap_Te_Offst 1;
BA_ "U_B515_MCA_MY17_Gas_Tx" SG_ 806 HvacEvap_Te_Offst 1;
BA_ "U_B515_MCA_MY17_Diesel_Tx" SG_ 806 HvacEvap_Te_Offst 1;
BA_ "U_B479_MY17_Diesel_Tx" SG_ 806 HvacEvap_Te_Offst 1;
BA_ "U_B479_MY17_Gas_Tx" SG_ 806 HvacEvap_Te_Offst 1;
BA_ "GenSigStartValue" SG_ 806 HvacEvap_Te_Offst 400;
BA_ "U_P702_MY2021_Rx" SG_ 950 RemoteKey_Info_TIC 1;
BA_ "U_CX727_MY2021_Rx" SG_ 950 RemoteKey_Info_TIC 1;
BA_ "U_VN127_MY20_Rx" SG_ 950 RemoteKey_Info_TIC 1;
BA_ "U_H567_MY20_Rx" SG_ 950 RemoteKey_Info_TIC 1;
BA_ "U_CX430_MY2021_Rx" SG_ 950 RemoteKey_Info_TIC 1;
BA_ "U_U611_U625_MY20_Phev_Rx" SG_ 950 RemoteKey_Info_TIC 1;
BA_ "U_CX482_CX483_MY20_Rx" SG_ 950 RemoteKey_Info_TIC 1;
BA_ "U_U611_U625_MY20_Hev_Rx" SG_ 950 RemoteKey_Info_TIC 1;
BA_ "U_U611_U625_MY20_Gas_Rx" SG_ 950 RemoteKey_Info_TIC 1;
BA_ "U_C519_MY18_5_Gas_Rx" SG_ 950 RemoteKey_Info_TIC 1;
BA_ "U_C519_MY18_5_Diesel_Rx" SG_ 950 RemoteKey_Info_TIC 1;
BA_ "U_B515_MCA_MY17_Gas_Rx" SG_ 950 RemoteKey_Info_TIC 1;
BA_ "U_B515_MCA_MY17_Diesel_Rx" SG_ 950 RemoteKey_Info_TIC 1;
BA_ "U_B479_MY17_Diesel_Rx" SG_ 950 RemoteKey_Info_TIC 1;
BA_ "U_B479_MY17_Gas_Rx" SG_ 950 RemoteKey_Info_TIC 1;
BA_ "U_P702_MY2021_Rx" SG_ 950 RemoteKey_Info_MaxInd 1;
BA_ "U_CX727_MY2021_Rx" SG_ 950 RemoteKey_Info_MaxInd 1;
BA_ "U_VN127_MY20_Rx" SG_ 950 RemoteKey_Info_MaxInd 1;
BA_ "U_H567_MY20_Rx" SG_ 950 RemoteKey_Info_MaxInd 1;
BA_ "U_CX430_MY2021_Rx" SG_ 950 RemoteKey_Info_MaxInd 1;
BA_ "U_U611_U625_MY20_Phev_Rx" SG_ 950 RemoteKey_Info_MaxInd 1;
BA_ "U_CX482_CX483_MY20_Rx" SG_ 950 RemoteKey_Info_MaxInd 1;
BA_ "U_U611_U625_MY20_Hev_Rx" SG_ 950 RemoteKey_Info_MaxInd 1;
BA_ "U_U611_U625_MY20_Gas_Rx" SG_ 950 RemoteKey_Info_MaxInd 1;
BA_ "U_C519_MY18_5_Gas_Rx" SG_ 950 RemoteKey_Info_MaxInd 1;
BA_ "U_C519_MY18_5_Diesel_Rx" SG_ 950 RemoteKey_Info_MaxInd 1;
BA_ "U_B515_MCA_MY17_Gas_Rx" SG_ 950 RemoteKey_Info_MaxInd 1;
BA_ "U_B515_MCA_MY17_Diesel_Rx" SG_ 950 RemoteKey_Info_MaxInd 1;
BA_ "U_B479_MY17_Diesel_Rx" SG_ 950 RemoteKey_Info_MaxInd 1;
BA_ "U_B479_MY17_Gas_Rx" SG_ 950 RemoteKey_Info_MaxInd 1;
BA_ "U_P702_MY2021_Rx" SG_ 950 RemoteKey_Info_Index 1;
BA_ "U_CX727_MY2021_Rx" SG_ 950 RemoteKey_Info_Index 1;
BA_ "U_VN127_MY20_Rx" SG_ 950 RemoteKey_Info_Index 1;
BA_ "U_H567_MY20_Rx" SG_ 950 RemoteKey_Info_Index 1;
BA_ "U_CX430_MY2021_Rx" SG_ 950 RemoteKey_Info_Index 1;
BA_ "U_U611_U625_MY20_Phev_Rx" SG_ 950 RemoteKey_Info_Index 1;
BA_ "U_CX482_CX483_MY20_Rx" SG_ 950 RemoteKey_Info_Index 1;
BA_ "U_U611_U625_MY20_Hev_Rx" SG_ 950 RemoteKey_Info_Index 1;
BA_ "U_U611_U625_MY20_Gas_Rx" SG_ 950 RemoteKey_Info_Index 1;
BA_ "U_C519_MY18_5_Gas_Rx" SG_ 950 RemoteKey_Info_Index 1;
BA_ "U_C519_MY18_5_Diesel_Rx" SG_ 950 RemoteKey_Info_Index 1;
BA_ "U_B515_MCA_MY17_Gas_Rx" SG_ 950 RemoteKey_Info_Index 1;
BA_ "U_B515_MCA_MY17_Diesel_Rx" SG_ 950 RemoteKey_Info_Index 1;
BA_ "U_B479_MY17_Diesel_Rx" SG_ 950 RemoteKey_Info_Index 1;
BA_ "U_B479_MY17_Gas_Rx" SG_ 950 RemoteKey_Info_Index 1;
BA_ "U_P702_MY2021_Rx" SG_ 950 TirePress_Filter_Ctrl 1;
BA_ "U_CX727_MY2021_Rx" SG_ 950 TirePress_Filter_Ctrl 1;
BA_ "U_VN127_MY20_Rx" SG_ 950 TirePress_Filter_Ctrl 1;
BA_ "U_H567_MY20_Rx" SG_ 950 TirePress_Filter_Ctrl 1;
BA_ "U_CX430_MY2021_Rx" SG_ 950 TirePress_Filter_Ctrl 1;
BA_ "U_U611_U625_MY20_Phev_Rx" SG_ 950 TirePress_Filter_Ctrl 1;
BA_ "U_CX482_CX483_MY20_Rx" SG_ 950 TirePress_Filter_Ctrl 1;
BA_ "U_U611_U625_MY20_Hev_Rx" SG_ 950 TirePress_Filter_Ctrl 1;
BA_ "U_U611_U625_MY20_Gas_Rx" SG_ 950 TirePress_Filter_Ctrl 1;
BA_ "U_C519_MY18_5_Gas_Rx" SG_ 950 TirePress_Filter_Ctrl 1;
BA_ "U_C519_MY18_5_Diesel_Rx" SG_ 950 TirePress_Filter_Ctrl 1;
BA_ "U_B515_MCA_MY17_Gas_Rx" SG_ 950 TirePress_Filter_Ctrl 1;
BA_ "U_B515_MCA_MY17_Diesel_Rx" SG_ 950 TirePress_Filter_Ctrl 1;
BA_ "U_B479_MY17_Diesel_Rx" SG_ 950 TirePress_Filter_Ctrl 1;
BA_ "U_B479_MY17_Gas_Rx" SG_ 950 TirePress_Filter_Ctrl 1;
BA_ "GenSigStartValue" SG_ 950 TirePress_Filter_Ctrl 2;
BA_ "U_P702_MY2021_Rx" SG_ 857 LHS_Temp_Disp_Digit3 1;
BA_ "U_CX727_MY2021_Rx" SG_ 857 LHS_Temp_Disp_Digit3 1;
BA_ "U_CX430_MY2021_Rx" SG_ 857 LHS_Temp_Disp_Digit3 1;
BA_ "U_U611_U625_MY20_Phev_Rx" SG_ 857 LHS_Temp_Disp_Digit3 1;
BA_ "U_B562_MY18_Diesel_Rx" SG_ 857 LHS_Temp_Disp_Digit3 1;
BA_ "U_CX482_CX483_MY20_Rx" SG_ 857 LHS_Temp_Disp_Digit3 1;
BA_ "U_U611_U625_MY20_Hev_Rx" SG_ 857 LHS_Temp_Disp_Digit3 1;
BA_ "U_U611_U625_MY20_Gas_Rx" SG_ 857 LHS_Temp_Disp_Digit3 1;
BA_ "U_B500_MY18_Diesel_Rx" SG_ 857 LHS_Temp_Disp_Digit3 1;
BA_ "U_B500_MY18_Gas_Rx" SG_ 857 LHS_Temp_Disp_Digit3 1;
BA_ "U_B562_MY18_Gas_Rx" SG_ 857 LHS_Temp_Disp_Digit3 1;
BA_ "U_C519_MY18_5_Gas_Rx" SG_ 857 LHS_Temp_Disp_Digit3 1;
BA_ "U_C519_MY18_5_Diesel_Rx" SG_ 857 LHS_Temp_Disp_Digit3 1;
BA_ "U_B515_MCA_MY17_Gas_Rx" SG_ 857 LHS_Temp_Disp_Digit3 1;
BA_ "U_B515_MCA_MY17_Diesel_Rx" SG_ 857 LHS_Temp_Disp_Digit3 1;
BA_ "U_B479_MY17_Diesel_Rx" SG_ 857 LHS_Temp_Disp_Digit3 1;
BA_ "U_B479_MY17_Gas_Rx" SG_ 857 LHS_Temp_Disp_Digit3 1;
BA_ "CrossOver_InfoCAN" SG_ 857 LHS_Temp_Disp_Digit3 1;
BA_ "U_P702_MY2021_Rx" SG_ 857 LHS_Temp_Disp_Digit2 1;
BA_ "U_CX727_MY2021_Rx" SG_ 857 LHS_Temp_Disp_Digit2 1;
BA_ "U_CX430_MY2021_Rx" SG_ 857 LHS_Temp_Disp_Digit2 1;
BA_ "U_U611_U625_MY20_Phev_Rx" SG_ 857 LHS_Temp_Disp_Digit2 1;
BA_ "U_B562_MY18_Diesel_Rx" SG_ 857 LHS_Temp_Disp_Digit2 1;
BA_ "U_CX482_CX483_MY20_Rx" SG_ 857 LHS_Temp_Disp_Digit2 1;
BA_ "U_U611_U625_MY20_Hev_Rx" SG_ 857 LHS_Temp_Disp_Digit2 1;
BA_ "U_U611_U625_MY20_Gas_Rx" SG_ 857 LHS_Temp_Disp_Digit2 1;
BA_ "U_B500_MY18_Diesel_Rx" SG_ 857 LHS_Temp_Disp_Digit2 1;
BA_ "U_B500_MY18_Gas_Rx" SG_ 857 LHS_Temp_Disp_Digit2 1;
BA_ "U_B562_MY18_Gas_Rx" SG_ 857 LHS_Temp_Disp_Digit2 1;
BA_ "U_C519_MY18_5_Gas_Rx" SG_ 857 LHS_Temp_Disp_Digit2 1;
BA_ "U_C519_MY18_5_Diesel_Rx" SG_ 857 LHS_Temp_Disp_Digit2 1;
BA_ "U_B515_MCA_MY17_Gas_Rx" SG_ 857 LHS_Temp_Disp_Digit2 1;
BA_ "U_B515_MCA_MY17_Diesel_Rx" SG_ 857 LHS_Temp_Disp_Digit2 1;
BA_ "U_B479_MY17_Diesel_Rx" SG_ 857 LHS_Temp_Disp_Digit2 1;
BA_ "U_B479_MY17_Gas_Rx" SG_ 857 LHS_Temp_Disp_Digit2 1;
BA_ "CrossOver_InfoCAN" SG_ 857 LHS_Temp_Disp_Digit2 1;
BA_ "U_P702_MY2021_Rx" SG_ 857 LHS_Temp_Disp_Digit1 1;
BA_ "U_CX727_MY2021_Rx" SG_ 857 LHS_Temp_Disp_Digit1 1;
BA_ "U_CX430_MY2021_Rx" SG_ 857 LHS_Temp_Disp_Digit1 1;
BA_ "U_U611_U625_MY20_Phev_Rx" SG_ 857 LHS_Temp_Disp_Digit1 1;
BA_ "U_B562_MY18_Diesel_Rx" SG_ 857 LHS_Temp_Disp_Digit1 1;
BA_ "U_CX482_CX483_MY20_Rx" SG_ 857 LHS_Temp_Disp_Digit1 1;
BA_ "U_U611_U625_MY20_Hev_Rx" SG_ 857 LHS_Temp_Disp_Digit1 1;
BA_ "U_U611_U625_MY20_Gas_Rx" SG_ 857 LHS_Temp_Disp_Digit1 1;
BA_ "U_B500_MY18_Diesel_Rx" SG_ 857 LHS_Temp_Disp_Digit1 1;
BA_ "U_B500_MY18_Gas_Rx" SG_ 857 LHS_Temp_Disp_Digit1 1;
BA_ "U_B562_MY18_Gas_Rx" SG_ 857 LHS_Temp_Disp_Digit1 1;
BA_ "U_C519_MY18_5_Gas_Rx" SG_ 857 LHS_Temp_Disp_Digit1 1;
BA_ "U_C519_MY18_5_Diesel_Rx" SG_ 857 LHS_Temp_Disp_Digit1 1;
BA_ "U_B515_MCA_MY17_Gas_Rx" SG_ 857 LHS_Temp_Disp_Digit1 1;
BA_ "U_B515_MCA_MY17_Diesel_Rx" SG_ 857 LHS_Temp_Disp_Digit1 1;
BA_ "U_B479_MY17_Diesel_Rx" SG_ 857 LHS_Temp_Disp_Digit1 1;
BA_ "U_B479_MY17_Gas_Rx" SG_ 857 LHS_Temp_Disp_Digit1 1;
BA_ "CrossOver_InfoCAN" SG_ 857 LHS_Temp_Disp_Digit1 1;
BA_ "U_P702_MY2021_Rx" SG_ 857 Front_Blower_Ind 1;
BA_ "U_CX727_MY2021_Rx" SG_ 857 Front_Blower_Ind 1;
BA_ "U_CX430_MY2021_Rx" SG_ 857 Front_Blower_Ind 1;
BA_ "U_U611_U625_MY20_Phev_Rx" SG_ 857 Front_Blower_Ind 1;
BA_ "U_B562_MY18_Diesel_Rx" SG_ 857 Front_Blower_Ind 1;
BA_ "U_CX482_CX483_MY20_Rx" SG_ 857 Front_Blower_Ind 1;
BA_ "U_U611_U625_MY20_Hev_Rx" SG_ 857 Front_Blower_Ind 1;
BA_ "U_U611_U625_MY20_Gas_Rx" SG_ 857 Front_Blower_Ind 1;
BA_ "U_B500_MY18_Diesel_Rx" SG_ 857 Front_Blower_Ind 1;
BA_ "U_B500_MY18_Gas_Rx" SG_ 857 Front_Blower_Ind 1;
BA_ "U_B562_MY18_Gas_Rx" SG_ 857 Front_Blower_Ind 1;
BA_ "U_C519_MY18_5_Gas_Rx" SG_ 857 Front_Blower_Ind 1;
BA_ "U_C519_MY18_5_Diesel_Rx" SG_ 857 Front_Blower_Ind 1;
BA_ "U_B515_MCA_MY17_Gas_Rx" SG_ 857 Front_Blower_Ind 1;
BA_ "U_B515_MCA_MY17_Diesel_Rx" SG_ 857 Front_Blower_Ind 1;
BA_ "U_B479_MY17_Diesel_Rx" SG_ 857 Front_Blower_Ind 1;
BA_ "U_B479_MY17_Gas_Rx" SG_ 857 Front_Blower_Ind 1;
BA_ "GenSigStartValue" SG_ 857 Front_Blower_Ind 15;
BA_ "CrossOver_InfoCAN" SG_ 857 Front_Blower_Ind 1;
BA_ "U_P702_MY2021_Rx" SG_ 857 EATC_LHS_Unit 1;
BA_ "U_CX727_MY2021_Rx" SG_ 857 EATC_LHS_Unit 1;
BA_ "U_CX430_MY2021_Rx" SG_ 857 EATC_LHS_Unit 1;
BA_ "U_U611_U625_MY20_Phev_Rx" SG_ 857 EATC_LHS_Unit 1;
BA_ "U_B562_MY18_Diesel_Rx" SG_ 857 EATC_LHS_Unit 1;
BA_ "U_CX482_CX483_MY20_Rx" SG_ 857 EATC_LHS_Unit 1;
BA_ "U_U611_U625_MY20_Hev_Rx" SG_ 857 EATC_LHS_Unit 1;
BA_ "U_U611_U625_MY20_Gas_Rx" SG_ 857 EATC_LHS_Unit 1;
BA_ "U_B500_MY18_Diesel_Rx" SG_ 857 EATC_LHS_Unit 1;
BA_ "U_B500_MY18_Gas_Rx" SG_ 857 EATC_LHS_Unit 1;
BA_ "U_B562_MY18_Gas_Rx" SG_ 857 EATC_LHS_Unit 1;
BA_ "U_C519_MY18_5_Gas_Rx" SG_ 857 EATC_LHS_Unit 1;
BA_ "U_C519_MY18_5_Diesel_Rx" SG_ 857 EATC_LHS_Unit 1;
BA_ "U_B515_MCA_MY17_Gas_Rx" SG_ 857 EATC_LHS_Unit 1;
BA_ "U_B515_MCA_MY17_Diesel_Rx" SG_ 857 EATC_LHS_Unit 1;
BA_ "U_B479_MY17_Diesel_Rx" SG_ 857 EATC_LHS_Unit 1;
BA_ "U_B479_MY17_Gas_Rx" SG_ 857 EATC_LHS_Unit 1;
BA_ "CrossOver_InfoCAN" SG_ 857 EATC_LHS_Unit 1;
BA_ "CrossOver_InfoCAN" SG_ 856 Rr_Btn_Status_2nd 1;
BA_ "CrossOver_InfoCAN" SG_ 856 Rr_Btn_Status_1st 1;
BA_ "U_P702_MY2021_Rx" SG_ 856 Frt_Btn_Status_2nd 1;
BA_ "U_CX727_MY2021_Rx" SG_ 856 Frt_Btn_Status_2nd 1;
BA_ "U_CX430_MY2021_Rx" SG_ 856 Frt_Btn_Status_2nd 1;
BA_ "U_U611_U625_MY20_Phev_Rx" SG_ 856 Frt_Btn_Status_2nd 1;
BA_ "U_B562_MY18_Diesel_Rx" SG_ 856 Frt_Btn_Status_2nd 1;
BA_ "U_CX482_CX483_MY20_Rx" SG_ 856 Frt_Btn_Status_2nd 1;
BA_ "U_U611_U625_MY20_Hev_Rx" SG_ 856 Frt_Btn_Status_2nd 1;
BA_ "U_U611_U625_MY20_Gas_Rx" SG_ 856 Frt_Btn_Status_2nd 1;
BA_ "U_B500_MY18_Diesel_Rx" SG_ 856 Frt_Btn_Status_2nd 1;
BA_ "U_B500_MY18_Gas_Rx" SG_ 856 Frt_Btn_Status_2nd 1;
BA_ "U_B562_MY18_Gas_Rx" SG_ 856 Frt_Btn_Status_2nd 1;
BA_ "U_C519_MY18_5_Gas_Rx" SG_ 856 Frt_Btn_Status_2nd 1;
BA_ "U_C519_MY18_5_Diesel_Rx" SG_ 856 Frt_Btn_Status_2nd 1;
BA_ "U_B515_MCA_MY17_Gas_Rx" SG_ 856 Frt_Btn_Status_2nd 1;
BA_ "U_B515_MCA_MY17_Diesel_Rx" SG_ 856 Frt_Btn_Status_2nd 1;
BA_ "U_B479_MY17_Diesel_Rx" SG_ 856 Frt_Btn_Status_2nd 1;
BA_ "U_B479_MY17_Gas_Rx" SG_ 856 Frt_Btn_Status_2nd 1;
BA_ "CrossOver_InfoCAN" SG_ 856 Frt_Btn_Status_2nd 1;
BA_ "U_P702_MY2021_Rx" SG_ 856 Frt_Btn_Status_1st 1;
BA_ "U_CX727_MY2021_Rx" SG_ 856 Frt_Btn_Status_1st 1;
BA_ "U_CX430_MY2021_Rx" SG_ 856 Frt_Btn_Status_1st 1;
BA_ "U_U611_U625_MY20_Phev_Rx" SG_ 856 Frt_Btn_Status_1st 1;
BA_ "U_B562_MY18_Diesel_Rx" SG_ 856 Frt_Btn_Status_1st 1;
BA_ "U_CX482_CX483_MY20_Rx" SG_ 856 Frt_Btn_Status_1st 1;
BA_ "U_U611_U625_MY20_Hev_Rx" SG_ 856 Frt_Btn_Status_1st 1;
BA_ "U_U611_U625_MY20_Gas_Rx" SG_ 856 Frt_Btn_Status_1st 1;
BA_ "U_B500_MY18_Diesel_Rx" SG_ 856 Frt_Btn_Status_1st 1;
BA_ "U_B500_MY18_Gas_Rx" SG_ 856 Frt_Btn_Status_1st 1;
BA_ "U_B562_MY18_Gas_Rx" SG_ 856 Frt_Btn_Status_1st 1;
BA_ "U_C519_MY18_5_Gas_Rx" SG_ 856 Frt_Btn_Status_1st 1;
BA_ "U_C519_MY18_5_Diesel_Rx" SG_ 856 Frt_Btn_Status_1st 1;
BA_ "U_B515_MCA_MY17_Gas_Rx" SG_ 856 Frt_Btn_Status_1st 1;
BA_ "U_B515_MCA_MY17_Diesel_Rx" SG_ 856 Frt_Btn_Status_1st 1;
BA_ "U_B479_MY17_Diesel_Rx" SG_ 856 Frt_Btn_Status_1st 1;
BA_ "U_B479_MY17_Gas_Rx" SG_ 856 Frt_Btn_Status_1st 1;
BA_ "CrossOver_InfoCAN" SG_ 856 Frt_Btn_Status_1st 1;
BA_ "U_P702_MY2021_Rx" SG_ 856 Frt_Blower_Speed 1;
BA_ "U_CX727_MY2021_Rx" SG_ 856 Frt_Blower_Speed 1;
BA_ "U_CX430_MY2021_Rx" SG_ 856 Frt_Blower_Speed 1;
BA_ "U_U611_U625_MY20_Phev_Rx" SG_ 856 Frt_Blower_Speed 1;
BA_ "U_B562_MY18_Diesel_Rx" SG_ 856 Frt_Blower_Speed 1;
BA_ "U_CX482_CX483_MY20_Rx" SG_ 856 Frt_Blower_Speed 1;
BA_ "U_U611_U625_MY20_Hev_Rx" SG_ 856 Frt_Blower_Speed 1;
BA_ "U_U611_U625_MY20_Gas_Rx" SG_ 856 Frt_Blower_Speed 1;
BA_ "U_B500_MY18_Diesel_Rx" SG_ 856 Frt_Blower_Speed 1;
BA_ "U_B500_MY18_Gas_Rx" SG_ 856 Frt_Blower_Speed 1;
BA_ "U_B562_MY18_Gas_Rx" SG_ 856 Frt_Blower_Speed 1;
BA_ "U_C519_MY18_5_Gas_Rx" SG_ 856 Frt_Blower_Speed 1;
BA_ "U_C519_MY18_5_Diesel_Rx" SG_ 856 Frt_Blower_Speed 1;
BA_ "U_B515_MCA_MY17_Gas_Rx" SG_ 856 Frt_Blower_Speed 1;
BA_ "U_B515_MCA_MY17_Diesel_Rx" SG_ 856 Frt_Blower_Speed 1;
BA_ "U_B479_MY17_Diesel_Rx" SG_ 856 Frt_Blower_Speed 1;
BA_ "U_B479_MY17_Gas_Rx" SG_ 856 Frt_Blower_Speed 1;
BA_ "CrossOver_InfoCAN" SG_ 856 Frt_Blower_Speed 1;
BA_ "U_P702_MY2021_Rx" SG_ 856 Drv_Set_Temp 1;
BA_ "U_CX727_MY2021_Rx" SG_ 856 Drv_Set_Temp 1;
BA_ "U_CX430_MY2021_Rx" SG_ 856 Drv_Set_Temp 1;
BA_ "U_U611_U625_MY20_Phev_Rx" SG_ 856 Drv_Set_Temp 1;
BA_ "U_B562_MY18_Diesel_Rx" SG_ 856 Drv_Set_Temp 1;
BA_ "U_CX482_CX483_MY20_Rx" SG_ 856 Drv_Set_Temp 1;
BA_ "U_U611_U625_MY20_Hev_Rx" SG_ 856 Drv_Set_Temp 1;
BA_ "U_U611_U625_MY20_Gas_Rx" SG_ 856 Drv_Set_Temp 1;
BA_ "U_B500_MY18_Diesel_Rx" SG_ 856 Drv_Set_Temp 1;
BA_ "U_B500_MY18_Gas_Rx" SG_ 856 Drv_Set_Temp 1;
BA_ "U_B562_MY18_Gas_Rx" SG_ 856 Drv_Set_Temp 1;
BA_ "U_C519_MY18_5_Gas_Rx" SG_ 856 Drv_Set_Temp 1;
BA_ "U_C519_MY18_5_Diesel_Rx" SG_ 856 Drv_Set_Temp 1;
BA_ "U_B515_MCA_MY17_Gas_Rx" SG_ 856 Drv_Set_Temp 1;
BA_ "U_B515_MCA_MY17_Diesel_Rx" SG_ 856 Drv_Set_Temp 1;
BA_ "U_B479_MY17_Diesel_Rx" SG_ 856 Drv_Set_Temp 1;
BA_ "U_B479_MY17_Gas_Rx" SG_ 856 Drv_Set_Temp 1;
BA_ "CrossOver_InfoCAN" SG_ 856 Drv_Set_Temp 1;
BA_ "U_P702_MY2021_Tx" SG_ 854 CC_Fr_Stat_User_Adj 1;
BA_ "U_CX727_MY2021_Tx" SG_ 854 CC_Fr_Stat_User_Adj 1;
BA_ "U_CX430_MY2021_Tx" SG_ 854 CC_Fr_Stat_User_Adj 1;
BA_ "U_U611_U625_MY20_Phev_Tx" SG_ 854 CC_Fr_Stat_User_Adj 1;
BA_ "U_B562_MY18_Diesel_Tx" SG_ 854 CC_Fr_Stat_User_Adj 1;
BA_ "U_CX482_CX483_MY20_Tx" SG_ 854 CC_Fr_Stat_User_Adj 1;
BA_ "U_U611_U625_MY20_Hev_Tx" SG_ 854 CC_Fr_Stat_User_Adj 1;
BA_ "U_U611_U625_MY20_Gas_Tx" SG_ 854 CC_Fr_Stat_User_Adj 1;
BA_ "U_B500_MY18_Diesel_Tx" SG_ 854 CC_Fr_Stat_User_Adj 1;
BA_ "U_B500_MY18_Gas_Tx" SG_ 854 CC_Fr_Stat_User_Adj 1;
BA_ "U_B562_MY18_Gas_Tx" SG_ 854 CC_Fr_Stat_User_Adj 1;
BA_ "U_C519_MY18_5_Gas_Tx" SG_ 854 CC_Fr_Stat_User_Adj 1;
BA_ "U_C519_MY18_5_Diesel_Tx" SG_ 854 CC_Fr_Stat_User_Adj 1;
BA_ "U_B515_MCA_MY17_Gas_Tx" SG_ 854 CC_Fr_Stat_User_Adj 1;
BA_ "U_B515_MCA_MY17_Diesel_Tx" SG_ 854 CC_Fr_Stat_User_Adj 1;
BA_ "U_B479_MY17_Diesel_Tx" SG_ 854 CC_Fr_Stat_User_Adj 1;
BA_ "U_B479_MY17_Gas_Tx" SG_ 854 CC_Fr_Stat_User_Adj 1;
BA_ "GenSigSendType" SG_ 854 CC_Fr_Stat_User_Adj 3;
BA_ "CrossOver_InfoCAN" SG_ 854 CC_Fr_Stat_User_Adj 1;
BA_ "U_P702_MY2021_Tx" SG_ 854 Front_Blower_Indicate 1;
BA_ "U_CX727_MY2021_Tx" SG_ 854 Front_Blower_Indicate 1;
BA_ "U_CX430_MY2021_Tx" SG_ 854 Front_Blower_Indicate 1;
BA_ "U_U611_U625_MY20_Phev_Tx" SG_ 854 Front_Blower_Indicate 1;
BA_ "U_B562_MY18_Diesel_Tx" SG_ 854 Front_Blower_Indicate 1;
BA_ "U_CX482_CX483_MY20_Tx" SG_ 854 Front_Blower_Indicate 1;
BA_ "U_U611_U625_MY20_Hev_Tx" SG_ 854 Front_Blower_Indicate 1;
BA_ "U_U611_U625_MY20_Gas_Tx" SG_ 854 Front_Blower_Indicate 1;
BA_ "U_B500_MY18_Diesel_Tx" SG_ 854 Front_Blower_Indicate 1;
BA_ "U_B500_MY18_Gas_Tx" SG_ 854 Front_Blower_Indicate 1;
BA_ "U_B562_MY18_Gas_Tx" SG_ 854 Front_Blower_Indicate 1;
BA_ "U_C519_MY18_5_Gas_Tx" SG_ 854 Front_Blower_Indicate 1;
BA_ "U_C519_MY18_5_Diesel_Tx" SG_ 854 Front_Blower_Indicate 1;
BA_ "U_B515_MCA_MY17_Gas_Tx" SG_ 854 Front_Blower_Indicate 1;
BA_ "U_B515_MCA_MY17_Diesel_Tx" SG_ 854 Front_Blower_Indicate 1;
BA_ "U_B479_MY17_Diesel_Tx" SG_ 854 Front_Blower_Indicate 1;
BA_ "U_B479_MY17_Gas_Tx" SG_ 854 Front_Blower_Indicate 1;
BA_ "GenSigSendType" SG_ 854 Front_Blower_Indicate 3;
BA_ "GenSigStartValue" SG_ 854 Front_Blower_Indicate 15;
BA_ "CrossOver_InfoCAN" SG_ 854 Front_Blower_Indicate 1;
BA_ "U_P702_MY2021_Tx" SG_ 854 CC_Diagnostics_Active 1;
BA_ "U_CX727_MY2021_Tx" SG_ 854 CC_Diagnostics_Active 1;
BA_ "U_CX430_MY2021_Tx" SG_ 854 CC_Diagnostics_Active 1;
BA_ "U_U611_U625_MY20_Phev_Tx" SG_ 854 CC_Diagnostics_Active 1;
BA_ "U_B562_MY18_Diesel_Tx" SG_ 854 CC_Diagnostics_Active 1;
BA_ "U_CX482_CX483_MY20_Tx" SG_ 854 CC_Diagnostics_Active 1;
BA_ "U_U611_U625_MY20_Hev_Tx" SG_ 854 CC_Diagnostics_Active 1;
BA_ "U_U611_U625_MY20_Gas_Tx" SG_ 854 CC_Diagnostics_Active 1;
BA_ "U_B500_MY18_Diesel_Tx" SG_ 854 CC_Diagnostics_Active 1;
BA_ "U_B500_MY18_Gas_Tx" SG_ 854 CC_Diagnostics_Active 1;
BA_ "U_B562_MY18_Gas_Tx" SG_ 854 CC_Diagnostics_Active 1;
BA_ "U_C519_MY18_5_Gas_Tx" SG_ 854 CC_Diagnostics_Active 1;
BA_ "U_C519_MY18_5_Diesel_Tx" SG_ 854 CC_Diagnostics_Active 1;
BA_ "U_B515_MCA_MY17_Gas_Tx" SG_ 854 CC_Diagnostics_Active 1;
BA_ "U_B515_MCA_MY17_Diesel_Tx" SG_ 854 CC_Diagnostics_Active 1;
BA_ "U_B479_MY17_Diesel_Tx" SG_ 854 CC_Diagnostics_Active 1;
BA_ "U_B479_MY17_Gas_Tx" SG_ 854 CC_Diagnostics_Active 1;
BA_ "GenSigSendType" SG_ 854 CC_Diagnostics_Active 3;
BA_ "CrossOver_InfoCAN" SG_ 854 CC_Diagnostics_Active 1;
BA_ "U_P702_MY2021_Tx" SG_ 854 RHS_Temp_Display_Digit3 1;
BA_ "U_CX727_MY2021_Tx" SG_ 854 RHS_Temp_Display_Digit3 1;
BA_ "U_CX430_MY2021_Tx" SG_ 854 RHS_Temp_Display_Digit3 1;
BA_ "U_U611_U625_MY20_Phev_Tx" SG_ 854 RHS_Temp_Display_Digit3 1;
BA_ "U_CX482_CX483_MY20_Tx" SG_ 854 RHS_Temp_Display_Digit3 1;
BA_ "U_U611_U625_MY20_Hev_Tx" SG_ 854 RHS_Temp_Display_Digit3 1;
BA_ "U_U611_U625_MY20_Gas_Tx" SG_ 854 RHS_Temp_Display_Digit3 1;
BA_ "U_B500_MY18_Diesel_Tx" SG_ 854 RHS_Temp_Display_Digit3 1;
BA_ "U_B500_MY18_Gas_Tx" SG_ 854 RHS_Temp_Display_Digit3 1;
BA_ "U_C519_MY18_5_Gas_Tx" SG_ 854 RHS_Temp_Display_Digit3 1;
BA_ "U_C519_MY18_5_Diesel_Tx" SG_ 854 RHS_Temp_Display_Digit3 1;
BA_ "U_B515_MCA_MY17_Gas_Tx" SG_ 854 RHS_Temp_Display_Digit3 1;
BA_ "U_B515_MCA_MY17_Diesel_Tx" SG_ 854 RHS_Temp_Display_Digit3 1;
BA_ "U_B479_MY17_Diesel_Tx" SG_ 854 RHS_Temp_Display_Digit3 1;
BA_ "U_B479_MY17_Gas_Tx" SG_ 854 RHS_Temp_Display_Digit3 1;
BA_ "GenSigSendType" SG_ 854 RHS_Temp_Display_Digit3 3;
BA_ "CrossOver_InfoCAN" SG_ 854 RHS_Temp_Display_Digit3 1;
BA_ "U_P702_MY2021_Tx" SG_ 854 RHS_Temp_Display_Digit2 1;
BA_ "U_CX727_MY2021_Tx" SG_ 854 RHS_Temp_Display_Digit2 1;
BA_ "U_CX430_MY2021_Tx" SG_ 854 RHS_Temp_Display_Digit2 1;
BA_ "U_U611_U625_MY20_Phev_Tx" SG_ 854 RHS_Temp_Display_Digit2 1;
BA_ "U_CX482_CX483_MY20_Tx" SG_ 854 RHS_Temp_Display_Digit2 1;
BA_ "U_U611_U625_MY20_Hev_Tx" SG_ 854 RHS_Temp_Display_Digit2 1;
BA_ "U_U611_U625_MY20_Gas_Tx" SG_ 854 RHS_Temp_Display_Digit2 1;
BA_ "U_B500_MY18_Diesel_Tx" SG_ 854 RHS_Temp_Display_Digit2 1;
BA_ "U_B500_MY18_Gas_Tx" SG_ 854 RHS_Temp_Display_Digit2 1;
BA_ "U_C519_MY18_5_Gas_Tx" SG_ 854 RHS_Temp_Display_Digit2 1;
BA_ "U_C519_MY18_5_Diesel_Tx" SG_ 854 RHS_Temp_Display_Digit2 1;
BA_ "U_B515_MCA_MY17_Gas_Tx" SG_ 854 RHS_Temp_Display_Digit2 1;
BA_ "U_B515_MCA_MY17_Diesel_Tx" SG_ 854 RHS_Temp_Display_Digit2 1;
BA_ "U_B479_MY17_Diesel_Tx" SG_ 854 RHS_Temp_Display_Digit2 1;
BA_ "U_B479_MY17_Gas_Tx" SG_ 854 RHS_Temp_Display_Digit2 1;
BA_ "GenSigSendType" SG_ 854 RHS_Temp_Display_Digit2 3;
BA_ "CrossOver_InfoCAN" SG_ 854 RHS_Temp_Display_Digit2 1;
BA_ "U_P702_MY2021_Tx" SG_ 854 RHS_Temp_Display_Digit1 1;
BA_ "U_CX727_MY2021_Tx" SG_ 854 RHS_Temp_Display_Digit1 1;
BA_ "U_CX430_MY2021_Tx" SG_ 854 RHS_Temp_Display_Digit1 1;
BA_ "U_U611_U625_MY20_Phev_Tx" SG_ 854 RHS_Temp_Display_Digit1 1;
BA_ "U_CX482_CX483_MY20_Tx" SG_ 854 RHS_Temp_Display_Digit1 1;
BA_ "U_U611_U625_MY20_Hev_Tx" SG_ 854 RHS_Temp_Display_Digit1 1;
BA_ "U_U611_U625_MY20_Gas_Tx" SG_ 854 RHS_Temp_Display_Digit1 1;
BA_ "U_B500_MY18_Diesel_Tx" SG_ 854 RHS_Temp_Display_Digit1 1;
BA_ "U_B500_MY18_Gas_Tx" SG_ 854 RHS_Temp_Display_Digit1 1;
BA_ "U_C519_MY18_5_Gas_Tx" SG_ 854 RHS_Temp_Display_Digit1 1;
BA_ "U_C519_MY18_5_Diesel_Tx" SG_ 854 RHS_Temp_Display_Digit1 1;
BA_ "U_B515_MCA_MY17_Gas_Tx" SG_ 854 RHS_Temp_Display_Digit1 1;
BA_ "U_B515_MCA_MY17_Diesel_Tx" SG_ 854 RHS_Temp_Display_Digit1 1;
BA_ "U_B479_MY17_Diesel_Tx" SG_ 854 RHS_Temp_Display_Digit1 1;
BA_ "U_B479_MY17_Gas_Tx" SG_ 854 RHS_Temp_Display_Digit1 1;
BA_ "GenSigSendType" SG_ 854 RHS_Temp_Display_Digit1 3;
BA_ "CrossOver_InfoCAN" SG_ 854 RHS_Temp_Display_Digit1 1;
BA_ "U_P702_MY2021_Tx" SG_ 854 LHS_Temp_Display_Digit3 1;
BA_ "U_CX727_MY2021_Tx" SG_ 854 LHS_Temp_Display_Digit3 1;
BA_ "U_CX430_MY2021_Tx" SG_ 854 LHS_Temp_Display_Digit3 1;
BA_ "U_U611_U625_MY20_Phev_Tx" SG_ 854 LHS_Temp_Display_Digit3 1;
BA_ "U_B562_MY18_Diesel_Tx" SG_ 854 LHS_Temp_Display_Digit3 1;
BA_ "U_CX482_CX483_MY20_Tx" SG_ 854 LHS_Temp_Display_Digit3 1;
BA_ "U_U611_U625_MY20_Hev_Tx" SG_ 854 LHS_Temp_Display_Digit3 1;
BA_ "U_U611_U625_MY20_Gas_Tx" SG_ 854 LHS_Temp_Display_Digit3 1;
BA_ "U_B500_MY18_Diesel_Tx" SG_ 854 LHS_Temp_Display_Digit3 1;
BA_ "U_B500_MY18_Gas_Tx" SG_ 854 LHS_Temp_Display_Digit3 1;
BA_ "U_B562_MY18_Gas_Tx" SG_ 854 LHS_Temp_Display_Digit3 1;
BA_ "U_C519_MY18_5_Gas_Tx" SG_ 854 LHS_Temp_Display_Digit3 1;
BA_ "U_C519_MY18_5_Diesel_Tx" SG_ 854 LHS_Temp_Display_Digit3 1;
BA_ "U_B515_MCA_MY17_Gas_Tx" SG_ 854 LHS_Temp_Display_Digit3 1;
BA_ "U_B515_MCA_MY17_Diesel_Tx" SG_ 854 LHS_Temp_Display_Digit3 1;
BA_ "U_B479_MY17_Diesel_Tx" SG_ 854 LHS_Temp_Display_Digit3 1;
BA_ "U_B479_MY17_Gas_Tx" SG_ 854 LHS_Temp_Display_Digit3 1;
BA_ "GenSigSendType" SG_ 854 LHS_Temp_Display_Digit3 3;
BA_ "CrossOver_InfoCAN" SG_ 854 LHS_Temp_Display_Digit3 1;
BA_ "U_P702_MY2021_Tx" SG_ 854 LHS_Temp_Display_Digit2 1;
BA_ "U_CX727_MY2021_Tx" SG_ 854 LHS_Temp_Display_Digit2 1;
BA_ "U_CX430_MY2021_Tx" SG_ 854 LHS_Temp_Display_Digit2 1;
BA_ "U_U611_U625_MY20_Phev_Tx" SG_ 854 LHS_Temp_Display_Digit2 1;
BA_ "U_B562_MY18_Diesel_Tx" SG_ 854 LHS_Temp_Display_Digit2 1;
BA_ "U_CX482_CX483_MY20_Tx" SG_ 854 LHS_Temp_Display_Digit2 1;
BA_ "U_U611_U625_MY20_Hev_Tx" SG_ 854 LHS_Temp_Display_Digit2 1;
BA_ "U_U611_U625_MY20_Gas_Tx" SG_ 854 LHS_Temp_Display_Digit2 1;
BA_ "U_B500_MY18_Diesel_Tx" SG_ 854 LHS_Temp_Display_Digit2 1;
BA_ "U_B500_MY18_Gas_Tx" SG_ 854 LHS_Temp_Display_Digit2 1;
BA_ "U_B562_MY18_Gas_Tx" SG_ 854 LHS_Temp_Display_Digit2 1;
BA_ "U_C519_MY18_5_Gas_Tx" SG_ 854 LHS_Temp_Display_Digit2 1;
BA_ "U_C519_MY18_5_Diesel_Tx" SG_ 854 LHS_Temp_Display_Digit2 1;
BA_ "U_B515_MCA_MY17_Gas_Tx" SG_ 854 LHS_Temp_Display_Digit2 1;
BA_ "U_B515_MCA_MY17_Diesel_Tx" SG_ 854 LHS_Temp_Display_Digit2 1;
BA_ "U_B479_MY17_Diesel_Tx" SG_ 854 LHS_Temp_Display_Digit2 1;
BA_ "U_B479_MY17_Gas_Tx" SG_ 854 LHS_Temp_Display_Digit2 1;
BA_ "GenSigSendType" SG_ 854 LHS_Temp_Display_Digit2 3;
BA_ "CrossOver_InfoCAN" SG_ 854 LHS_Temp_Display_Digit2 1;
BA_ "U_P702_MY2021_Tx" SG_ 854 LHS_Temp_Display_Digit1 1;
BA_ "U_CX727_MY2021_Tx" SG_ 854 LHS_Temp_Display_Digit1 1;
BA_ "U_CX430_MY2021_Tx" SG_ 854 LHS_Temp_Display_Digit1 1;
BA_ "U_U611_U625_MY20_Phev_Tx" SG_ 854 LHS_Temp_Display_Digit1 1;
BA_ "U_B562_MY18_Diesel_Tx" SG_ 854 LHS_Temp_Display_Digit1 1;
BA_ "U_CX482_CX483_MY20_Tx" SG_ 854 LHS_Temp_Display_Digit1 1;
BA_ "U_U611_U625_MY20_Hev_Tx" SG_ 854 LHS_Temp_Display_Digit1 1;
BA_ "U_U611_U625_MY20_Gas_Tx" SG_ 854 LHS_Temp_Display_Digit1 1;
BA_ "U_B500_MY18_Diesel_Tx" SG_ 854 LHS_Temp_Display_Digit1 1;
BA_ "U_B500_MY18_Gas_Tx" SG_ 854 LHS_Temp_Display_Digit1 1;
BA_ "U_B562_MY18_Gas_Tx" SG_ 854 LHS_Temp_Display_Digit1 1;
BA_ "U_C519_MY18_5_Gas_Tx" SG_ 854 LHS_Temp_Display_Digit1 1;
BA_ "U_C519_MY18_5_Diesel_Tx" SG_ 854 LHS_Temp_Display_Digit1 1;
BA_ "U_B515_MCA_MY17_Gas_Tx" SG_ 854 LHS_Temp_Display_Digit1 1;
BA_ "U_B515_MCA_MY17_Diesel_Tx" SG_ 854 LHS_Temp_Display_Digit1 1;
BA_ "U_B479_MY17_Diesel_Tx" SG_ 854 LHS_Temp_Display_Digit1 1;
BA_ "U_B479_MY17_Gas_Tx" SG_ 854 LHS_Temp_Display_Digit1 1;
BA_ "GenSigSendType" SG_ 854 LHS_Temp_Display_Digit1 3;
BA_ "CrossOver_InfoCAN" SG_ 854 LHS_Temp_Display_Digit1 1;
BA_ "U_P702_MY2021_Tx" SG_ 854 EATC_RHS_Units 1;
BA_ "U_CX727_MY2021_Tx" SG_ 854 EATC_RHS_Units 1;
BA_ "U_CX430_MY2021_Tx" SG_ 854 EATC_RHS_Units 1;
BA_ "U_U611_U625_MY20_Phev_Tx" SG_ 854 EATC_RHS_Units 1;
BA_ "U_B562_MY18_Diesel_Tx" SG_ 854 EATC_RHS_Units 1;
BA_ "U_CX482_CX483_MY20_Tx" SG_ 854 EATC_RHS_Units 1;
BA_ "U_U611_U625_MY20_Hev_Tx" SG_ 854 EATC_RHS_Units 1;
BA_ "U_U611_U625_MY20_Gas_Tx" SG_ 854 EATC_RHS_Units 1;
BA_ "U_B500_MY18_Diesel_Tx" SG_ 854 EATC_RHS_Units 1;
BA_ "U_B500_MY18_Gas_Tx" SG_ 854 EATC_RHS_Units 1;
BA_ "U_B562_MY18_Gas_Tx" SG_ 854 EATC_RHS_Units 1;
BA_ "U_C519_MY18_5_Gas_Tx" SG_ 854 EATC_RHS_Units 1;
BA_ "U_C519_MY18_5_Diesel_Tx" SG_ 854 EATC_RHS_Units 1;
BA_ "U_B515_MCA_MY17_Gas_Tx" SG_ 854 EATC_RHS_Units 1;
BA_ "U_B515_MCA_MY17_Diesel_Tx" SG_ 854 EATC_RHS_Units 1;
BA_ "U_B479_MY17_Diesel_Tx" SG_ 854 EATC_RHS_Units 1;
BA_ "U_B479_MY17_Gas_Tx" SG_ 854 EATC_RHS_Units 1;
BA_ "GenSigSendType" SG_ 854 EATC_RHS_Units 3;
BA_ "CrossOver_InfoCAN" SG_ 854 EATC_RHS_Units 1;
BA_ "U_P702_MY2021_Tx" SG_ 854 EATC_LHS_Units 1;
BA_ "U_CX727_MY2021_Tx" SG_ 854 EATC_LHS_Units 1;
BA_ "U_CX430_MY2021_Tx" SG_ 854 EATC_LHS_Units 1;
BA_ "U_U611_U625_MY20_Phev_Tx" SG_ 854 EATC_LHS_Units 1;
BA_ "U_B562_MY18_Diesel_Tx" SG_ 854 EATC_LHS_Units 1;
BA_ "U_CX482_CX483_MY20_Tx" SG_ 854 EATC_LHS_Units 1;
BA_ "U_U611_U625_MY20_Hev_Tx" SG_ 854 EATC_LHS_Units 1;
BA_ "U_U611_U625_MY20_Gas_Tx" SG_ 854 EATC_LHS_Units 1;
BA_ "U_B500_MY18_Diesel_Tx" SG_ 854 EATC_LHS_Units 1;
BA_ "U_B500_MY18_Gas_Tx" SG_ 854 EATC_LHS_Units 1;
BA_ "U_B562_MY18_Gas_Tx" SG_ 854 EATC_LHS_Units 1;
BA_ "U_C519_MY18_5_Gas_Tx" SG_ 854 EATC_LHS_Units 1;
BA_ "U_C519_MY18_5_Diesel_Tx" SG_ 854 EATC_LHS_Units 1;
BA_ "U_B515_MCA_MY17_Gas_Tx" SG_ 854 EATC_LHS_Units 1;
BA_ "U_B515_MCA_MY17_Diesel_Tx" SG_ 854 EATC_LHS_Units 1;
BA_ "U_B479_MY17_Diesel_Tx" SG_ 854 EATC_LHS_Units 1;
BA_ "U_B479_MY17_Gas_Tx" SG_ 854 EATC_LHS_Units 1;
BA_ "GenSigSendType" SG_ 854 EATC_LHS_Units 3;
BA_ "CrossOver_InfoCAN" SG_ 854 EATC_LHS_Units 1;
BA_ "U_P702_MY2021_Tx" SG_ 772 SeatScrnDrvOn_B_Rq 1;
BA_ "U_U611_U625_MY20_Phev_Tx" SG_ 772 SeatScrnDrvOn_B_Rq 1;
BA_ "U_CX482_CX483_MY20_Tx" SG_ 772 SeatScrnDrvOn_B_Rq 1;
BA_ "U_U611_U625_MY20_Hev_Tx" SG_ 772 SeatScrnDrvOn_B_Rq 1;
BA_ "U_U611_U625_MY20_Gas_Tx" SG_ 772 SeatScrnDrvOn_B_Rq 1;
BA_ "GenSigSendType" SG_ 772 SeatScrnDrvOn_B_Rq 3;
BA_ "WakeupSignal" SG_ 772 SeatScrnDrvOn_B_Rq 1;
BA_ "U_P702_MY2021_Tx" SG_ 772 MemDrvDeny_B_Stat 1;
BA_ "U_CX727_MY2021_Tx" SG_ 772 MemDrvDeny_B_Stat 1;
BA_ "U_CX430_MY2021_Tx" SG_ 772 MemDrvDeny_B_Stat 1;
BA_ "U_U611_U625_MY20_Phev_Tx" SG_ 772 MemDrvDeny_B_Stat 1;
BA_ "U_CX482_CX483_MY20_Tx" SG_ 772 MemDrvDeny_B_Stat 1;
BA_ "U_U611_U625_MY20_Hev_Tx" SG_ 772 MemDrvDeny_B_Stat 1;
BA_ "U_U611_U625_MY20_Gas_Tx" SG_ 772 MemDrvDeny_B_Stat 1;
BA_ "U_C490_MY18_Tx" SG_ 772 MemDrvDeny_B_Stat 1;
BA_ "GenSigSendType" SG_ 772 MemDrvDeny_B_Stat 3;
BA_ "U_P702_MY2021_Tx" SG_ 772 Memory_Feedback_Rqst 1;
BA_ "U_CX727_MY2021_Tx" SG_ 772 Memory_Feedback_Rqst 1;
BA_ "U_CX430_MY2021_Tx" SG_ 772 Memory_Feedback_Rqst 1;
BA_ "U_U611_U625_MY20_Phev_Tx" SG_ 772 Memory_Feedback_Rqst 1;
BA_ "U_CX482_CX483_MY20_Tx" SG_ 772 Memory_Feedback_Rqst 1;
BA_ "U_U611_U625_MY20_Hev_Tx" SG_ 772 Memory_Feedback_Rqst 1;
BA_ "U_U611_U625_MY20_Gas_Tx" SG_ 772 Memory_Feedback_Rqst 1;
BA_ "U_C490_MY18_Tx" SG_ 772 Memory_Feedback_Rqst 1;
BA_ "U_B479_MY17_Gas_Rx" SG_ 772 Memory_Feedback_Rqst 1;
BA_ "GenSigSendType" SG_ 772 Memory_Feedback_Rqst 3;
BA_ "CrossOver_InfoCAN" SG_ 772 Memory_Feedback_Rqst 1;
BA_ "WakeupSignal" SG_ 772 Memory_Feedback_Rqst 1;
BA_ "U_P702_MY2021_Tx" SG_ 772 Easy_Entry_Rqst 1;
BA_ "U_CX727_MY2021_Tx" SG_ 772 Easy_Entry_Rqst 1;
BA_ "U_CX430_MY2021_Tx" SG_ 772 Easy_Entry_Rqst 1;
BA_ "U_U611_U625_MY20_Phev_Tx" SG_ 772 Easy_Entry_Rqst 1;
BA_ "U_CX482_CX483_MY20_Tx" SG_ 772 Easy_Entry_Rqst 1;
BA_ "U_U611_U625_MY20_Hev_Tx" SG_ 772 Easy_Entry_Rqst 1;
BA_ "U_U611_U625_MY20_Gas_Tx" SG_ 772 Easy_Entry_Rqst 1;
BA_ "U_P702_MY2021_Rx" SG_ 772 Easy_Entry_Rqst 1;
BA_ "U_U611_U625_MY20_Phev_Rx" SG_ 772 Easy_Entry_Rqst 1;
BA_ "U_CX482_CX483_MY20_Rx" SG_ 772 Easy_Entry_Rqst 1;
BA_ "U_U611_U625_MY20_Hev_Rx" SG_ 772 Easy_Entry_Rqst 1;
BA_ "U_U611_U625_MY20_Gas_Rx" SG_ 772 Easy_Entry_Rqst 1;
BA_ "GenSigSendType" SG_ 772 Easy_Entry_Rqst 3;
BA_ "WakeupSignal" SG_ 772 Easy_Entry_Rqst 1;
BA_ "U_P702_MY2021_Tx" SG_ 772 Memory_Cmd 1;
BA_ "U_CX727_MY2021_Tx" SG_ 772 Memory_Cmd 1;
BA_ "U_CX430_MY2021_Tx" SG_ 772 Memory_Cmd 1;
BA_ "U_U611_U625_MY20_Phev_Tx" SG_ 772 Memory_Cmd 1;
BA_ "U_CX482_CX483_MY20_Tx" SG_ 772 Memory_Cmd 1;
BA_ "U_U611_U625_MY20_Hev_Tx" SG_ 772 Memory_Cmd 1;
BA_ "U_U611_U625_MY20_Gas_Tx" SG_ 772 Memory_Cmd 1;
BA_ "U_C490_MY18_Tx" SG_ 772 Memory_Cmd 1;
BA_ "U_CX727_MY2021_Rx" SG_ 772 Memory_Cmd 1;
BA_ "U_CX430_MY2021_Rx" SG_ 772 Memory_Cmd 1;
BA_ "U_C490_MY18_Rx" SG_ 772 Memory_Cmd 1;
BA_ "U_B515_MCA_MY17_Gas_Rx" SG_ 772 Memory_Cmd 1;
BA_ "U_B515_MCA_MY17_Diesel_Rx" SG_ 772 Memory_Cmd 1;
BA_ "U_P702_MY2021_Rx" SG_ 772 Memory_Cmd 1;
BA_ "U_U611_U625_MY20_Phev_Rx" SG_ 772 Memory_Cmd 1;
BA_ "U_CX482_CX483_MY20_Rx" SG_ 772 Memory_Cmd 1;
BA_ "U_U611_U625_MY20_Hev_Rx" SG_ 772 Memory_Cmd 1;
BA_ "U_U611_U625_MY20_Gas_Rx" SG_ 772 Memory_Cmd 1;
BA_ "GenSigSendType" SG_ 772 Memory_Cmd 3;
BA_ "WakeupSignal" SG_ 772 Memory_Cmd 1;
BA_ "U_P702_MY2021_Tx" SG_ 772 Cancel_Auto_Movement 1;
BA_ "U_CX727_MY2021_Tx" SG_ 772 Cancel_Auto_Movement 1;
BA_ "U_CX430_MY2021_Tx" SG_ 772 Cancel_Auto_Movement 1;
BA_ "U_U611_U625_MY20_Phev_Tx" SG_ 772 Cancel_Auto_Movement 1;
BA_ "U_CX482_CX483_MY20_Tx" SG_ 772 Cancel_Auto_Movement 1;
BA_ "U_U611_U625_MY20_Hev_Tx" SG_ 772 Cancel_Auto_Movement 1;
BA_ "U_U611_U625_MY20_Gas_Tx" SG_ 772 Cancel_Auto_Movement 1;
BA_ "U_C490_MY18_Tx" SG_ 772 Cancel_Auto_Movement 1;
BA_ "U_CX727_MY2021_Rx" SG_ 772 Cancel_Auto_Movement 1;
BA_ "U_CX430_MY2021_Rx" SG_ 772 Cancel_Auto_Movement 1;
BA_ "U_C490_MY18_Rx" SG_ 772 Cancel_Auto_Movement 1;
BA_ "U_B515_MCA_MY17_Gas_Rx" SG_ 772 Cancel_Auto_Movement 1;
BA_ "U_B515_MCA_MY17_Diesel_Rx" SG_ 772 Cancel_Auto_Movement 1;
BA_ "U_P702_MY2021_Rx" SG_ 772 Cancel_Auto_Movement 1;
BA_ "U_U611_U625_MY20_Phev_Rx" SG_ 772 Cancel_Auto_Movement 1;
BA_ "U_CX482_CX483_MY20_Rx" SG_ 772 Cancel_Auto_Movement 1;
BA_ "U_U611_U625_MY20_Hev_Rx" SG_ 772 Cancel_Auto_Movement 1;
BA_ "U_U611_U625_MY20_Gas_Rx" SG_ 772 Cancel_Auto_Movement 1;
BA_ "GenSigSendType" SG_ 772 Cancel_Auto_Movement 3;
BA_ "WakeupSignal" SG_ 772 Cancel_Auto_Movement 1;
BA_ "GenSigSendType" SG_ 969 Dimming_Level_Stat 3;
BA_ "GenSigSendType" SG_ 969 Current_Color_Stat 3;
BA_ "GenSigStartValue" SG_ 969 Current_Color_Stat 8;
BA_ "GenSigSendType" SG_ 969 BlendedColorRed_Stat 3;
BA_ "GenSigSendType" SG_ 969 BlendedColorGreen_Stat 3;
BA_ "GenSigSendType" SG_ 969 BlendedColorBlue_Stat 3;
BA_ "GenSigSendType" SG_ 969 BlendedColor_Stat 3;
BA_ "GenSigStartValue" SG_ 969 BlendedColor_Stat 2;
BA_ "U_B479_MY17_Gas_Rx" SG_ 969 TurnLampRrOut_B_Stat 1;
BA_ "GenSigSendType" SG_ 969 TurnLampRrOut_B_Stat 3;
BA_ "ContentDependant" SG_ 969 TurnLampRrOut_B_Stat 1;
BA_ "WakeupSignal" SG_ 969 TurnLampRrOut_B_Stat 1;
BA_ "U_B479_MY17_Gas_Rx" SG_ 969 TurnLampRlOut_B_Stat 1;
BA_ "GenSigSendType" SG_ 969 TurnLampRlOut_B_Stat 3;
BA_ "ContentDependant" SG_ 969 TurnLampRlOut_B_Stat 1;
BA_ "WakeupSignal" SG_ 969 TurnLampRlOut_B_Stat 1;
VAL_ 1066 BattULo_U_Actl_UB 1 "Fresh_data" 0 "Unchanged_data" ;
VAL_ 1066 BattULo_U_Actl 255 "Fault" ;
VAL_ 1066 PwSrcULo_I_Mx 255 "Fault" ;
VAL_ 1066 PwSrcULo_I_Actl 255 "Fault" ;
VAL_ 1066 PwSrcULo_I_Mx_UB 1 "Fresh_data" 0 "Unchanged_data" ;
VAL_ 1066 PwSrcULo_I_Actl_UB 1 "Fresh_data" 0 "Unchanged_data" ;
VAL_ 994 Pers4OptIn_B_Stats 1 "OPTED_IN" 0 "NOT_OPTED_IN" ;
VAL_ 994 Pers3OptIn_B_Stats 1 "OPTED_IN" 0 "NOT_OPTED_IN" ;
VAL_ 994 Pers2OptIn_B_Stats 1 "OPTED_IN" 0 "NOT_OPTED_IN" ;
VAL_ 994 Pers1OptIn_B_Stats 1 "OPTED_IN" 0 "NOT_OPTED_IN" ;
VAL_ 994 CtrStkPersIndex_D_Actl 7 "Unused_3" 6 "Unused_2" 5 "Unused_1" 4 "Vehicle" 3 "PERS_4" 2 "PERS_3" 1 "PERS_2" 0 "PERS_1" ;
VAL_ 994 CtrStkDsplyOp_D_Rq 7 "Unused_2" 6 "Unused_1" 5 "Copy" 4 "Restore" 3 "Upload" 2 "Set" 1 "Query" 0 "Null" ;
VAL_ 994 PersStore_D_Rq 7 "Unused_2" 6 "Unused_1" 5 "Vehicle" 4 "PERS_4" 3 "PERS_3" 2 "PERS_2" 1 "PERS_1" 0 "Null" ;
VAL_ 376 GasPrtc_D_RqDsply 7 "NotUsed_5" 6 "NotUsed_4" 5 "NotUsed_3" 4 "NotUsed_2" 3 "NotUsed_1" 2 "GpfOverLimit" 1 "GpfAtLimit" 0 "NormalOperation" ;
VAL_ 376 AslIconDsply_D_Rq 3 "Not_Used" 2 "On_Active" 1 "On_Passive" 0 "Off" ;
VAL_ 376 AslChime_B_Rq 1 "Yes" 0 "No" ;
VAL_ 376 PtcHtr_D_Cmd 3 "TurnOn" 2 "AutoMode" 1 "TurnOff" 0 "NoDecision_Initializing" ;
VAL_ 376 HvacHtrCore2_Te_Actl 1023 "Faulty" ;
VAL_ 376 AirAmbTe_D_Qf 3 "OK" 2 "Not_Within_Specifications" 1 "No_Data_Exists" 0 "Faulty" ;
VAL_ 376 DynoMde_B_Cmd 1 "Two_Wheel_Dyno" 0 "Normal_Operation" ;
VAL_ 376 AirAmb_P_Actl 63 "Fault" 62 "NoDataExists" ;
VAL_ 1068 HvacAirFullOut_B_Rq_UB 1 "Fresh_data" 0 "Unchanged_data" ;
VAL_ 1068 HvacAirFullOut_B_Rq 1 "Yes" 0 "No" ;
VAL_ 1068 HvacAirFlw_B_RqBatt_UB 1 "Fresh_data" 0 "Unchanged_data" ;
VAL_ 1068 HvacRec_D_RqMxBatt_UB 1 "Fresh_data" 0 "Unchanged_data" ;
VAL_ 1068 HvacRec_D_RqMxBatt 15 "NotUsed5" 14 "NotUsed4" 13 "NotUsed3" 12 "NotUsed2" 11 "NotUsed1" 10 "No_Override" 9 "90Percent_RecircMax" 8 "80Percent_RecircMax" 7 "70Percent_RecircMax" 6 "60Percent_RecircMax" 5 "50Percent_RecircMax" 4 "40Percent_RecircMax" 3 "30Percent_RecircMax" 2 "20Percent_RecircMax" 1 "10Percent_RecircMax" 0 "0Percent_RecircFullOpen" ;
VAL_ 1068 Batt_Lo_SoC_B_UB 1 "Fresh_data" 0 "Unchanged_data" ;
VAL_ 1068 Batt_Lo_SoC_B 1 "Active" 0 "Inactive" ;
VAL_ 1068 Batt_Crit_SoC_B_UB 1 "Fresh_data" 0 "Unchanged_data" ;
VAL_ 1068 Batt_Crit_SoC_B 1 "Active" 0 "Inactive" ;
VAL_ 1068 Shed_T_Eng_Off_B_UB 1 "Fresh_data" 0 "Unchanged_data" ;
VAL_ 1068 Shed_T_Eng_Off_B 1 "Active" 0 "Inactive" ;
VAL_ 1068 Shed_Level_Req_UB 1 "Fresh_data" 0 "Unchanged_data" ;
VAL_ 1068 Shed_Level_Req 7 "Unused_2" 6 "Loads_On" 5 "SHED_ENG_OFF" 4 "SOON_ENG_OFF" 3 "SHED2_CONTIN" 2 "SHED2_TRANS" 1 "SHED1" 0 "NO_SHED" ;
VAL_ 1068 Shed_Feature_Group_ID_UB 1 "Fresh_data" 0 "Unchanged_data" ;
VAL_ 1068 Shed_Feature_Group_ID 16 "PtcHeater" 14 "HtdMirr" 13 "HvacRearBlwr_Third" 12 "HvacRearBlwr_Second" 11 "HvacRearBlwr_First" 31 "All LSHED1 Features" 10 "Htd_Windscrn" 9 "SpltHtdBcklight_HtdMirr" 8 "HtdBcklight_HtdMirr" 7 "HtdCoolSeat_FrtDriver" 6 "HtdCoolSeat_FrtPass" 5 "HtdCoolSeat_RearPass" 4 "HtdCoolSeat_RearDriver" 3 "SmartTrlrTowBattCharge" 2 "Htd_StrWhl" 1 "Htd_Washer_Fluid" 0 "No_LSHED1_Features" 15 "Engine_Coolant_Fan" ;
VAL_ 1068 Shed_Drain_Eng_Off_B_UB 1 "Fresh_data" 0 "Unchanged_data" ;
VAL_ 1068 Shed_Drain_Eng_Off_B 1 "Active" 0 "Inactive" ;
VAL_ 1068 HvacAir_Flw_EstBatt_UB 1 "Fresh_data" 0 "Unchanged_data" ;
VAL_ 1068 AirCondRec_B_Rq_UB 1 "Fresh_data" 0 "Unchanged_data" ;
VAL_ 1068 AirCondFluidHi_P_Actl_UB 1 "Fresh_data" 0 "Unchanged_data" ;
VAL_ 1068 AirCondClutch_B_Stats_UB 1 "Fresh_data" 0 "Unchanged_data" ;
VAL_ 1068 AirCondRec_B_Rq 1 "Yes" 0 "No" ;
VAL_ 1068 AirCondFluidHi_P_Actl 255 "Fault" 254 "Unknown" ;
VAL_ 1068 AirCondClutch_B_Stats 1 "Yes" 0 "No" ;
VAL_ 963 Illuminated_Entry_Stat 3 "Invalid" 2 "Unknown" 1 "On" 0 "Off" ;
VAL_ 963 Dr_Courtesy_Light_Stat 3 "Invalid" 2 "Unknown" 1 "On" 0 "Off" ;
VAL_ 963 ImpactEvntFdbck_D_Stat 3 "NotUsed" 2 "EventComplete" 1 "EventInProgress" 0 "Normal" ;
VAL_ 963 PudLampPsngr_D_Rq 3 "Ramp_Down" 2 "Ramp_Up" 1 "On" 0 "Off" ;
VAL_ 963 HeadLampLoOut_B_Stat 1 "Out" 0 "Null" ;
VAL_ 963 HeadLghtHiFdbck_D_Stat 3 "NotUsed" 2 "Cancel" 1 "Hold" 0 "Allow_Change" ;
VAL_ 963 PrkLightChime_B_Rq 1 "On" 0 "Off" ;
VAL_ 963 TrnNotInPrkChime_B_Rq 1 "On" 0 "Off" ;
VAL_ 963 HomeSafeLtChime_B_Rq 1 "On" 0 "Off" ;
VAL_ 963 StopLghtOn_B_Stat 1 "On" 0 "Off" ;
VAL_ 963 RvrseLghtOn_B_Stat 1 "On" 0 "Off" ;
VAL_ 963 PrkLght_D_Stat 3 "Park_Both" 2 "Park_Right" 1 "Park_Left" 0 "Off" ;
VAL_ 963 HeadLghtSwtch_D_Stat 3 "Autolamp" 2 "Headlamp" 1 "Parklamp" 0 "Off" ;
VAL_ 963 KeyInIgnWarn_B_Cmd 1 "On" 0 "Off" ;
VAL_ 963 HeadLampLoFrOn_B_Stat 1 "Low" 0 "Not_Low" ;
VAL_ 963 HeadLampLoFlOn_B_Stat 1 "Low" 0 "Not_Low" ;
VAL_ 963 Headlamp_On_Wrning_Cmd 1 "On" 0 "Off" ;
VAL_ 963 HeadLampLoActv_B_Stat 1 "On" 0 "Off" ;
VAL_ 963 HeadLghtHiOn_B_Stat 1 "On" 0 "Off" ;
VAL_ 963 Park_Brake_Chime_Rqst 1 "On" 0 "Off" ;
VAL_ 963 BrkWarnInd_B_Rq 1 "On" 0 "Off" ;
VAL_ 963 Brk_Fluid_Lvl_Low 3 "Invalid" 2 "Unknown" 1 "Low" 0 "OK" ;
VAL_ 963 ReducedGuard_D_Stat 3 "NotUsed" 2 "Alarm_On" 1 "Alarm_Off_Previously_On" 0 "Alarm_Off" ;
VAL_ 963 Courtesy_BSave_Stat 3 "Invalid" 2 "Unknown" 1 "No_Effect" 0 "Off" ;
VAL_ 963 DayRnngLampOn_B_Stat 1 "On" 0 "Off" ;
VAL_ 963 PerimeterAlarmChimeRq 1 "On" 0 "Off" ;
VAL_ 963 PudLampDrv_D_Rq 3 "Ramp_Down" 2 "Ramp_Up" 1 "On" 0 "Off" ;
VAL_ 963 Courtesy_Delay_Status 3 "Invalid" 2 "Unknown" 1 "On" 0 "Off" ;
VAL_ 963 Perimeter_Alarm_Status 3 "Activated" 2 "Armed" 1 "Prearmed" 0 "Disarmed" ;
VAL_ 963 WndwGlbl_D_Cmd 7 "NotUsed3" 6 "NotUsed2" 5 "NotUsed1" 4 "GLEARN" 3 "GCLOSE" 2 "GOPEN" 1 "GSTOP" 0 "Null" ;
VAL_ 963 PudLamp_D_Rq 3 "RAMP_DOWN" 2 "RAMP_UP" 1 "ON" 0 "OFF" ;
VAL_ 964 FohEng_D_Rq_UB 1 "Fresh_data" 0 "Unchanged_data" ;
VAL_ 964 EcoMode_B_Stat_UB 1 "Fresh_data" 0 "Unchanged_data" ;
VAL_ 964 Cta_D_Rq_UB 1 "Fresh_data" 0 "Unchanged_data" ;
VAL_ 964 Cta_D_Rq 3 "Unused" 2 "NoDataExists" 1 "On" 0 "Off" ;
VAL_ 964 GearRvrse_D_Actl_UB 1 "Fresh_data" 0 "Unchanged_data" ;
VAL_ 964 GearRvrse_D_Actl 7 "Fault" 6 "NotUsed_3" 5 "NotUsed_2" 4 "NotUsed_1" 3 "Active_confirmed" 2 "Active_not_confirmed" 1 "Inactive_confirmed" 0 "Inactive_not_confirmed" ;
VAL_ 964 TurnLghtSwtch_D_Stat_UB 1 "Fresh_data" 0 "Unchanged_data" ;
VAL_ 964 TurnLghtSwtch_D_Stat 3 "Unused_Treat_As_Off" 2 "Right" 1 "Left" 0 "Off" ;
VAL_ 964 Power_Liftgate_Mode_Cmd_UB 1 "Fresh_data" 0 "Unchanged_data" ;
VAL_ 964 Power_Liftgate_Mode_Cmd 1 "Enable" 0 "Disable" ;
VAL_ 964 MetricActvTe_B_Actl_UB 1 "Fresh_data" 0 "Unchanged_data" ;
VAL_ 964 MetricActvTe_B_Actl 1 "Active" 0 "Inactive" ;
VAL_ 964 EngClntTe_D_Qf 3 "OK" 2 "Not_Within_Specifications" 1 "No_Data_Exists" 0 "Faulty" ;
VAL_ 964 Sod_D_Rq 2 "BLIS_On_Second_Warning_ON" 1 "BLIS_On_Second_Warning_OFF" 0 "Off" ;
VAL_ 964 MetricActv_B_Actl 1 "Active" 0 "Inactive" ;
VAL_ 964 MetricActv_B_Actl_UB 1 "Fresh_data" 0 "Unchanged_data" ;
VAL_ 964 EngClnt_Te_Actl_UB 1 "Fresh_data" 0 "Unchanged_data" ;
VAL_ 964 OCSSensrDataUpperLim_UB 1 "Fresh_data" 0 "Unchanged_data" ;
VAL_ 964 OCSSensrDataUpperLim 255 "Invalid" ;
VAL_ 964 OCSSensrDataLowerLim_UB 1 "Fresh_data" 0 "Unchanged_data" ;
VAL_ 964 PrkAid_D_Falt 7 "NotUsed2" 6 "NotUsed1" 5 "Failure_Front_PSM_Sensors" 4 "No_Data_Exists" 3 "Failure_Rear_Sensors" 2 "Speaker_Fault" 1 "ECU_Fault" 0 "No_Fault" ;
VAL_ 964 OCSSensrDataLowerLim 255 "Invalid" ;
VAL_ 964 PrkAid_D_Falt_UB 1 "Fresh_data" 0 "Unchanged_data" ;
VAL_ 964 WiprFront_D_Stat_UB 1 "Fresh_data" 0 "Unchanged_data" ;
VAL_ 964 WiprFront_D_Stat 15 "NO_DATA_EXISTS" 14 "STALLED" 13 "RESERVED" 12 "AUTO_ADJUST" 11 "COURTESYWIPE" 10 "AUTO_HIGH" 9 "AUTO_LOW" 8 "WASH" 7 "MIST_FLICK" 6 "MAN_HIGH" 5 "MAN_LOW" 4 "MAN_INT_ON" 3 "MAN_INT_OFF" 2 "OFF_MOVING" 1 "AUTO_OFF" 0 "OFF" ;
VAL_ 964 CamraDefog_B_Req_UB 1 "Fresh_data" 0 "Unchanged_data" ;
VAL_ 964 Sod_D_Rq_UB 1 "Fresh_data" 0 "Unchanged_data" ;
VAL_ 964 CamraDefog_B_Req 1 "On" 0 "Off" ;
VAL_ 993 EmButtn_D_Stat 7 "ButtonAssociationFailed" 6 "ButtonAssociationExited" 5 "ButtonAssociationEntered" 4 "Button4Pressed" 3 "Button3Pressed" 2 "Button2Pressed" 1 "Button1Pressed" 0 "Null" ;
VAL_ 993 PersStore_D_Actl 3 "Unused" 2 "Null" 1 "InProgress" 0 "Complete" ;
VAL_ 993 MemSwtch_D_RqRecall 7 "Unused_3" 6 "Unused_2" 5 "Unused_1" 4 "PERS_4" 3 "PERS_3" 2 "PERS_2" 1 "PERS_1" 0 "Null" ;
VAL_ 993 MemSwtch_D_RqAssoc 7 "Unused_3" 6 "Unused_2" 5 "Unused_1" 4 "PERS_4" 3 "PERS_3" 2 "PERS_2" 1 "PERS_1" 0 "Null" ;
VAL_ 993 PersIndexDsm_D_Actl 7 "Unused_3" 6 "Unused_2" 5 "Unused_1" 4 "Vehicle" 3 "PERS_4" 2 "PERS_3" 1 "PERS_2" 0 "PERS_1" ;
VAL_ 320 PwSldDrIntSwL_B_Stat 1 "Pressed" 0 "Null" ;
VAL_ 320 LPwrSlideDr_Unlock_Rq 1 "Unlock" 0 "Null" ;
VAL_ 313 PwSldDrIntSwR_B_Stat 1 "Pressed" 0 "Null" ;
VAL_ 313 RPwrSlideDr_Unlock_Rq 1 "Unlock" 0 "Null" ;
VAL_ 806 SnowPlowMde_B_Enbl 1 "Enable" 0 "Disable" ;
VAL_ 806 ClimtHeat_D_Rq 7 "NotUsed4" 6 "NotUsed3" 5 "NotUsed2" 4 "PtcHtrTestMde" 3 "Defrost_Defog" 2 "FastTempPullDownHeatingReq" 1 "OpportunisticHeatingReq" 0 "NoHeatingRequest" ;
VAL_ 806 ClimtCool_D_Rq 7 "NotUsed4" 6 "NotUsed3" 5 "NotUsed2" 4 "ElACTestMde" 3 "Defrost_Defog" 2 "FastTempPullDownCoolReq" 1 "OpportunisticCoolingReq" 0 "NoCoolingRequest" ;
VAL_ 806 HvacEvap_Te_Actl 1023 "Fault" ;
VAL_ 806 HvacAirCond_B_Rq 1 "Yes" 0 "No" ;
VAL_ 950 Modulation_Ctrl 3 "Unused" 2 "FSK" 1 "ASK_FSK" 0 "ASK" ;
VAL_ 950 TirePress_Filter_Ctrl 3 "Streaming" 2 "Filter" 1 "Not_Used" 0 "Null" ;
VAL_ 857 LHS_Temp_Disp_Digit3 2 "_5" 1 "_0" 0 "OFF" ;
VAL_ 857 Front_Blower_Ind 15 "Display_Blank" 14 "14_Indicators_On" 13 "13_Indicators_On" 12 "12_Indicators_On" 11 "11_Indicators_On" 10 "10_Indicators_On" 9 "9_Indicators_On" 8 "8_Indicators_On" 7 "7_Indicators_On" 6 "6_Indicators_On" 5 "5_Indicators_On" 4 "4_Indicators_On" 3 "3_Indicators_On" 2 "2_Indicators_On" 1 "1_Indicator_On" 0 "Indicators_Off" ;
VAL_ 857 EATC_LHS_Unit 2 "Fahrenheit" 1 "Celsius" 0 "Off" ;
VAL_ 856 ClimtRearView_D_Stat 3 "ThirdRow" 2 "SecondRow" 1 "Both" 0 "NotDisplayed" ;
VAL_ 856 Rr_Btn_Status_2nd 31 "NotUsed_7" 30 "NotUsed_6" 29 "NotUsed_5" 28 "NotUsed_4" 27 "NotUsed_3" 26 "NotUsed_2" 25 "NotUsed_1" 24 "Third_Sync_Pressed" 23 "Third_Rr_Pwr_Pressed" 22 "Third_Auto_Pressed" 21 "Third_Pnl_Flr_Pressed" 20 "Third_Floor_Pressed" 19 "Third_Panel_Pressed" 18 "Third_Blwr_Dec_Pressed" 17 "Third_Blwr_Inc_Pressed" 16 "Rear_Lock_Pressed" 15 "RHS_Cld_Seat_Pressed" 14 "LHS_Cld_Seat_Pressed" 13 "RHS_Htd_Seat_Pressed" 12 "LHS_Htd_Seat_Pressed" 11 "Rear_Power_Pressed" 10 "AUTO_Pressed" 9 "Blwr_Dec_Pressed" 8 "Blwr_Inc_Pressed" 7 "RHS_Temp_Dec_Pressed" 6 "RHS_Temp_Inc_Pressed" 5 "LHS_Temp_Dec_Pressed" 4 "LHS_Temp_Inc_Pressed" 3 "Floor_Pressed" 2 "Panel_Floor_Pressed" 1 "Panel_Pressed" 0 "None_Pressed" ;
VAL_ 856 Rr_Btn_Status_1st 31 "NotUsed_7" 30 "NotUsed_6" 29 "NotUsed_5" 28 "NotUsed_4" 27 "NotUsed_3" 26 "NotUsed_2" 25 "NotUsed_1" 24 "Third_Sync_Pressed" 23 "Third_Rr_Pwr_Pressed" 22 "Third_Auto_Pressed" 21 "Third_Pnl_Flr_Pressed" 20 "Third_Floor_Pressed" 19 "Third_Panel_Pressed" 18 "Third_Blwr_Dec_Pressed" 17 "Third_Blwr_Inc_Pressed" 16 "Rear_Lock_Pressed" 15 "RHS_Cld_Seat_Pressed" 14 "LHS_Cld_Seat_Pressed" 13 "RHS_Htd_Seat_Pressed" 12 "LHS_Htd_Seat_Pressed" 11 "Rear_Power_Pressed" 10 "AUTO_Pressed" 9 "Blwr_Dec_Pressed" 8 "Blwr_Inc_Pressed" 7 "RHS_Temp_Dec_Pressed" 6 "RHS_Temp_Inc_Pressed" 5 "LHS_Temp_Dec_Pressed" 4 "LHS_Temp_Inc_Pressed" 3 "Floor_Pressed" 2 "Panel_Floor_Pressed" 1 "Panel_Pressed" 0 "None_Pressed" ;
VAL_ 856 Frt_Btn_Status_2nd 36 "MdeMnu_Pressed" 35 "AAR_Pressed" 34 "Heat_Pressed" 33 "RearMnu_Pressed" 32 "FrontMnu_Pressed" 31 "Defrost_Pressed" 30 "Htg_Strg_Whl_Pressed" 29 "RHS_Cld_Seat_Pressed" 28 "LHS_Cld_Seat_Pressed" 27 "RHS_Htd_Seat_Pressed" 26 "LHS_Htd_Seat_Pressed" 25 "Max_Defrost_Pressed" 24 "My_Temp_Pressed" 23 "Front_Power_Pressed" 22 "Rear_Defrost_Pressed" 21 "Pnl_Flr_Ws_Pressed" 20 "Pnl_Ws_Pressed" 19 "Windscreen_Pressed" 18 "Htd_Frt_Wsh_Pressed" 17 "Auto_Recirc_Pressed" 16 "Outside_Pressed" 15 "Recirc_Pressed" 14 "Max_AC_Pressed" 13 "AUTO_Pressed" 12 "Blwr_Dec_Pressed" 11 "Blwr_Inc_Pressed" 10 "RHS_Temp_Dec_Pressed" 9 "RHS_Temp_Inc_Pressed" 8 "LHS_Temp_Dec_Pressed" 7 "LHS_Temp_Inc_Pressed" 6 "Dual_Pressed" 5 "AC_Pressed" 4 "Floor_Ws_Pressed" 3 "Floor_Pressed" 2 "Panel_Floor_Pressed" 1 "Panel_Pressed" 0 "None_Pressed" ;
VAL_ 856 Frt_Btn_Status_1st 36 "MdeMnu_Pressed" 35 "AAR_Pressed" 34 "Heat_Pressed" 33 "RearMnu_Pressed" 32 "FrontMnu_Pressed" 31 "Defrost_Pressed" 30 "Htg_Strg_Whl_Pressed" 29 "RHS_Cld_Seat_Pressed" 28 "LHS_Cld_Seat_Pressed" 27 "RHS_Htd_Seat_Pressed" 26 "LHS_Htd_Seat_Pressed" 25 "Max_Defrost_Pressed" 24 "My_Temp_Pressed" 23 "Front_Power_Pressed" 22 "Rear_Defrost_Pressed" 21 "Pnl_Flr_Ws_Pressed" 20 "Pnl_Ws_Pressed" 19 "Windscreen_Pressed" 18 "Htd_Frt_Wsh_Pressed" 17 "Auto_Recirc_Pressed" 16 "Outside_Pressed" 15 "Recirc_Pressed" 14 "Max_AC_Pressed" 13 "AUTO_Pressed" 12 "Blwr_Dec_Pressed" 11 "Blwr_Inc_Pressed" 10 "RHS_Temp_Dec_Pressed" 9 "RHS_Temp_Inc_Pressed" 8 "LHS_Temp_Dec_Pressed" 7 "LHS_Temp_Inc_Pressed" 6 "Dual_Pressed" 5 "AC_Pressed" 4 "Floor_Ws_Pressed" 3 "Floor_Pressed" 2 "Panel_Floor_Pressed" 1 "Panel_Pressed" 0 "None_Pressed" ;
VAL_ 856 Frt_Blower_Speed 3 "NotUsed" 2 "Max_Blower" 1 "Min_Blower" 0 "No_Request" ;
VAL_ 856 Drv_Set_Temp 31 "HI" 30 "29_5" 29 "29_0" 28 "28_5" 27 "28_0" 26 "27_5" 25 "27_0" 24 "26_5" 23 "26_0" 22 "25_5" 21 "25_0" 20 "24_5" 19 "24_0" 18 "23_5" 17 "23_0" 16 "22_5" 15 "22_0" 14 "21_5" 13 "21_0" 12 "20_5" 11 "20_0" 10 "19_5" 9 "19_0" 8 "18_5" 7 "18_0" 6 "17_5" 5 "17_0" 4 "16_5" 3 "16_0" 2 "15_5" 1 "LO" 0 "No_Request" ;
VAL_ 854 CC_Fr_Stat_User_Adj 7 "Unused4" 6 "Unused3" 5 "Unused2" 4 "Unused1" 3 "Fr_Blwr_Spd_Selection" 2 "FRHS_SetPt_Selection" 1 "FLHS_SetPt_Selection" 0 "None" ;
VAL_ 854 Front_Blower_Indicate 15 "Display_Blank" 14 "14_Indicators_On" 13 "13_Indicators_On" 12 "12_Indicators_On" 11 "11_Indicators_On" 10 "10_Indicators_On" 9 "9_Indicators_On" 8 "8_Indicators_On" 7 "7_Indicators_On" 6 "6_Indicators_On" 5 "5_Indicators_On" 4 "4_Indicators_On" 3 "3_Indicators_On" 2 "2_Indicators_On" 1 "1_Indicator_On" 0 "Indicators_Off" ;
VAL_ 854 CC_Diagnostics_Active 1 "Yes" 0 "No" ;
VAL_ 854 RHS_Temp_Display_Digit3 2 "_5" 1 "_0" 0 "OFF" ;
VAL_ 854 LHS_Temp_Display_Digit3 2 "_5" 1 "_0" 0 "OFF" ;
VAL_ 854 EATC_RHS_Units 2 "Fahrenheit" 1 "Celsius" 0 "Off" ;
VAL_ 854 EATC_LHS_Units 2 "Fahrenheit" 1 "Celsius" 0 "Off" ;
VAL_ 772 SeatScrnDrvOn_B_Rq 1 "On" 0 "Off" ;
VAL_ 772 MemDrvDeny_B_Stat 1 "Yes" 0 "No" ;
VAL_ 772 Memory_Feedback_Rqst 1 "Yes" 0 "No" ;
VAL_ 772 Easy_Entry_Rqst 2 "Easy_Entry" 1 "Drive" 0 "Null" ;
VAL_ 772 Memory_Cmd 7 "Recall_3" 4 "Store_4" 3 "Store_3" 6 "Recall_2" 5 "Recall_1" 2 "Store_2" 1 "Store_1" 0 "Null" 8 "Recall_4" ;
VAL_ 772 Cancel_Auto_Movement 1 "Cancel" 0 "Null" ;
VAL_ 969 Dimming_Level_Stat 3 "Low" 2 "Not_Used" 1 "High" 0 "Null" ;
VAL_ 969 Current_Color_Stat 15 "NotUsed7" 14 "NotUsed6" 13 "NotUsed5" 12 "NotUsed4" 11 "NotUsed3" 10 "NotUsed2" 9 "NotUsed1" 8 "Null" 7 "Color7" 6 "Color6" 5 "Color5" 4 "Color4" 3 "Color3" 2 "Color2" 1 "Color1" 0 "Off" ;
VAL_ 969 BlendedColorRed_Stat 15 "NotUsed10" 14 "NotUsed9" 13 "NotUsed8" 12 "NotUsed7" 11 "NotUsed6" 10 "NotUsed5" 9 "NotUsed4" 8 "NotUsed3" 7 "NotUsed2" 6 "NotUsed1" 5 "_5" 4 "_4" 3 "_3" 2 "_2" 1 "_1" 0 "Null" ;
VAL_ 969 BlendedColorGreen_Stat 15 "NotUsed10" 14 "NotUsed9" 13 "NotUsed8" 12 "NotUsed7" 11 "NotUsed6" 10 "NotUsed5" 9 "NotUsed4" 8 "NotUsed3" 7 "NotUsed2" 6 "NotUsed1" 5 "_5" 4 "_4" 3 "_3" 2 "_2" 1 "_1" 0 "Null" ;
VAL_ 969 BlendedColorBlue_Stat 15 "NotUsed10" 14 "NotUsed9" 13 "NotUsed8" 12 "NotUsed7" 11 "NotUsed6" 10 "NotUsed5" 9 "NotUsed4" 8 "NotUsed3" 7 "NotUsed2" 6 "NotUsed1" 5 "_5" 4 "_4" 3 "_3" 2 "_2" 1 "_1" 0 "Null" ;
VAL_ 969 BlendedColor_Stat 3 "NotUsed" 2 "Null" 1 "On" 0 "Off" ;
VAL_ 969 TurnLampRrOut_B_Stat 1 "Out" 0 "Null" ;
VAL_ 969 TurnLampRlOut_B_Stat 1 "Out" 0 "Null" ;
